VERSION ""

NS_ :

BS_:

BU_: ATCM_DMSM HCM_HS2 PAM_HS2 GSM GWM _delete SCCM OCS TSTR RCM

BO_ 2611175451 PARSEDPhysGSMtoGWM_ECG: 8 Vector__XXX
 SG_ PARSEDPhysGSMtoGWM_ECG : 7|29@0+ (1,0) [0|536870911] "Unitless"  GWM

BO_ 1844 TesterPhysicalReqHCM_HS2: 8 TSTR
 SG_ TesterPhysicalReqHCM : 7|64@0+ (1,0) [0|1.84467E+019] "unitless"  HCM_HS2

BO_ 1852 TesterPhysicalResHCM_HS2: 8 HCM_HS2
 SG_ TesterPhysicalResHCM : 7|64@0+ (1,0) [0|1.84467E+019] "unitless"  TSTR

BO_ 989 Personality_HCM_Data_HS2: 8 HCM_HS2
 SG_ FeatNoHcm_No_Actl : 23|16@0+ (1,0) [0|65535] "Number"  GWM
 SG_ FeatConfigHcmActl : 7|16@0+ (1,0) [0|65535] "Undefined"  GWM

BO_ 2612002008 PARSEDFuncGWM_ECG_HS2: 8 GWM
 SG_ PARSEDFuncGWM_ECG : 7|29@0+ (1,0) [0|536870911] "unitless" Vector__XXX

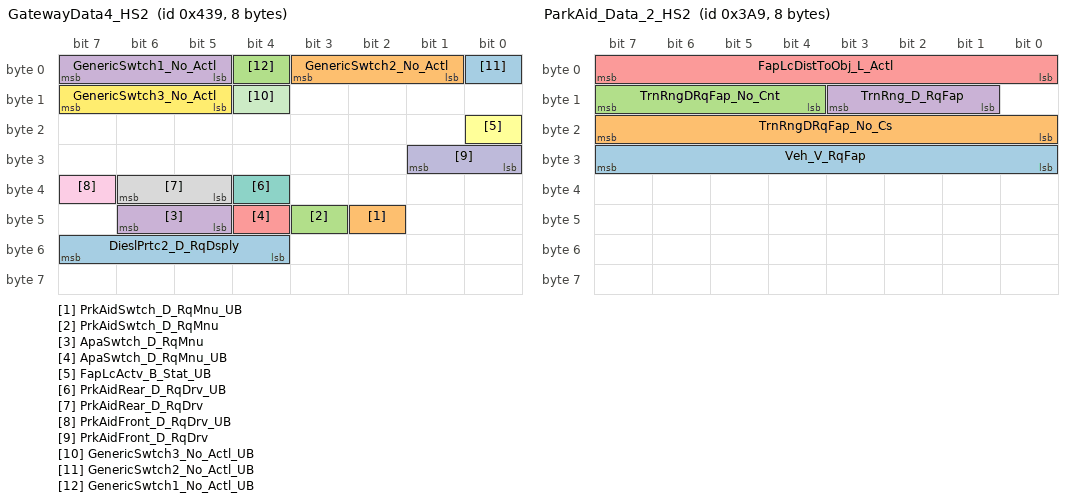
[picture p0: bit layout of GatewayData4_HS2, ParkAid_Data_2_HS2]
BO_ 1081 GatewayData4_HS2: 8 GWM
 SG_ DieslPrtc2_D_RqDsply : 55|4@0+ (1,0) [0|15] "SED" Vector__XXX
 SG_ PrkAidSwtch_D_RqMnu_UB : 42|1@0+ (1,0) [0|1] "SED"  PAM_HS2
 SG_ PrkAidSwtch_D_RqMnu : 43|1@0+ (1,0) [0|1] "SED"  PAM_HS2
 SG_ ApaSwtch_D_RqMnu : 46|2@0+ (1,0) [0|3] "SED" Vector__XXX
 SG_ ApaSwtch_D_RqMnu_UB : 44|1@0+ (1,0) [0|1] "SED" Vector__XXX
 SG_ FapLcActv_B_Stat_UB : 16|1@0+ (1,0) [0|1] "SED"  PAM_HS2
 SG_ PrkAidRear_D_RqDrv_UB : 36|1@0+ (1,0) [0|1] "SED"  PAM_HS2
 SG_ PrkAidRear_D_RqDrv : 38|2@0+ (1,0) [0|3] "SED"  PAM_HS2
 SG_ PrkAidFront_D_RqDrv_UB : 39|1@0+ (1,0) [0|1] "SED" Vector__XXX
 SG_ PrkAidFront_D_RqDrv : 25|2@0+ (1,0) [0|3] "SED" Vector__XXX
 SG_ GenericSwtch3_No_Actl_UB : 12|1@0+ (1,0) [0|1] "SED" Vector__XXX
 SG_ GenericSwtch3_No_Actl : 15|3@0+ (1,0) [0|7] "unitless" Vector__XXX
 SG_ GenericSwtch2_No_Actl_UB : 0|1@0+ (1,0) [0|1] "SED" Vector__XXX
 SG_ GenericSwtch2_No_Actl : 3|3@0+ (1,0) [0|7] "unitless" Vector__XXX
 SG_ GenericSwtch1_No_Actl_UB : 4|1@0+ (1,0) [0|1] "SED" Vector__XXX
 SG_ GenericSwtch1_No_Actl : 7|3@0+ (1,0) [0|7] "unitless" Vector__XXX

BO_ 937 ParkAid_Data_2_HS2: 8 PAM_HS2
 SG_ Veh_V_RqFap : 31|8@0+ (0.1,0) [0|25.5] "km/h"  GWM
 SG_ TrnRngDRqFap_No_Cs : 23|8@0+ (1,0) [0|255] "unitless"  GWM
 SG_ TrnRngDRqFap_No_Cnt : 15|4@0+ (1,0) [0|15] "unitless"  GWM
 SG_ TrnRng_D_RqFap : 11|3@0+ (1,0) [0|7] "SED"  GWM
 SG_ FapLcDistToObj_L_Actl : 7|8@0+ (0.01,0) [0|2.53] "meter"  GWM

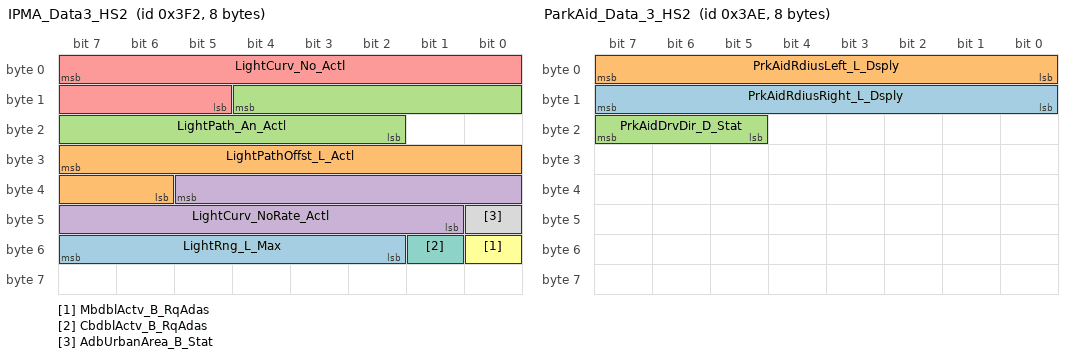
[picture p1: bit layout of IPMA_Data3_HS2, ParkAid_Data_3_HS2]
BO_ 1010 IPMA_Data3_HS2: 8 GWM
 SG_ LightRng_L_Max : 55|6@0+ (2,0) [0|126] "meter"  GWM,HCM_HS2
 SG_ LightPathOffst_L_Actl : 31|10@0+ (0.01,-5.12) [-5.12|5.11] "meter"  GWM,HCM_HS2
 SG_ LightPath_An_Actl : 12|11@0+ (0.0005,-0.5) [-0.5|0.5235] "radians"  GWM,HCM_HS2
 SG_ LightCurv_NoRate_Actl : 37|13@0+ (2.5E-007,-0.001024) [-0.001024|0.00102375] "1/meter"  GWM,HCM_HS2
 SG_ LightCurv_No_Actl : 7|11@0+ (2E-005,-0.02) [-0.02|0.02094] "1/meter"  GWM,HCM_HS2
 SG_ MbdblActv_B_RqAdas : 48|1@0+ (1,0) [0|1] "SED" Vector__XXX
 SG_ CbdblActv_B_RqAdas : 49|1@0+ (1,0) [0|1] "SED"  GWM,HCM_HS2
 SG_ AdbUrbanArea_B_Stat : 40|1@0+ (1,0) [0|1] "SED"  GWM,HCM_HS2

BO_ 2612224027 PARSEDPushGSMtoGWM_ECG: 8 Vector__XXX
 SG_ PARSEDPushGSMtoGWM_ECG : 7|29@0+ (1,0) [0|536870911] "unitless"  GWM

BO_ 2610953432 OTAFuncGWM_ECG_HS2: 8 GWM
 SG_ OTAFuncGWM_ECG : 7|29@0+ (1,0) [0|536870911] "unitless"  HCM_HS2,GSM

BO_ 2609933528 OTAPhysGWM_ECGtoGSM: 8 GWM
 SG_ OTAPhysGWM_ECGtoGSM : 7|29@0+ (1,0) [0|536870911] "unitless"  GSM

BO_ 2610126875 OTAPhysGSMtoGWM_ECG: 8 GSM
 SG_ OTAPhysGSMtoGWM_ECG : 7|29@0+ (1,0) [0|536870911] "unitless"  GWM

BO_ 1854 TesterPhysicalResPAM_HS2: 8 PAM_HS2
 SG_ TesterPhysicalResPAM : 7|64@0+ (1,0) [0|1.84467E+019] "unitless"  TSTR

BO_ 942 ParkAid_Data_3_HS2: 8 PAM_HS2
 SG_ PrkAidRdiusRight_L_Dsply : 15|8@0+ (1,0) [0|255] "unitless"  GWM
 SG_ PrkAidRdiusLeft_L_Dsply : 7|8@0+ (1,0) [0|255] "unitless"  GWM
 SG_ PrkAidDrvDir_D_Stat : 23|3@0+ (1,0) [0|7] "SED"  GWM

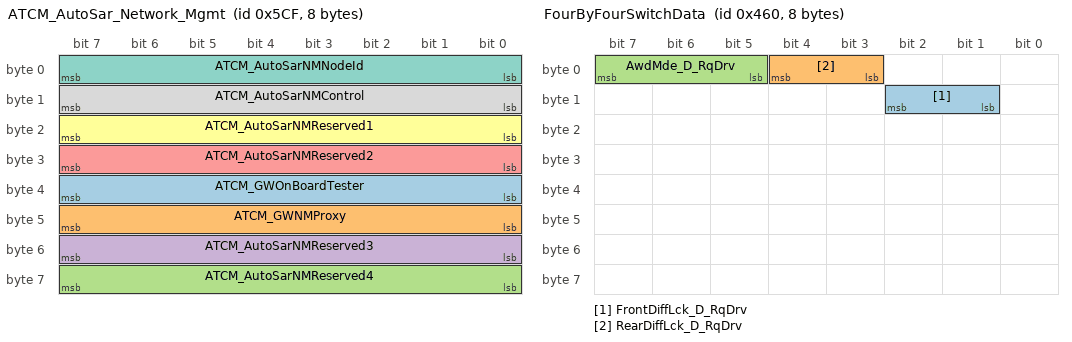
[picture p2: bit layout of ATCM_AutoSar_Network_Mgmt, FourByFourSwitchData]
BO_ 1487 ATCM_AutoSar_Network_Mgmt: 8 ATCM_DMSM
 SG_ ATCM_GWOnBoardTester : 39|8@0+ (1,0) [0|255] "unitless"  GWM
 SG_ ATCM_GWNMProxy : 47|8@0+ (1,0) [0|255] "unitless"  GWM
 SG_ ATCM_AutoSarNMReserved4 : 63|8@0+ (1,0) [0|255] "unitless"  GWM
 SG_ ATCM_AutoSarNMReserved3 : 55|8@0+ (1,0) [0|255] "unitless"  GWM
 SG_ ATCM_AutoSarNMReserved2 : 31|8@0+ (1,0) [0|255] "unitless"  GWM
 SG_ ATCM_AutoSarNMReserved1 : 23|8@0+ (1,0) [0|255] "unitless"  GWM
 SG_ ATCM_AutoSarNMNodeId : 7|8@0+ (1,0) [0|255] "unitless"  GWM
 SG_ ATCM_AutoSarNMControl : 15|8@0+ (1,0) [0|255] "unitless"  GWM

BO_ 1120 FourByFourSwitchData: 8 ATCM_DMSM
 SG_ FrontDiffLck_D_RqDrv : 10|2@0+ (1,0) [0|3] "SED"  GWM
 SG_ RearDiffLck_D_RqDrv : 4|2@0+ (1,0) [0|3] "SED"  GWM
 SG_ AwdMde_D_RqDrv : 7|3@0+ (1,0) [0|7] "SED"  GWM

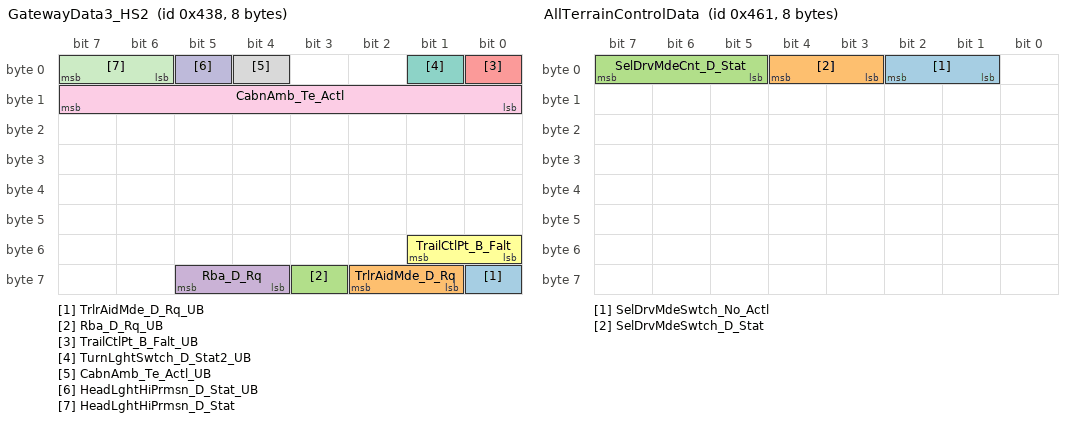
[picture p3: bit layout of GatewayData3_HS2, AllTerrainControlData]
BO_ 1080 GatewayData3_HS2: 8 GWM
 SG_ TrlrAidMde_D_Rq_UB : 56|1@0+ (1,0) [0|1] "SED" Vector__XXX
 SG_ TrlrAidMde_D_Rq : 58|2@0+ (1,0) [0|3] "SED" Vector__XXX
 SG_ Rba_D_Rq_UB : 59|1@0+ (1,0) [0|1] "SED" Vector__XXX
 SG_ Rba_D_Rq : 61|2@0+ (1,0) [0|3] "SED" Vector__XXX
 SG_ TrailCtlPt_B_Falt_UB : 0|1@0+ (1,0) [0|1] "SED" Vector__XXX
 SG_ TrailCtlPt_B_Falt : 49|2@0+ (1,0) [0|3] "SED" Vector__XXX
 SG_ TurnLghtSwtch_D_Stat2_UB : 1|1@0+ (1,0) [0|1] "SED" Vector__XXX
 SG_ CabnAmb_Te_Actl_UB : 4|1@0+ (1,0) [0|1] "SED"  SCCM
 SG_ CabnAmb_Te_Actl : 15|8@0+ (0.5,-57) [-57|70] "degreesC"  SCCM
 SG_ HeadLghtHiPrmsn_D_Stat_UB : 5|1@0+ (1,0) [0|1] "SED"  HCM_HS2,SCCM
 SG_ HeadLghtHiPrmsn_D_Stat : 7|2@0+ (1,0) [0|3] "SED"  HCM_HS2,SCCM

BO_ 1121 AllTerrainControlData: 8 ATCM_DMSM
 SG_ SelDrvMdeSwtch_No_Actl : 2|2@0+ (1,0) [0|3] "unitless"  GWM
 SG_ SelDrvMdeSwtch_D_Stat : 4|2@0+ (1,0) [0|3] "SED"  GWM
 SG_ SelDrvMdeCnt_D_Stat : 7|3@0+ (1,0) [0|7] "Counts"  GWM

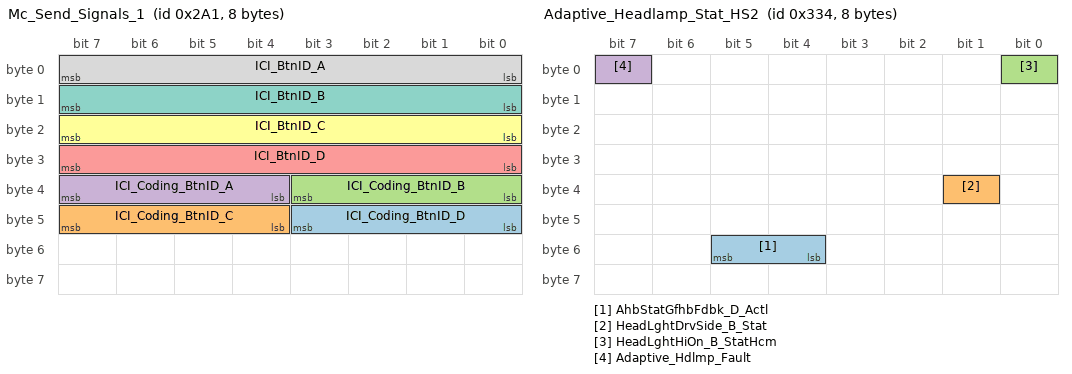
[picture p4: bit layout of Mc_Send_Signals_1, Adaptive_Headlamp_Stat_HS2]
BO_ 673 Mc_Send_Signals_1: 8 SCCM
 SG_ ICI_Coding_BtnID_D : 43|4@0+ (1,0) [0|15] "SED"  GWM
 SG_ ICI_Coding_BtnID_C : 47|4@0+ (1,0) [0|15] "SED"  GWM
 SG_ ICI_Coding_BtnID_B : 35|4@0+ (1,0) [0|15] "SED"  GWM
 SG_ ICI_Coding_BtnID_A : 39|4@0+ (1,0) [0|15] "SED"  GWM
 SG_ ICI_BtnID_D : 31|8@0+ (1,0) [0|255] "unitless"  GWM
 SG_ ICI_BtnID_C : 23|8@0+ (1,0) [0|255] "unitless"  GWM
 SG_ ICI_BtnID_B : 15|8@0+ (1,0) [0|255] "unitless"  GWM
 SG_ ICI_BtnID_A : 7|8@0+ (1,0) [0|255] "unitless"  GWM

BO_ 820 Adaptive_Headlamp_Stat_HS2: 8 HCM_HS2
 SG_ AhbStatGfhbFdbk_D_Actl : 53|2@0+ (1,0) [0|3] "SED"  GWM,SCCM
 SG_ HeadLghtDrvSide_B_Stat : 33|1@0+ (1,0) [0|1] "SED"  GWM
 SG_ HeadLghtHiOn_B_StatHcm : 0|1@0+ (1,0) [0|1] "SED"  GWM
 SG_ Adaptive_Hdlmp_Fault : 7|1@0+ (1,0) [0|1] "SED"  GWM

BO_ 1073 BodyEngGateway_2_HS2: 8 GWM
 SG_ CamraFrntBttn_D_Stat : 48|1@0+ (1,0) [0|1] "SED" Vector__XXX
 SG_ CamraFrntBttn_D_Stat_UB : 60|1@0+ (1,0) [0|1] "SED" Vector__XXX
 SG_ BrkDrvMde_D_Rq_UB : 49|1@0+ (1,0) [0|1] "SED" Vector__XXX
 SG_ BrkDrvMde_D_Rq : 63|3@0+ (1,0) [0|7] "SED" Vector__XXX
 SG_ SteEffort_D_Rq : 52|3@0+ (1,0) [0|7] "SED" Vector__XXX
 SG_ AutoHoldSwtch_D_Stat_UB : 57|1@0+ (1,0) [0|1] "SED" Vector__XXX
 SG_ AutoHoldSwtch_D_Stat : 59|2@0+ (1,0) [0|3] "SED" Vector__XXX
 SG_ HMI_HMIMode_St_UB : 41|1@0+ (1,0) [0|1] "SED"  SCCM
 SG_ HMI_HMIMode_St : 55|3@0+ (1,0) [0|7] "SED"  SCCM
 SG_ Veh_Lock_Requestor_UB : 47|1@0+ (1,0) [0|1] "SED"  GSM
 SG_ Veh_Lock_EvNum_UB : 32|1@0+ (1,0) [0|1] "SED"  GSM
 SG_ Veh_Lock_Sub_Id_UB : 33|1@0+ (1,0) [0|1] "SED" Vector__XXX
 SG_ Tire_Press_System_Stat_UB : 34|1@0+ (1,0) [0|1] "SED" Vector__XXX
 SG_ Veh_Lock_Status_UB : 8|1@0+ (1,0) [0|1] "SED"  GSM
 SG_ Veh_Lock_Sub_Id : 19|4@0+ (1,0) [0|15] "SED" Vector__XXX
 SG_ Veh_Lock_Status : 10|2@0+ (1,0) [0|3] "SED"  GSM
 SG_ Veh_Lock_Requestor : 39|5@0+ (1,0) [0|31] "SED"  GSM
 SG_ Veh_Lock_EvNum : 31|8@0+ (1,0) [0|255] "unitless"  GSM
 SG_ Tire_Press_System_Stat : 23|4@0+ (1,0) [0|15] "SED" Vector__XXX
 SG_ DISPLAY_SPEED_OFFSET_UB : 0|1@0+ (1,0) [0|1] "SED" Vector__XXX
 SG_ DISPLAY_SPEED_OFFSET : 3|3@0+ (0.5,0) [0|3.5] "kph" Vector__XXX
 SG_ DISPLAY_SPEED_SCALING_UB : 11|1@0+ (1,0) [0|1] "SED" Vector__XXX
 SG_ DISPLAY_SPEED_SCALING : 15|4@0+ (0.5,100) [100|107.5] "%" Vector__XXX
 SG_ SteWhlHeat_D_Rq_UB : 42|1@0+ (1,0) [0|1] "SED"  SCCM
 SG_ SteWhlHeat_D_Rq : 46|4@0+ (1,0) [0|15] "SED"  SCCM

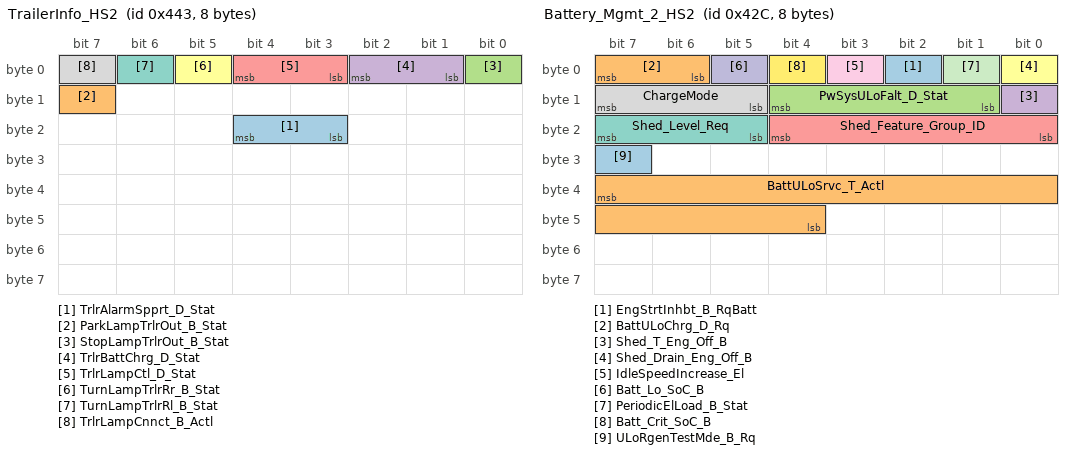
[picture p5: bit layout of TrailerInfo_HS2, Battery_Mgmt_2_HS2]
BO_ 1091 TrailerInfo_HS2: 8 GWM
 SG_ TrlrAlarmSpprt_D_Stat : 20|2@0+ (1,0) [0|3] "SED" Vector__XXX
 SG_ ParkLampTrlrOut_B_Stat : 15|1@0+ (1,0) [0|1] "SED" Vector__XXX
 SG_ StopLampTrlrOut_B_Stat : 0|1@0+ (1,0) [0|1] "SED" Vector__XXX
 SG_ TrlrBattChrg_D_Stat : 2|2@0+ (1,0) [0|3] "SED" Vector__XXX
 SG_ TrlrLampCtl_D_Stat : 4|2@0+ (1,0) [0|3] "SED" Vector__XXX
 SG_ TurnLampTrlrRr_B_Stat : 5|1@0+ (1,0) [0|1] "SED" Vector__XXX
 SG_ TurnLampTrlrRl_B_Stat : 6|1@0+ (1,0) [0|1] "SED" Vector__XXX
 SG_ TrlrLampCnnct_B_Actl : 7|1@0+ (1,0) [0|1] "SED"  SCCM,PAM_HS2

BO_ 1068 Battery_Mgmt_2_HS2: 8 GWM
 SG_ EngStrtInhbt_B_RqBatt : 2|1@0+ (1,0) [0|1] "SED" Vector__XXX
 SG_ BattULoChrg_D_Rq : 7|2@0+ (1,0) [0|3] "SED" Vector__XXX
 SG_ PwSysULoFalt_D_Stat : 12|4@0+ (1,0) [0|15] "SED" Vector__XXX
 SG_ Shed_T_Eng_Off_B : 8|1@0+ (1,0) [0|1] "SED"  SCCM
 SG_ Shed_Feature_Group_ID : 20|5@0+ (1,0) [0|31] "SED"  SCCM,PAM_HS2
 SG_ Shed_Drain_Eng_Off_B : 0|1@0+ (1,0) [0|1] "SED"  SCCM
 SG_ Shed_Level_Req : 23|3@0+ (1,0) [0|7] "SED"  PAM_HS2,GSM,SCCM
 SG_ ChargeMode : 15|3@0+ (1,0) [0|7] "SED" Vector__XXX
 SG_ IdleSpeedIncrease_El : 3|1@0+ (1,0) [0|1] "SED" Vector__XXX
 SG_ Batt_Lo_SoC_B : 5|1@0+ (1,0) [0|1] "SED" Vector__XXX
 SG_ PeriodicElLoad_B_Stat : 1|1@0+ (1,0) [0|1] "SED" Vector__XXX
 SG_ Batt_Crit_SoC_B : 4|1@0+ (1,0) [0|1] "SED"  GSM
 SG_ ULoRgenTestMde_B_Rq : 31|1@0+ (1,0) [0|1] "SED" Vector__XXX
 SG_ BattULoSrvc_T_Actl : 39|12@0+ (1,0) [0|4095] "days" Vector__XXX

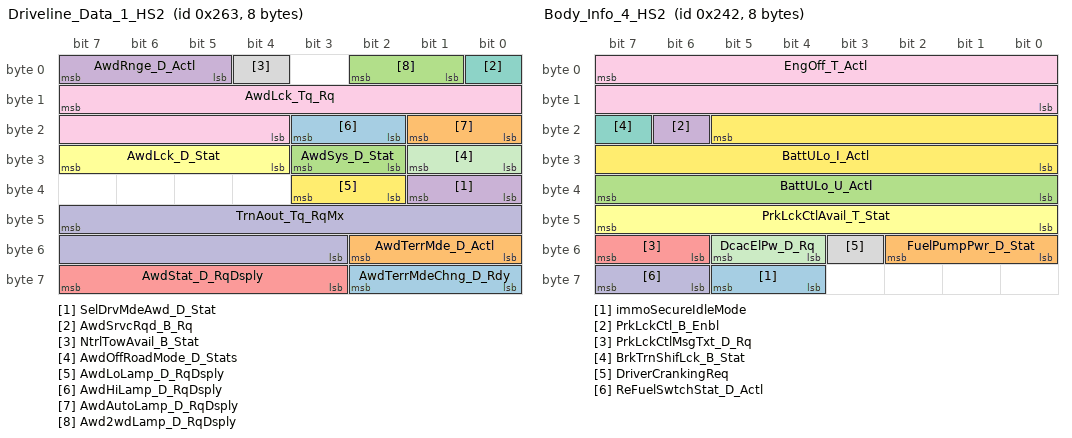
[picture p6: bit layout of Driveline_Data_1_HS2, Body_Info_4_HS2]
BO_ 611 Driveline_Data_1_HS2: 8 GWM
 SG_ AwdTerrMdeChng_D_Rdy : 58|3@0+ (1,0) [0|7] "SED" Vector__XXX
 SG_ AwdTerrMde_D_Actl : 50|3@0+ (1,0) [0|7] "SED" Vector__XXX
 SG_ AwdSys_D_Stat : 27|2@0+ (1,0) [0|3] "SED" Vector__XXX
 SG_ SelDrvMdeAwd_D_Stat : 33|2@0+ (1,0) [0|3] "SED" Vector__XXX
 SG_ AwdStat_D_RqDsply : 63|5@0+ (1,0) [0|31] "SED" Vector__XXX
 SG_ AwdLck_D_Stat : 31|4@0+ (1,0) [0|15] "SED" Vector__XXX
 SG_ AwdSrvcRqd_B_Rq : 0|1@0+ (1,0) [0|1] "SED"  RCM
 SG_ NtrlTowAvail_B_Stat : 4|1@0+ (1,0) [0|1] "SED" Vector__XXX
 SG_ AwdLck_Tq_Rq : 15|12@0+ (1,0) [0|4093] "Nm" Vector__XXX
 SG_ TrnAout_Tq_RqMx : 47|13@0+ (1,-1250) [-1250|6941] "Nm" Vector__XXX
 SG_ AwdOffRoadMode_D_Stats : 25|2@0+ (1,0) [0|3] "SED" Vector__XXX
 SG_ AwdLoLamp_D_RqDsply : 35|2@0+ (1,0) [0|3] "SED"  ATCM_DMSM
 SG_ AwdHiLamp_D_RqDsply : 19|2@0+ (1,0) [0|3] "SED"  ATCM_DMSM
 SG_ AwdAutoLamp_D_RqDsply : 17|2@0+ (1,0) [0|3] "SED"  ATCM_DMSM
 SG_ Awd2wdLamp_D_RqDsply : 2|2@0+ (1,0) [0|3] "SED"  ATCM_DMSM
 SG_ AwdRnge_D_Actl : 7|3@0+ (1,0) [0|7] "SED" Vector__XXX

BO_ 578 Body_Info_4_HS2: 8 GWM
 SG_ immoSecureIdleMode : 61|2@0+ (1,0) [0|3] "SED"  GSM
 SG_ FuelPumpPwr_D_Stat : 50|3@0+ (1,0) [0|7] "SED" Vector__XXX
 SG_ BattULo_U_Actl : 39|8@0+ (0.0625,0) [0|15.875] "volt" Vector__XXX
 SG_ PrkLckCtl_B_Enbl : 22|1@0+ (1,0) [0|1] "SED"  GSM
 SG_ PrkLckCtlMsgTxt_D_Rq : 55|2@0+ (1,0) [0|3] "SED" Vector__XXX
 SG_ PrkLckCtlAvail_T_Stat : 47|8@0+ (1,0) [0|255] "second" Vector__XXX
 SG_ BrkTrnShifLck_B_Stat : 23|1@0+ (1,0) [0|1] "SED"  GSM
 SG_ DriverCrankingReq : 51|1@0+ (1,0) [0|1] "SED"  GSM
 SG_ EngOff_T_Actl : 7|16@0+ (1,0) [0|65534] "second^0.5" Vector__XXX
 SG_ ReFuelSwtchStat_D_Actl : 63|2@0+ (1,0) [0|3] "SED" Vector__XXX
 SG_ DcacElPw_D_Rq : 53|2@0+ (1,0) [0|3] "SED" Vector__XXX
 SG_ BattULo_I_Actl : 21|14@0+ (0.0625,-512) [-512|511.875] "ampere" Vector__XXX

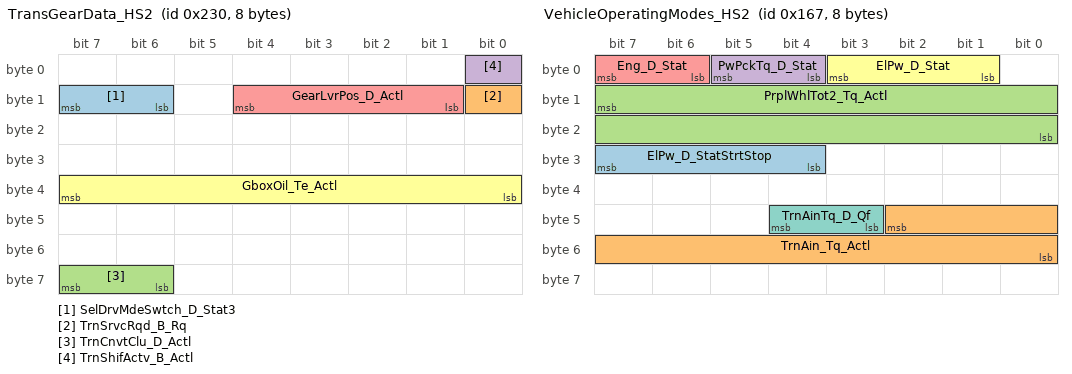
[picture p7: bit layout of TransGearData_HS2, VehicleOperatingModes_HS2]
BO_ 560 TransGearData_HS2: 8 GWM
 SG_ SelDrvMdeSwtch_D_Stat3 : 15|2@0+ (1,0) [0|3] "SED" Vector__XXX
 SG_ TrnSrvcRqd_B_Rq : 8|1@0+ (1,0) [0|1] "SED"  RCM
 SG_ TrnCnvtClu_D_Actl : 63|2@0+ (1,0) [0|3] "SED" Vector__XXX
 SG_ TrnShifActv_B_Actl : 0|1@0+ (1,0) [0|1] "SED" Vector__XXX
 SG_ GearLvrPos_D_Actl : 12|4@0+ (1,0) [0|15] "SED"  HCM_HS2,SCCM,RCM,GSM
 SG_ GboxOil_Te_Actl : 39|8@0+ (1,-60) [-60|193] "degC" Vector__XXX

BO_ 359 VehicleOperatingModes_HS2: 8 GWM
 SG_ ElPw_D_StatStrtStop : 31|4@0+ (1,0) [0|15] "SED"  GSM,SCCM
 SG_ TrnAin_Tq_Actl : 42|11@0+ (1,-500) [-500|1547] "Nm" Vector__XXX
 SG_ PrplWhlTot2_Tq_Actl : 15|16@0+ (4,-131072) [-131072|131060] "Nm"  RCM
 SG_ PwPckTq_D_Stat : 5|2@0+ (1,0) [0|3] "SED"  HCM_HS2,PAM_HS2,SCCM,OCS,GSM
 SG_ Eng_D_Stat : 7|2@0+ (1,0) [0|3] "SED" Vector__XXX
 SG_ ElPw_D_Stat : 3|3@0+ (1,0) [0|7] "SED"  HCM_HS2,PAM_HS2,GSM,OCS,SCCM
 SG_ TrnAinTq_D_Qf : 44|2@0+ (1,0) [0|3] "SED" Vector__XXX

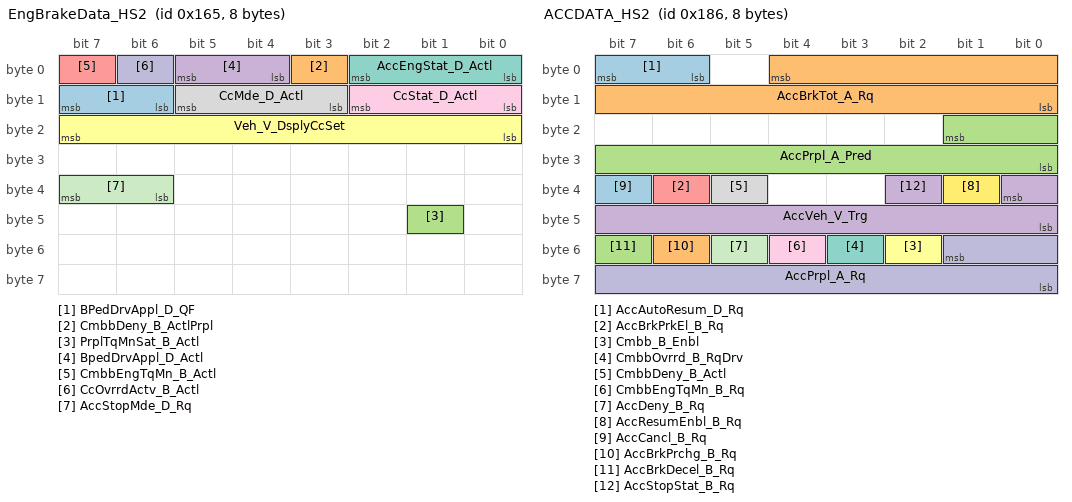
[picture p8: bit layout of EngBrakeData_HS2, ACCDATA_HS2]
BO_ 357 EngBrakeData_HS2: 8 GWM
 SG_ BPedDrvAppl_D_QF : 15|2@0+ (1,0) [0|3] "SED"  OCS,GSM,RCM
 SG_ CmbbDeny_B_ActlPrpl : 3|1@0+ (1,0) [0|1] "SED" Vector__XXX
 SG_ PrplTqMnSat_B_Actl : 41|1@0+ (1,0) [0|1] "SED" Vector__XXX
 SG_ BpedDrvAppl_D_Actl : 5|2@0+ (1,0) [0|3] "SED"  OCS,GSM,RCM
 SG_ CmbbEngTqMn_B_Actl : 7|1@0+ (1,0) [0|1] "SED" Vector__XXX
 SG_ Veh_V_DsplyCcSet : 23|8@0+ (1,0) [0|253] "Unitless" Vector__XXX
 SG_ AccEngStat_D_Actl : 2|3@0+ (1,0) [0|7] "SED" Vector__XXX
 SG_ CcMde_D_Actl : 13|3@0+ (1,0) [0|7] "SED" Vector__XXX
 SG_ CcStat_D_Actl : 10|3@0+ (1,0) [0|7] "SED"  OCS,RCM
 SG_ CcOvrrdActv_B_Actl : 6|1@0+ (1,0) [0|1] "SED"  RCM
 SG_ AccStopMde_D_Rq : 39|2@0+ (1,0) [0|3] "SED" Vector__XXX

BO_ 390 ACCDATA_HS2: 8 GWM
 SG_ AccAutoResum_D_Rq : 7|2@0+ (1,0) [0|3] "SED"  GWM
 SG_ AccBrkTot_A_Rq : 4|13@0+ (0.0039,-20) [-20|11.9449] "m/s^2"  GWM
 SG_ AccPrpl_A_Pred : 17|10@0+ (0.01,-5) [-5|5.23] "m/s^2"  GWM
 SG_ AccVeh_V_Trg : 32|9@0+ (0.5,0) [0|255.5] "kph"  GWM
 SG_ AccBrkPrkEl_B_Rq : 38|1@0+ (1,0) [0|1] "SED"  GWM
 SG_ Cmbb_B_Enbl : 50|1@0+ (1,0) [0|1] "SED"  GWM,RCM
 SG_ CmbbOvrrd_B_RqDrv : 51|1@0+ (1,0) [0|1] "SED"  GWM,RCM
 SG_ CmbbDeny_B_Actl : 37|1@0+ (1,0) [0|1] "SED"  GWM,RCM
 SG_ CmbbEngTqMn_B_Rq : 52|1@0+ (1,0) [0|1] "SED"  GWM
 SG_ AccPrpl_A_Rq : 49|10@0+ (0.01,-5) [-5|5.23] "m/s^2"  GWM
 SG_ AccDeny_B_Rq : 53|1@0+ (1,0) [0|1] "SED"  GWM
 SG_ AccResumEnbl_B_Rq : 33|1@0+ (1,0) [0|1] "SED"  GWM
 SG_ AccCancl_B_Rq : 39|1@0+ (1,0) [0|1] "SED"  GWM
 SG_ AccBrkPrchg_B_Rq : 54|1@0+ (1,0) [0|1] "SED"  GWM
 SG_ AccBrkDecel_B_Rq : 55|1@0+ (1,0) [0|1] "SED"  GWM
 SG_ AccStopStat_B_Rq : 34|1@0+ (1,0) [0|1] "SED"  GWM

BO_ 1071 Engine_Clutch_Data_HS2: 8 GWM
 SG_ CluPdlPosPcMeas_D_Qf : 11|2@0+ (1,0) [0|3] "SED"  HCM_HS2
 SG_ CluPdlPos_Pc_Meas : 9|10@0+ (0.1,0) [0|102.3] "%"  HCM_HS2

BO_ 1072 Cluster_Info1_HS2: 8 GWM
 SG_ HdcOn_B_Rq_UB : 55|1@0+ (1,0) [0|1] "SED" Vector__XXX
 SG_ TrlrAidCancl_B_Rq_UB : 56|1@0+ (1,0) [0|1] "SED" Vector__XXX
 SG_ TrlrAidCancl_B_Rq : 57|1@0+ (1,0) [0|1] "SED" Vector__XXX
 SG_ HdcOn_B_Rq : 39|1@0+ (1,0) [0|1] "SED" Vector__XXX
 SG_ HsaMde_D_Rq : 51|2@0+ (1,0) [0|3] "SED" Vector__XXX
 SG_ HsaMde_D_Rq_UB : 49|1@0+ (1,0) [0|1] "SED" Vector__XXX
 SG_ LscmbbStat_B_Actl : 53|1@0+ (1,0) [0|1] "SED" Vector__XXX
 SG_ LscmbbStat_B_Actl_UB : 52|1@0+ (1,0) [0|1] "SED" Vector__XXX
 SG_ Outside_Air_Temp_Stat_UB : 3|1@0+ (1,0) [0|1] "SED"  PAM_HS2
 SG_ Outside_Air_Temp_Stat : 47|8@0+ (0.5,-40) [-40|86.5] "Degrees C"  PAM_HS2
 SG_ BulbChkActv_B_Stat_UB : 5|1@0+ (1,0) [0|1] "SED" Vector__XXX
 SG_ BulbChkActv_B_Stat : 6|1@0+ (1,0) [0|1] "SED" Vector__XXX
 SG_ Fda_B_Stat_UB : 4|1@0+ (1,0) [0|1] "SED" Vector__XXX
 SG_ AccEnbl_B_RqDrv_UB : 2|1@0+ (1,0) [0|1] "SED" Vector__XXX
 SG_ AccDeny_B_RqIpc_UB : 1|1@0+ (1,0) [0|1] "SED" Vector__XXX
 SG_ OdometerMasterValue_UB : 0|1@0+ (1,0) [0|1] "SED" Vector__XXX
 SG_ OdometerMasterValue : 15|24@0+ (1,0) [0|16777214] "km"  RCM
 SG_ Fda_B_Stat : 36|1@0+ (1,0) [0|1] "SED" Vector__XXX
 SG_ AccDeny_B_RqIpc : 7|1@0+ (1,0) [0|1] "SED" Vector__XXX
 SG_ AccEnbl_B_RqDrv : 35|1@0+ (1,0) [0|1] "SED" Vector__XXX
 SG_ DrvSlipCtlMde_D_Rq_UB : 38|1@0+ (1,0) [0|1] "SED" Vector__XXX
 SG_ DrvSlipCtlMde_D_Rq : 33|2@0+ (1,0) [0|3] "SED" Vector__XXX
 SG_ DrvSlipCtlMde_B_Rq_UB : 37|1@0+ (1,0) [0|1] "SED" Vector__XXX
 SG_ ePRNDL_MODE_UB : 48|1@0+ (1,0) [0|1] "SED"  GSM
 SG_ ePRNDL_MODE : 54|1@0+ (1,0) [0|1] "SED"  GSM
 SG_ TrlrBrkMde_D_Rq : 63|1@0+ (1,0) [0|1] "SED" Vector__XXX
 SG_ TRLR_SWAY_CONFIG_CMD : 62|1@0+ (1,0) [0|1] "SED" Vector__XXX
 SG_ TRAILER_BRAKE_CONFIG : 61|1@0+ (1,0) [0|1] "SED" Vector__XXX
 SG_ TrlrBrkMde_D_Rq_UB : 60|1@0+ (1,0) [0|1] "SED" Vector__XXX
 SG_ TRAILER_BRAKE_CONFIG_UB : 58|1@0+ (1,0) [0|1] "SED" Vector__XXX

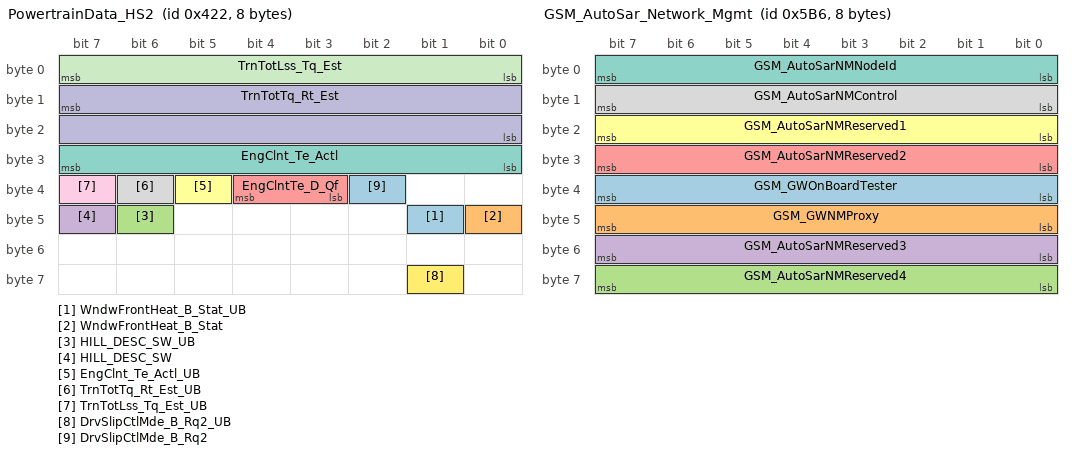
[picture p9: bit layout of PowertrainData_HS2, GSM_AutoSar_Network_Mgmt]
BO_ 1058 PowertrainData_HS2: 8 GWM
 SG_ WndwFrontHeat_B_Stat_UB : 41|1@0+ (1,0) [0|1] "SED" Vector__XXX
 SG_ WndwFrontHeat_B_Stat : 40|1@0+ (1,0) [0|1] "SED" Vector__XXX
 SG_ HILL_DESC_SW_UB : 46|1@0+ (1,0) [0|1] "SED" Vector__XXX
 SG_ HILL_DESC_SW : 47|1@0+ (1,0) [0|1] "SED" Vector__XXX
 SG_ EngClntTe_D_Qf : 36|2@0+ (1,0) [0|3] "SED" Vector__XXX
 SG_ EngClnt_Te_Actl_UB : 37|1@0+ (1,0) [0|1] "SED" Vector__XXX
 SG_ EngClnt_Te_Actl : 31|8@0+ (1,-60) [-60|195] "degC"  GSM
 SG_ TrnTotTq_Rt_Est_UB : 38|1@0+ (1,0) [0|1] "SED" Vector__XXX
 SG_ TrnTotLss_Tq_Est_UB : 39|1@0+ (1,0) [0|1] "SED" Vector__XXX
 SG_ TrnTotTq_Rt_Est : 15|16@0+ (0.001,0) [0|65.533] "Unitless" Vector__XXX
 SG_ TrnTotLss_Tq_Est : 7|8@0+ (0.5,0) [0|126.5] "Nm" Vector__XXX
 SG_ DrvSlipCtlMde_B_Rq2_UB : 57|1@0+ (1,0) [0|1] "SED" Vector__XXX
 SG_ DrvSlipCtlMde_B_Rq2 : 34|1@0+ (1,0) [0|1] "SED" Vector__XXX

BO_ 1082 GatewayData_HS2: 8 GWM
 SG_ EsaOn_B_Rq_UB : 33|1@0+ (1,0) [0|1] "SED" Vector__XXX
 SG_ EsaOn_B_Rq : 34|1@0+ (1,0) [0|1] "SED" Vector__XXX
 SG_ RearDiffLck_D_RqArb_UB : 35|1@0+ (1,0) [0|1] "SED" Vector__XXX
 SG_ RearDiffLck_D_RqArb : 25|2@0+ (1,0) [0|3] "SED" Vector__XXX
 SG_ AwdMde_D_RqArb_UB : 36|1@0+ (1,0) [0|1] "SED" Vector__XXX
 SG_ AwdMde_D_RqArb : 39|3@0+ (1,0) [0|7] "SED" Vector__XXX
 SG_ SelDrvMdeTxtReset_B_Rq_UB : 43|1@0+ (1,0) [0|1] "SED" Vector__XXX
 SG_ SelDrvMdeTxtReset_B_Rq : 44|1@0+ (1,0) [0|1] "SED" Vector__XXX
 SG_ SelDrvMdeDsply_B_Avail_UB : 50|1@0+ (1,0) [0|1] "SED" Vector__XXX
 SG_ AirSusp_D_RqDrv_UB : 16|1@0+ (1,0) [0|1] "SED" Vector__XXX
 SG_ DrvInputRequired_B_Rq_UB : 52|1@0+ (1,0) [0|1] "SED"  SCCM
 SG_ DrvInputRequired_B_Rq : 32|1@0+ (1,0) [0|1] "SED"  SCCM
 SG_ SelDrvMdeSwtch_D_Stat2_UB : 45|1@0+ (1,0) [0|1] "SED" Vector__XXX
 SG_ SelDrvMdeSwtch_D_Stat2 : 47|2@0+ (1,0) [0|3] "SED" Vector__XXX
 SG_ FapLcStopHold_B_Rq : 57|1@0+ (1,0) [0|1] "SED" Vector__XXX
 SG_ SelDrvMdeDsply_B_Avail : 51|1@0+ (1,0) [0|1] "SED" Vector__XXX
 SG_ FapLcStopHold_B_Rq_UB : 56|1@0+ (1,0) [0|1] "SED" Vector__XXX
 SG_ FapLcPrchgBrk_B_Rq_UB : 58|1@0+ (1,0) [0|1] "SED" Vector__XXX
 SG_ AirSusp_D_RqDrv : 31|2@0+ (1,0) [0|3] "SED" Vector__XXX
 SG_ AwdRnge_D_ActlIpc_UB : 26|1@0+ (1,0) [0|1] "SED" Vector__XXX
 SG_ AwdRnge_D_ActlIpc : 29|3@0+ (1,0) [0|7] "SED" Vector__XXX
 SG_ NtrlTowMdeEnbl_B_RqDrv_UB : 60|1@0+ (1,0) [0|1] "SED" Vector__XXX
 SG_ NtrlTowMdeEnbl_B_RqDrv : 48|1@0+ (1,0) [0|1] "SED" Vector__XXX
 SG_ DrvSlipCtlMde_B_RqMyKey_UB : 17|1@0+ (1,0) [0|1] "SED" Vector__XXX
 SG_ DrvSlipCtlMde_B_RqMyKey : 18|1@0+ (1,0) [0|1] "SED" Vector__XXX
 SG_ AwdDrvMde_D_Rq_UB : 49|1@0+ (1,0) [0|1] "SED" Vector__XXX
 SG_ AwdDrvMde_D_Rq : 63|3@0+ (1,0) [0|7] "SED" Vector__XXX
 SG_ MetricActv_B_Actl_UB : 53|1@0+ (1,0) [0|1] "SED" Vector__XXX
 SG_ MetricActv_B_Actl : 54|1@0+ (1,0) [0|1] "SED" Vector__XXX
 SG_ BrkLineLck_D_Rq_UB : 5|1@0+ (1,0) [0|1] "SED" Vector__XXX
 SG_ BrkLineLck_D_Rq : 7|2@0+ (1,0) [0|3] "SED" Vector__XXX
 SG_ SuspDrvMde_D_Rq_UB : 19|1@0+ (1,0) [0|1] "SED" Vector__XXX
 SG_ SuspDrvMde_D_Rq : 22|3@0+ (1,0) [0|7] "SED" Vector__XXX
 SG_ SelDrvMdePt_D_Stat_UB : 55|1@0+ (1,0) [0|1] "SED" Vector__XXX
 SG_ SelDrvMdePt_D_Stat : 41|2@0+ (1,0) [0|3] "SED" Vector__XXX

BO_ 1462 GSM_AutoSar_Network_Mgmt: 8 GSM
 SG_ GSM_GWOnBoardTester : 39|8@0+ (1,0) [0|255] "unitless"  SCCM,GWM
 SG_ GSM_GWNMProxy : 47|8@0+ (1,0) [0|255] "unitless"  SCCM,GWM
 SG_ GSM_AutoSarNMReserved4 : 63|8@0+ (1,0) [0|255] "unitless"  SCCM,GWM
 SG_ GSM_AutoSarNMReserved3 : 55|8@0+ (1,0) [0|255] "unitless"  SCCM,GWM
 SG_ GSM_AutoSarNMReserved2 : 31|8@0+ (1,0) [0|255] "unitless"  SCCM,GWM
 SG_ GSM_AutoSarNMReserved1 : 23|8@0+ (1,0) [0|255] "unitless"  SCCM,GWM
 SG_ GSM_AutoSarNMNodeId : 7|8@0+ (1,0) [0|255] "unitless"  SCCM,GWM
 SG_ GSM_AutoSarNMControl : 15|8@0+ (1,0) [0|255] "unitless"  SCCM,GWM

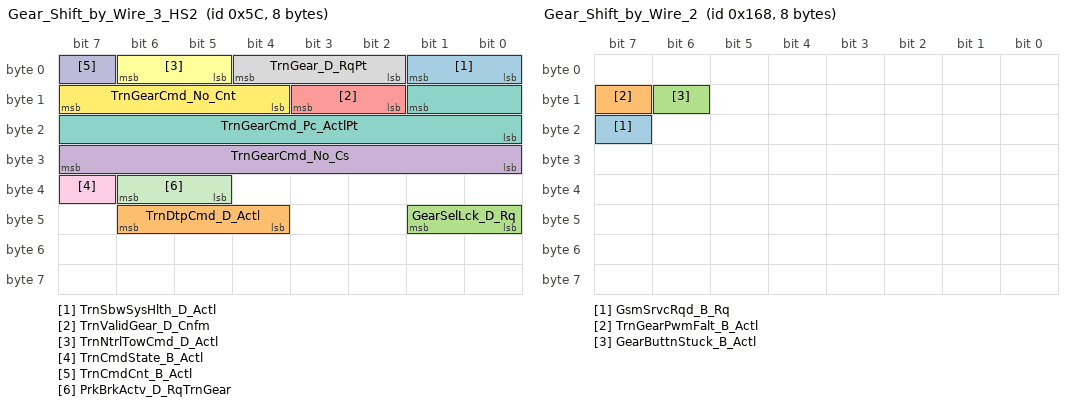
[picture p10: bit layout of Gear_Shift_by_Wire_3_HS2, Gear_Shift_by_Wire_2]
BO_ 92 Gear_Shift_by_Wire_3_HS2: 8 GWM
 SG_ TrnSbwSysHlth_D_Actl : 1|2@0+ (1,0) [0|3] "SED"  GSM
 SG_ TrnDtpCmd_D_Actl : 46|3@0+ (1,0) [0|7] "SED"  GSM
 SG_ GearSelLck_D_Rq : 41|2@0+ (1,0) [0|3] "SED"  GSM
 SG_ TrnGearCmd_No_Cs : 31|8@0+ (1,0) [0|255] "Unitless"  GSM
 SG_ TrnValidGear_D_Cnfm : 11|2@0+ (1,0) [0|3] "SED"  GSM
 SG_ TrnNtrlTowCmd_D_Actl : 6|2@0+ (1,0) [0|3] "SED"  GSM
 SG_ TrnGearCmd_Pc_ActlPt : 9|10@0+ (0.1,0) [0|102.2] "percent duty cycle"  GSM
 SG_ TrnGear_D_RqPt : 4|3@0+ (1,0) [0|7] "SED"  GSM
 SG_ TrnCmdState_B_Actl : 39|1@0+ (1,0) [0|1] "SED"  GSM
 SG_ TrnCmdCnt_B_Actl : 7|1@0+ (1,0) [0|1] "unitless"  GSM
 SG_ PrkBrkActv_D_RqTrnGear : 38|2@0+ (1,0) [0|3] "SED"  GSM
 SG_ TrnGearCmd_No_Cnt : 15|4@0+ (1,0) [0|15] "Unitless"  GSM

BO_ 360 Gear_Shift_by_Wire_2: 8 GSM
 SG_ GsmSrvcRqd_B_Rq : 23|1@0+ (1,0) [0|1] "SED"  GWM
 SG_ TrnGearPwmFalt_B_Actl : 15|1@0+ (1,0) [0|1] "SED"  GWM
 SG_ GearButtnStuck_B_Actl : 14|1@0+ (1,0) [0|1] "SED"  GWM

BO_ 90 Gear_Shift_by_Wire: 8 GSM
 SG_ TrnGsmNtmState_D_Actl : 55|2@0+ (1,0) [0|3] "SED"  GWM
 SG_ DrQltyDrv_D_StatGsm : 42|3@0+ (1,0) [0|7] "SED"  GWM
 SG_ TrnBtsiOvrrd_B_Stat : 43|1@0+ (1,0) [0|1] "SED"  GWM
 SG_ GsmGearMsgTxt_D_Rq : 63|2@0+ (1,0) [0|3] "SED"  GWM
 SG_ TrnRng_D_RqGsm : 51|4@0+ (1,0) [0|15] "SED"  GWM
 SG_ PrkBrkActv_D_RqGsmGear : 53|2@0+ (1,0) [0|3] "SED"  GWM
 SG_ TrnValidGearRq_D_Stat : 25|2@0+ (1,0) [0|3] "SED"  GWM
 SG_ TrnGearRqCnt_B_Actl : 26|1@0+ (1,0) [0|1] "unitless"  GWM
 SG_ TrnGearButtn_U_Actl : 23|8@0+ (0.05,0) [0|12.7] "VOLT"  GWM
 SG_ TrnGearButtn_B_ActlR2 : 8|1@0+ (1,0) [0|1] "SED"  GWM
 SG_ TrnGearButtn_B_ActlR1 : 9|1@0+ (1,0) [0|1] "SED"  GWM
 SG_ TrnGearButtn_B_ActlR0 : 10|1@0+ (1,0) [0|1] "SED"  GWM
 SG_ TrnGearButtn_B_ActlP2 : 11|1@0+ (1,0) [0|1] "SED"  GWM
 SG_ TrnGearButtn_B_ActlP1 : 12|1@0+ (1,0) [0|1] "SED"  GWM
 SG_ TrnGearButtn_B_ActlP0 : 13|1@0+ (1,0) [0|1] "SED"  GWM
 SG_ TrnGearButtn_B_ActlN2 : 14|1@0+ (1,0) [0|1] "SED"  GWM
 SG_ TrnGearButtn_B_ActlN1 : 15|1@0+ (1,0) [0|1] "SED"  GWM
 SG_ TrnGearButtn_B_ActlN0 : 0|1@0+ (1,0) [0|1] "SED"  GWM
 SG_ TrnGearButtn_B_ActlM2 : 1|1@0+ (1,0) [0|1] "SED"  GWM
 SG_ TrnGearButtn_B_ActlM1 : 2|1@0+ (1,0) [0|1] "SED"  GWM
 SG_ TrnGearButtn_B_ActlM0 : 3|1@0+ (1,0) [0|1] "SED"  GWM
 SG_ TrnGearButtn_B_ActlD2 : 4|1@0+ (1,0) [0|1] "SED"  GWM
 SG_ TrnGearButtn_B_ActlD1 : 5|1@0+ (1,0) [0|1] "SED"  GWM
 SG_ TrnGearButtn_B_ActlD0 : 6|1@0+ (1,0) [0|1] "SED"  GWM
 SG_ TrnGear_No_Cs : 39|8@0+ (1,0) [0|255] "Unitless"  GWM
 SG_ TrnGear_No_Cnt : 47|4@0+ (1,0) [0|15] "Unitless"  GWM
 SG_ TrnGear_D_RqDrv : 31|5@0+ (1,0) [0|31] "SED"  GWM
 SG_ BrkSwtchPos_B_ActlGsm : 7|1@0+ (1,0) [0|1] "SED"  GWM

BO_ 1842 TesterPhysicalReqGSM: 8 TSTR
 SG_ TesterPhysicalReqGSM : 7|64@0+ (1,0) [0|1.84467E+019] "unitless"  GSM

BO_ 1850 TesterPhysicalResGSM: 8 GSM
 SG_ TesterPhysicalResGSM : 7|64@0+ (1,0) [0|1.84467E+019] "unitless"  TSTR

BO_ 936 ParkAid_Data_HS2: 8 PAM_HS2
 SG_ ApaButtnPrssd_B_Stat : 58|1@0+ (1,0) [0|1] "SED"  GWM
 SG_ ApaChime_D_Rq : 39|3@0+ (1,0) [0|7] "SED"  GWM
 SG_ ApaSys_D_Stat : 61|3@0+ (1,0) [0|7] "SED"  GWM
 SG_ ApaSteWhl_D_RqDrv : 63|2@0+ (1,0) [0|3] "SED"  GWM
 SG_ ApaSteScanMde_D_Stat : 49|2@0+ (1,0) [0|3] "SED"  GWM
 SG_ ApaSelSapp_D_Stat : 51|2@0+ (1,0) [0|3] "SED"  GWM
 SG_ ApaSelPpa_D_Stat : 53|2@0+ (1,0) [0|3] "SED"  GWM
 SG_ ApaSelPoa_D_Stat : 55|2@0+ (1,0) [0|3] "SED"  GWM
 SG_ ApaScan_D_Stat : 41|2@0+ (1,0) [0|3] "SED"  GWM
 SG_ ApaLongCtl_D_RqDrv : 44|3@0+ (1,0) [0|7] "SED"  GWM
 SG_ ApaGearShif_D_RqDrv : 47|3@0+ (1,0) [0|7] "SED"  GWM
 SG_ ApaActvSide2_D_Stat : 33|2@0+ (1,0) [0|3] "SED"  GWM
 SG_ ApaAcsy_D_RqDrv : 36|3@0+ (1,0) [0|7] "SED"  GWM
 SG_ ApaTrgtDist_D_Stat : 11|4@0+ (1,0) [0|15] "SED"  GWM
 SG_ ApaMsgTxt_D_Rq : 15|4@0+ (1,0) [0|15] "SED"  GWM
 SG_ EPASExtAngleStatReq : 23|1@0+ (1,0) [0|1] "SED"  GWM
 SG_ ExtSteeringAngleReq2 : 22|15@0+ (0.1,-1000) [-1000|2276.5] "Degrees"  GWM

BO_ 76 RCMStatusMessage2: 8 RCM
 SG_ FirstRowBuckle_No_Cs : 47|8@0+ (1,0) [0|255] "unitless"  GWM
 SG_ RstrnPsngrOn_D_Stat : 39|4@0+ (1,0) [0|15] "SED"  GWM
 SG_ RCMStatusMsg2_No_Cnt : 35|4@0+ (1,0) [0|15] "Unitless"  GWM
 SG_ PsngrFmidDetct_D_Actl : 26|2@0+ (1,0) [0|3] "SED"  GWM
 SG_ FirstRowBuckleMid : 28|2@0+ (1,0) [0|3] "SED"  GWM
 SG_ ThirdRowBucklePsngr : 17|2@0+ (1,0) [0|3] "SED"  GWM
 SG_ ThirdRowBuckleDriver : 21|2@0+ (1,0) [0|3] "SED"  GWM
 SG_ SecondRowBucklePsngr : 23|2@0+ (1,0) [0|3] "SED"  GWM
 SG_ SecondRowBuckleMid : 9|2@0+ (1,0) [0|3] "SED"  GWM
 SG_ SecondRowBuckleDriver : 11|2@0+ (1,0) [0|3] "SED"  GWM
 SG_ FirstRowBuckleDriver : 15|2@0+ (1,0) [0|3] "SED"  GSM,GWM
 SG_ RILReq : 7|2@0+ (1,0) [0|3] "SED"  GWM
 SG_ FirstRowBucklePsngr : 13|2@0+ (1,0) [0|3] "SED"  OCS,GWM
 SG_ RstrnImpactEvntStatus : 3|3@0+ (1,0) [0|7] "SED"  SCCM,OCS,GWM
 SG_ PsngrFrntDetct_D_Actl : 5|2@0+ (1,0) [0|3] "SED"  GWM
 SG_ EDRTriggerEvntSync : 29|1@0+ (1,0) [0|1] "SED"  GWM
 SG_ PassRstrnInd_Req : 31|2@0+ (1,0) [0|3] "SED"  GWM

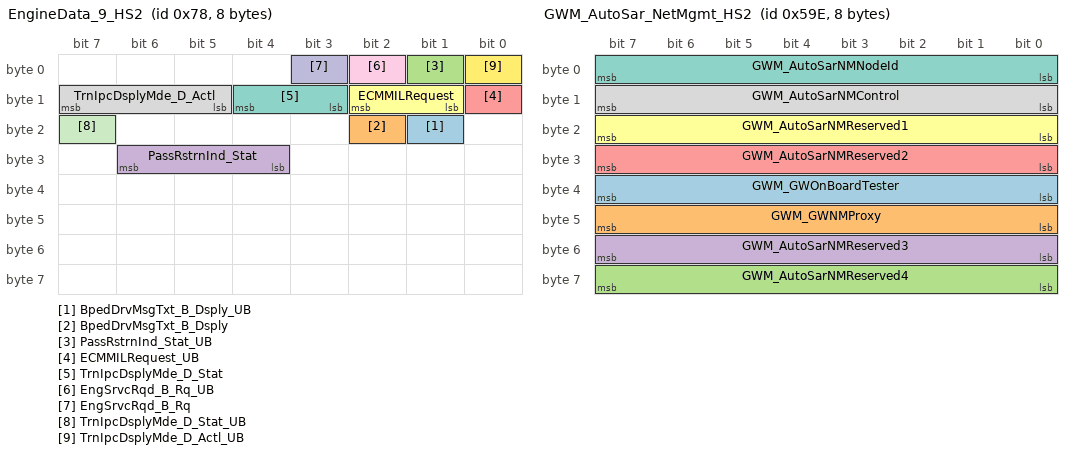
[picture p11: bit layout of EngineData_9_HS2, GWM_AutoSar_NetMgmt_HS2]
BO_ 120 EngineData_9_HS2: 8 GWM
 SG_ BpedDrvMsgTxt_B_Dsply_UB : 17|1@0+ (1,0) [0|1] "SED"  RCM
 SG_ BpedDrvMsgTxt_B_Dsply : 18|1@0+ (1,0) [0|1] "SED"  RCM
 SG_ PassRstrnInd_Stat_UB : 1|1@0+ (1,0) [0|1] "SED"  RCM
 SG_ PassRstrnInd_Stat : 30|3@0+ (1,0) [0|7] "SED"  RCM
 SG_ ECMMILRequest_UB : 8|1@0+ (1,0) [0|1] "SED"  RCM
 SG_ ECMMILRequest : 10|2@0+ (1,0) [0|3] "SED"  RCM
 SG_ TrnIpcDsplyMde_D_Stat : 12|2@0+ (1,0) [0|3] "SED"  GSM
 SG_ TrnIpcDsplyMde_D_Actl : 15|3@0+ (1,0) [0|7] "SED"  GSM
 SG_ EngSrvcRqd_B_Rq_UB : 2|1@0+ (1,0) [0|1] "SED" Vector__XXX
 SG_ EngSrvcRqd_B_Rq : 3|1@0+ (1,0) [0|1] "SED"  RCM
 SG_ TrnIpcDsplyMde_D_Stat_UB : 23|1@0+ (1,0) [0|1] "SED"  GSM
 SG_ TrnIpcDsplyMde_D_Actl_UB : 0|1@0+ (1,0) [0|1] "SED"  GSM

BO_ 1665 RCM_Rapid_Data_Response_2: 8 RCM
 SG_ UUDTRCMResponse2 : 7|64@0+ (1,0) [0|1.84467440737096E+019] "unitless"  TSTR

BO_ 2041 TesterPhysicalResPCU: 8 RCM
 SG_ TesterPhysicalResPCU : 7|64@0+ (1,0) [0|1.84467E+019] "unitless"  TSTR

BO_ 1438 GWM_AutoSar_NetMgmt_HS2: 8 GWM
 SG_ GWM_GWOnBoardTester : 39|8@0+ (1,0) [0|255] "unitless"  SCCM,GSM,ATCM_DMSM
 SG_ GWM_GWNMProxy : 47|8@0+ (1,0) [0|255] "unitless"  SCCM,GSM,ATCM_DMSM
 SG_ GWM_AutoSarNMReserved4 : 63|8@0+ (1,0) [0|255] "unitless"  SCCM,GSM,ATCM_DMSM
 SG_ GWM_AutoSarNMReserved3 : 55|8@0+ (1,0) [0|255] "unitless"  SCCM,GSM,ATCM_DMSM
 SG_ GWM_AutoSarNMReserved2 : 31|8@0+ (1,0) [0|255] "unitless"  SCCM,GSM,ATCM_DMSM
 SG_ GWM_AutoSarNMReserved1 : 23|8@0+ (1,0) [0|255] "unitless"  SCCM,GSM,ATCM_DMSM
 SG_ GWM_AutoSarNMNodeId : 7|8@0+ (1,0) [0|255] "unitless"  GSM,ATCM_DMSM,SCCM
 SG_ GWM_AutoSarNMControl : 15|8@0+ (1,0) [0|255] "unitless"  GSM,ATCM_DMSM,SCCM

BO_ 1034 GGCC_Config_Mgmt_ID_1_HS2: 8 GWM
 SG_ VehicleGGCCData : 7|64@0+ (1,0) [0|1.84467E+019] "mixed"  HCM_HS2,OCS,RCM,GSM,SCCM

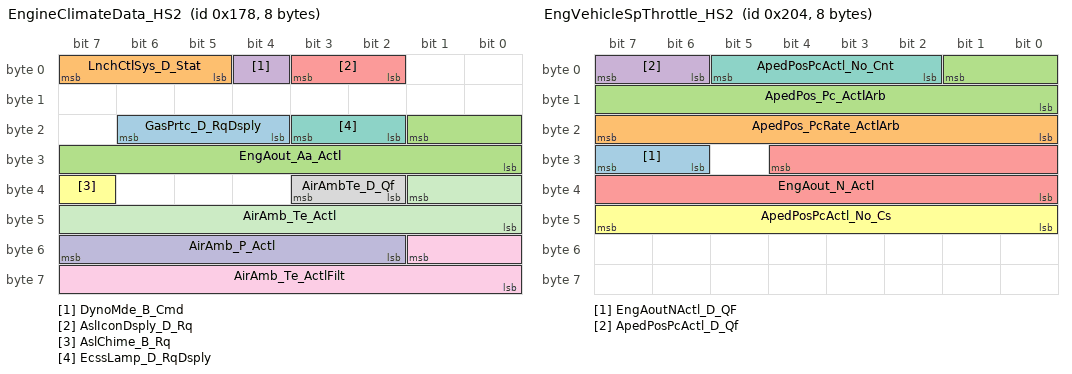
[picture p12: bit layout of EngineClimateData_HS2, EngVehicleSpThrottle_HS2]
BO_ 376 EngineClimateData_HS2: 8 GWM
 SG_ GasPrtc_D_RqDsply : 22|3@0+ (1,0) [0|7] "SED" Vector__XXX
 SG_ LnchCtlSys_D_Stat : 7|3@0+ (1,0) [0|7] "SED" Vector__XXX
 SG_ EngAout_Aa_Actl : 17|10@0+ (0.05,-25.6) [-25.6|25.55] "rpm/ms" Vector__XXX
 SG_ DynoMde_B_Cmd : 4|1@0+ (1,0) [0|1] "SED" Vector__XXX
 SG_ AslIconDsply_D_Rq : 3|2@0+ (1,0) [0|3] "SED" Vector__XXX
 SG_ AslChime_B_Rq : 39|1@0+ (1,0) [0|1] "SED" Vector__XXX
 SG_ EcssLamp_D_RqDsply : 19|2@0+ (1,0) [0|3] "SED" Vector__XXX
 SG_ AirAmbTe_D_Qf : 35|2@0+ (1,0) [0|3] "SED"  RCM,SCCM
 SG_ AirAmb_Te_ActlFilt : 49|10@0+ (0.25,-128) [-128|127.75] "deg C"  RCM
 SG_ AirAmb_P_Actl : 55|6@0+ (10,500) [500|1110] "mbar" Vector__XXX
 SG_ AirAmb_Te_Actl : 33|10@0+ (0.25,-128) [-128|127.75] "degC"  SCCM

BO_ 516 EngVehicleSpThrottle_HS2: 8 GWM
 SG_ EngAoutNActl_D_QF : 31|2@0+ (1,0) [0|3] "SED" Vector__XXX
 SG_ ApedPos_PcRate_ActlArb : 23|8@0+ (0.04,-5) [-5|5.12] "%/ms" Vector__XXX
 SG_ ApedPos_Pc_ActlArb : 1|10@0+ (0.1,0) [0|102.3] "%"  HCM_HS2,OCS,RCM
 SG_ ApedPosPcActl_D_Qf : 7|2@0+ (1,0) [0|3] "SED"  HCM_HS2,OCS,RCM
 SG_ EngAout_N_Actl : 28|13@0+ (2,0) [0|16382] "rpm"  HCM_HS2,GSM,RCM
 SG_ ApedPosPcActl_No_Cs : 47|8@0+ (1,0) [0|255] "Unitless" Vector__XXX
 SG_ ApedPosPcActl_No_Cnt : 5|4@0+ (1,0) [0|15] "Unitless" Vector__XXX

CM_ SG_ 1081 GenericSwtch2_No_Actl "U625 Police Wig Wag feature";
CM_ SG_ 942 PrkAidRdiusRight_L_Dsply "MSGDCR 679, set all signals to OnChange";
CM_ SG_ 942 PrkAidRdiusLeft_L_Dsply "MSGDCR 679, set all signals to OnChange";
CM_ SG_ 942 PrkAidDrvDir_D_Stat "MSGDCR 679, set all signals to OnChange";
CM_ BO_ 673 "Do not use this Frame for other Cluster Interaction";
CM_ SG_ 673 ICI_Coding_BtnID_D "Object InputControlInterface ICI ButtonCoding_D
(Parameter2)";
CM_ SG_ 673 ICI_Coding_BtnID_C "Object InputControlInterface ICI ButtonCoding_C
(Parameter2)";
CM_ SG_ 673 ICI_Coding_BtnID_B "Object InputControlInterface ICI ButtonCoding_B
(Parameter2)";
CM_ SG_ 673 ICI_Coding_BtnID_A "Object InputControlInterface ICI ButtonCoding_A
(Parameter2)";
CM_ SG_ 673 ICI_BtnID_D "Object InputControlInterface ICI ButtonID_D
(Parameter1)
for detailed Information refer to ICI Reference document";
CM_ SG_ 673 ICI_BtnID_C "Object InputControlInterface ICI ButtonID_C
(Parameter1)
for detailed Information refer to ICI Reference document";
CM_ SG_ 673 ICI_BtnID_B "Object InputControlInterface ICI ButtonID_B
(Parameter1)
for detailed Information refer to ICI Reference document";
CM_ SG_ 673 ICI_BtnID_A "Object InputControlInterface ICI ButtonID_A
(Parameter1)
for detailed Information refer to ICI Reference document";
CM_ SG_ 1073 HMI_HMIMode_St "Object ACU System Master.HMIMode
OR
Object NAV System Master.HMIMode

Refer Method HMIAudioMode in the SPSS";
CM_ BO_ 611 "Used on Applications with 4x4 supplied by Motorola.";
CM_ SG_ 611 AwdStat_D_RqDsply "Signal not transmitted on programs that do not have AWD.";
CM_ SG_ 611 AwdSrvcRqd_B_Rq "Signal not transmitted on programs that do not have AWD.";
CM_ SG_ 611 AwdLck_Tq_Rq "Signal not transmitted on programs that do not have AWD.";
CM_ SG_ 560 SelDrvMdeSwtch_D_Stat3 "ECM_HEV does not support or Transmit signal.";
CM_ SG_ 560 TrnSrvcRqd_B_Rq "Signal not transmitted on Diesel & HEV variants. MHT(U611/625) HPCM Rx 0x230 from PCM_HEV. Powersplit FWD HEV’s(Cx482/3 430) HPCM Tx 0x230.";
CM_ SG_ 560 TrnCnvtClu_D_Actl "Signal not transmitted on Gas & HEV variants. MHT(U611/625) HPCM Rx 0x230 from PCM_HEV. Powersplit FWD HEV’s(Cx482/3 430) HPCM Tx 0x230.";
CM_ SG_ 560 TrnShifActv_B_Actl "Signal not transmitted on HEV variants. MHT(U611/625) HPCM Rx 0x230 from PCM_HEV. Powersplit FWD HEV’s(Cx482/3 430) HPCM Tx 0x230.";
CM_ SG_ 560 GboxOil_Te_Actl "Signal not transmitted on HEV variants. MHT(U611/625) HPCM Rx 0x230 from PCM_HEV. Powersplit FWD HEV’s(Cx482/3 430) HPCM Tx 0x230.";
CM_ SG_ 359 TrnAin_Tq_Actl "Signal not transmitted on HEV variances.";
CM_ SG_ 359 TrnAinTq_D_Qf "Signal not transmitted on HEV variances.";
CM_ SG_ 357 BpedDrvAppl_D_Actl "CCMGenSigTimeoutTime=1000";
CM_ SG_ 357 CcStat_D_Actl "ABSGenSigTimeoutTime=1000";
CM_ SG_ 357 AccStopMde_D_Rq "ABSGenSigTimeoutTime=1000";
CM_ SG_ 390 AccBrkTot_A_Rq "ABSGenSigTimeoutTime=1000";
CM_ SG_ 390 AccBrkPrkEl_B_Rq "ABSGenSigTimeoutTime=1000";
CM_ SG_ 390 AccPrpl_A_Rq "PCMGenSigTimeoutTime=1000";
CM_ SG_ 390 AccBrkPrchg_B_Rq "ABSGenSigTimeoutTime=1000";
CM_ SG_ 390 AccBrkDecel_B_Rq "ABSGenSigTimeoutTime=1000";
CM_ SG_ 390 AccStopStat_B_Rq "ABSGenSigTimeoutTime=1000";
CM_ SG_ 1071 CluPdlPosPcMeas_D_Qf "Signal not transmitted on HEV variants.";
CM_ SG_ 1071 CluPdlPos_Pc_Meas "Signal not transmitted on HEV variants.";
CM_ SG_ 1072 Outside_Air_Temp_Stat "Filtered value, i.e. same as disply for customer";
CM_ SG_ 1058 TrnTotTq_Rt_Est "Signal not transmitted on gas and HEV variants.";
CM_ SG_ 1058 TrnTotLss_Tq_Est "Signal not transmitted on gas and HEV variants.";
CM_ SG_ 1082 MetricActv_B_Actl "0 =Inactive(English), 1=Active(Metric)";
CM_ SG_ 92 TrnSbwSysHlth_D_Actl "Signal not transmitted on vehicles that do not have shift by wire.";
CM_ SG_ 92 TrnDtpCmd_D_Actl "Signal not transmitted on vehicles that do not have shift by wire.";
CM_ SG_ 92 TrnGearCmd_No_Cs "Signal not transmitted on vehicles that do not have shift by wire.";
CM_ SG_ 92 TrnValidGear_D_Cnfm "Signal not transmitted on vehicles that do not have shift by wire.";
CM_ SG_ 92 TrnNtrlTowCmd_D_Actl "Signal not transmitted on vehicles that do not have shift by wire.";
CM_ SG_ 92 TrnGearCmd_Pc_ActlPt "Signal not transmitted on vehicles that do not have shift by wire.";
CM_ SG_ 92 TrnGear_D_RqPt "Signal not transmitted on vehicles that do not have shift by wire.";
CM_ SG_ 92 TrnCmdState_B_Actl "Signal not transmitted on vehicles that do not have shift by wire.";
CM_ SG_ 92 TrnCmdCnt_B_Actl "Signal not transmitted on vehicles that do not have shift by wire.";
CM_ SG_ 92 PrkBrkActv_D_RqTrnGear "Signal not transmitted on vehicles that do not have shift by wire.";
CM_ SG_ 92 TrnGearCmd_No_Cnt "Signal not transmitted on vehicles that do not have shift by wire.";
CM_ SG_ 360 GsmSrvcRqd_B_Rq "Signal not transmitted on vehicles that do not have shift by wire.";
CM_ SG_ 360 TrnGearPwmFalt_B_Actl "Signal not transmitted on vehicles that do not have shift by wire.";
CM_ SG_ 360 GearButtnStuck_B_Actl "Signal not transmitted on vehicles that do not have shift by wire.";
CM_ SG_ 90 TrnGsmNtmState_D_Actl "Signal not transmitted on vehicles that do not have shift by wire.";
CM_ SG_ 90 DrQltyDrv_D_StatGsm "Signal not transmitted on vehicles that do not have shift by wire.";
CM_ SG_ 90 TrnBtsiOvrrd_B_Stat "Signal not transmitted on vehicles that do not have shift by wire.";
CM_ SG_ 90 TrnValidGearRq_D_Stat "Signal not transmitted on vehicles that do not have shift by wire.";
CM_ SG_ 90 TrnGearRqCnt_B_Actl "Signal not transmitted on vehicles that do not have shift by wire.";
CM_ SG_ 90 TrnGearButtn_U_Actl "Signal not transmitted on vehicles that do not have shift by wire.";
CM_ SG_ 90 TrnGearButtn_B_ActlR2 "Signal not transmitted on vehicles that do not have shift by wire.";
CM_ SG_ 90 TrnGearButtn_B_ActlR1 "Signal not transmitted on vehicles that do not have shift by wire.";
CM_ SG_ 90 TrnGearButtn_B_ActlR0 "Signal not transmitted on vehicles that do not have shift by wire.";
CM_ SG_ 90 TrnGearButtn_B_ActlP2 "Signal not transmitted on vehicles that do not have shift by wire.";
CM_ SG_ 90 TrnGearButtn_B_ActlP1 "Signal not transmitted on vehicles that do not have shift by wire.";
CM_ SG_ 90 TrnGearButtn_B_ActlP0 "Signal not transmitted on vehicles that do not have shift by wire.";
CM_ SG_ 90 TrnGearButtn_B_ActlN2 "Signal not transmitted on vehicles that do not have shift by wire.";
CM_ SG_ 90 TrnGearButtn_B_ActlN1 "Signal not transmitted on vehicles that do not have shift by wire.";
CM_ SG_ 90 TrnGearButtn_B_ActlN0 "Signal not transmitted on vehicles that do not have shift by wire.";
CM_ SG_ 90 TrnGearButtn_B_ActlM2 "Signal not transmitted on vehicles that do not have shift by wire.";
CM_ SG_ 90 TrnGearButtn_B_ActlM1 "Signal not transmitted on vehicles that do not have shift by wire.";
CM_ SG_ 90 TrnGearButtn_B_ActlM0 "Signal not transmitted on vehicles that do not have shift by wire.";
CM_ SG_ 90 TrnGearButtn_B_ActlD2 "Signal not transmitted on vehicles that do not have shift by wire.";
CM_ SG_ 90 TrnGearButtn_B_ActlD1 "Signal not transmitted on vehicles that do not have shift by wire.";
CM_ SG_ 90 TrnGearButtn_B_ActlD0 "Signal not transmitted on vehicles that do not have shift by wire.";
CM_ SG_ 90 TrnGear_No_Cs "Signal not transmitted on vehicles that do not have shift by wire.";
CM_ SG_ 90 TrnGear_No_Cnt "Signal not transmitted on vehicles that do not have shift by wire.";
CM_ SG_ 90 TrnGear_D_RqDrv "Signal not transmitted on vehicles that do not have shift by wire.";
CM_ SG_ 90 BrkSwtchPos_B_ActlGsm "Signal not transmitted on vehicles that do not have shift by wire.";
CM_ SG_ 1034 VehicleGGCCData "RCMGenSigTimeout=6000";
CM_ SG_ 376 EngAout_Aa_Actl "Signal not transmitted on HEV variants.";
CM_ SG_ 516 ApedPos_Pc_ActlArb "ABSGenSigTimeoutTime=1000";
CM_ SG_ 516 ApedPosPcActl_No_Cs "Signal not transmitted on gas and diesel variants.";
CM_ SG_ 516 ApedPosPcActl_No_Cnt "Signal not transmitted on gas and diesel variants.";
BA_DEF_ SG_  "GenSigTimeoutTime_GWM" INT 0 100000;
BA_DEF_ BO_  "FrameRouting" STRING ;
BA_DEF_ BO_  "FrameGatewayNetwork" STRING ;
BA_DEF_ BO_  "NetworkInitialization" ENUM  "No","Yes";
BA_DEF_ BO_  "FrameGatewayId" HEX 0 1407;
BA_DEF_ BO_  "EventRateOfChange" INT 10 10000;
BA_DEF_ BO_  "GenMsgNrOfRepetition" INT 0 100;
BA_DEF_ BO_  "GenMsgDelayTime" INT 0 1000;
BA_DEF_ BO_  "GenMsgCycleTime" INT 0 100000;
BA_DEF_ BO_  "GenMsgSendType" ENUM  "FixedPeriodic","Event","EnabledPeriodic","NotUsed","NotUsed","EventPeriodic","NotUsed","NotUsed","NoMsgSendType";
BA_DEF_ SG_  "U_CD542_MY2021_Tx" ENUM  "No","Yes";
BA_DEF_ SG_  "ECGUsedTxSignal" ENUM  "No","Yes";
BA_DEF_ SG_  "U_T6_MCA_MY2020_Tx" ENUM  "No","Yes";
BA_DEF_ SG_  "U_P702_MY2021_Tx" ENUM  "No","Yes";
BA_DEF_ SG_  "U_CX727_MY2021_Tx" ENUM  "No","Yes";
BA_DEF_ SG_  "U_CD542_MY2021_Rx" ENUM  "No","Yes";
BA_DEF_ SG_  "ECGUsedRxSignal" ENUM  "No","Yes";
BA_DEF_ SG_  "U_T6_MCA_MY2020_Rx" ENUM  "No","Yes";
BA_DEF_ SG_  "U_P702_MY2021_Rx" ENUM  "No","Yes";
BA_DEF_ SG_  "U_CX727_MY2021_Rx" ENUM  "No","Yes";
BA_DEF_ SG_  "GenSigStartValue" HEX 0 268435455;
BA_DEF_ SG_  "MetaData" ENUM  "No","Yes";
BA_DEF_ SG_  "ContentDependant" ENUM  "No","Yes";
BA_DEF_ SG_  "GenSigStartValueInteger" INT 0 1000000000;
BA_DEF_ SG_  "UsedOnPgmDBC" ENUM  "No","Yes";
BA_DEF_ SG_  "WakeupSignal" ENUM  "No","Yes";
BA_DEF_ SG_  "GenSigInactiveValue" INT 0 100000;
BA_DEF_ SG_  "GenSigSendType" ENUM  "Cyclic","OnWrite","vector_leerstring","OnChange","vector_leerstring","IfActive","vector_leerstring","NoSigSendType";
BA_DEF_ BO_  "OvtpPushApplication" ENUM  "FALSE","TRUE";
BA_DEF_ BO_  "SCP_FreshnessValueLength" INT 0 512;
BA_DEF_ BO_  "SCP_FreshnessValueTxLength" INT 0 512;
BA_DEF_ BO_  "SCP_AuthInfoTxLength" INT 0 512;
BA_DEF_ BO_  "GenMsgRoutingTimeoutTime" INT 0 5000;
BA_DEF_ BO_  "MessageGateway" ENUM  "No","Yes";
BA_DEF_ BO_  "NmAsrMessage" ENUM  "No","Yes";
BA_DEF_ BO_  "TpApplType" STRING ;
BA_DEF_ BO_  "DiagState" ENUM  "No","Yes";
BA_DEF_ BO_  "TpTxIndex" INT 0 536870911;
BA_DEF_ BO_  "DiagRequest" ENUM  "No","Yes";
BA_DEF_ BO_  "DiagResponse" ENUM  "No","Yes";
BA_DEF_ BO_  "GenMsgILSupport" ENUM  "No","Yes";
BA_DEF_DEF_  "GenSigTimeoutTime_GWM" 0;
BA_DEF_DEF_  "FrameRouting" "";
BA_DEF_DEF_  "FrameGatewayNetwork" "NONE";
BA_DEF_DEF_  "NetworkInitialization" "Yes";
BA_DEF_DEF_  "FrameGatewayId" 0;
BA_DEF_DEF_  "EventRateOfChange" 10000;
BA_DEF_DEF_  "GenMsgNrOfRepetition" 1;
BA_DEF_DEF_  "GenMsgDelayTime" 20;
BA_DEF_DEF_  "GenMsgCycleTime" 0;
BA_DEF_DEF_  "GenMsgSendType" "NoMsgSendType";
BA_DEF_DEF_  "U_CD542_MY2021_Tx" "No";
BA_DEF_DEF_  "ECGUsedTxSignal" "No";
BA_DEF_DEF_  "U_T6_MCA_MY2020_Tx" "No";
BA_DEF_DEF_  "U_P702_MY2021_Tx" "No";
BA_DEF_DEF_  "U_CX727_MY2021_Tx" "No";
BA_DEF_DEF_  "U_CD542_MY2021_Rx" "No";
BA_DEF_DEF_  "ECGUsedRxSignal" "No";
BA_DEF_DEF_  "U_T6_MCA_MY2020_Rx" "No";
BA_DEF_DEF_  "U_P702_MY2021_Rx" "No";
BA_DEF_DEF_  "U_CX727_MY2021_Rx" "No";
BA_DEF_DEF_  "GenSigStartValue" 0;
BA_DEF_DEF_  "MetaData" "No";
BA_DEF_DEF_  "ContentDependant" "No";
BA_DEF_DEF_  "GenSigStartValueInteger" 0;
BA_DEF_DEF_  "UsedOnPgmDBC" "Yes";
BA_DEF_DEF_  "WakeupSignal" "No";
BA_DEF_DEF_  "GenSigInactiveValue" 0;
BA_DEF_DEF_  "GenSigSendType" "NoSigSendType";
BA_DEF_DEF_  "OvtpPushApplication" "FALSE";
BA_DEF_DEF_  "SCP_FreshnessValueLength" 64;
BA_DEF_DEF_  "SCP_FreshnessValueTxLength" 11;
BA_DEF_DEF_  "SCP_AuthInfoTxLength" 53;
BA_DEF_DEF_  "GenMsgRoutingTimeoutTime" 0;
BA_DEF_DEF_  "MessageGateway" "No";
BA_DEF_DEF_  "NmAsrMessage" "No";
BA_DEF_DEF_  "TpApplType" "";
BA_DEF_DEF_  "DiagState" "No";
BA_DEF_DEF_  "TpTxIndex" 0;
BA_DEF_DEF_  "DiagRequest" "No";
BA_DEF_DEF_  "DiagResponse" "No";
BA_DEF_DEF_  "GenMsgILSupport" "Yes";
BA_ "NetworkInitialization" BO_ 2611175451 0;
BA_ "TpTxIndex" BO_ 2611175451 463498456;
BA_ "NetworkInitialization" BO_ 1844 0;
BA_ "GenMsgDelayTime" BO_ 1844 0;
BA_ "GenMsgSendType" BO_ 1844 1;
BA_ "DiagRequest" BO_ 1844 1;
BA_ "GenMsgILSupport" BO_ 1844 0;
BA_ "NetworkInitialization" BO_ 1852 0;
BA_ "GenMsgDelayTime" BO_ 1852 0;
BA_ "GenMsgSendType" BO_ 1852 1;
BA_ "DiagResponse" BO_ 1852 1;
BA_ "GenMsgILSupport" BO_ 1852 0;
BA_ "GenMsgCycleTime" BO_ 989 1000;
BA_ "GenMsgSendType" BO_ 989 5;
BA_ "NetworkInitialization" BO_ 2612002008 0;
BA_ "GenMsgDelayTime" BO_ 2612002008 0;
BA_ "GenMsgSendType" BO_ 2612002008 1;
BA_ "TpTxIndex" BO_ 2612002008 464518360;
BA_ "GenMsgCycleTime" BO_ 1081 1000;
BA_ "GenMsgSendType" BO_ 1081 5;
BA_ "GenMsgDelayTime" BO_ 937 10;
BA_ "GenMsgCycleTime" BO_ 937 20;
BA_ "GenMsgSendType" BO_ 937 0;
BA_ "FrameGatewayNetwork" BO_ 1010 "FD1_CAN";
BA_ "FrameGatewayId" BO_ 1010 1010;
BA_ "NetworkInitialization" BO_ 2612224027 0;
BA_ "GenMsgDelayTime" BO_ 2612224027 0;
BA_ "GenMsgSendType" BO_ 2612224027 1;
BA_ "OvtpPushApplication" BO_ 2612224027 1;
BA_ "TpTxIndex" BO_ 2612224027 464547032;
BA_ "NetworkInitialization" BO_ 2610953432 0;
BA_ "GenMsgDelayTime" BO_ 2610953432 0;
BA_ "GenMsgSendType" BO_ 2610953432 1;
BA_ "TpTxIndex" BO_ 2610953432 463469784;
BA_ "NetworkInitialization" BO_ 2609933528 0;
BA_ "GenMsgDelayTime" BO_ 2609933528 0;
BA_ "GenMsgSendType" BO_ 2609933528 1;
BA_ "TpTxIndex" BO_ 2609933528 462449880;
BA_ "NetworkInitialization" BO_ 2610126875 0;
BA_ "GenMsgDelayTime" BO_ 2610126875 0;
BA_ "GenMsgSendType" BO_ 2610126875 1;
BA_ "TpTxIndex" BO_ 2610126875 462449880;
BA_ "NetworkInitialization" BO_ 1854 0;
BA_ "GenMsgDelayTime" BO_ 1854 0;
BA_ "GenMsgSendType" BO_ 1854 1;
BA_ "DiagResponse" BO_ 1854 1;
BA_ "GenMsgILSupport" BO_ 1854 0;
BA_ "GenMsgCycleTime" BO_ 942 1000;
BA_ "GenMsgSendType" BO_ 942 5;
BA_ "NetworkInitialization" BO_ 1487 0;
BA_ "GenMsgCycleTime" BO_ 1487 1000;
BA_ "GenMsgSendType" BO_ 1487 0;
BA_ "NmAsrMessage" BO_ 1487 1;
BA_ "GenMsgILSupport" BO_ 1487 0;
BA_ "GenMsgCycleTime" BO_ 1120 1000;
BA_ "GenMsgSendType" BO_ 1120 5;
BA_ "GenMsgCycleTime" BO_ 1080 1000;
BA_ "GenMsgSendType" BO_ 1080 5;
BA_ "GenMsgCycleTime" BO_ 1121 1000;
BA_ "GenMsgSendType" BO_ 1121 5;
BA_ "GenMsgCycleTime" BO_ 673 100;
BA_ "GenMsgSendType" BO_ 673 5;
BA_ "GenMsgDelayTime" BO_ 820 10;
BA_ "GenMsgCycleTime" BO_ 820 1000;
BA_ "GenMsgSendType" BO_ 820 5;
BA_ "GenMsgCycleTime" BO_ 1073 1000;
BA_ "GenMsgSendType" BO_ 1073 5;
BA_ "FrameRouting" BO_ 1091 "HS3_CAN,0x443;MS1_CAN,0x443";
BA_ "GenMsgCycleTime" BO_ 1068 100;
BA_ "GenMsgSendType" BO_ 1068 5;
BA_ "GenMsgRoutingTimeoutTime" BO_ 1068 150;
BA_ "MessageGateway" BO_ 1068 1;
BA_ "FrameGatewayNetwork" BO_ 611 "FD1_CAN";
BA_ "FrameGatewayId" BO_ 611 611;
BA_ "GenMsgCycleTime" BO_ 578 100;
BA_ "GenMsgSendType" BO_ 578 5;
BA_ "GenMsgRoutingTimeoutTime" BO_ 578 120;
BA_ "MessageGateway" BO_ 578 1;
BA_ "GenMsgDelayTime" BO_ 560 10;
BA_ "GenMsgCycleTime" BO_ 560 100;
BA_ "GenMsgSendType" BO_ 560 5;
BA_ "GenMsgRoutingTimeoutTime" BO_ 560 60;
BA_ "MessageGateway" BO_ 560 1;
BA_ "FrameGatewayNetwork" BO_ 359 "FD1_CAN";
BA_ "FrameGatewayId" BO_ 359 359;
BA_ "GenMsgDelayTime" BO_ 359 0;
BA_ "GenMsgDelayTime" BO_ 357 10;
BA_ "GenMsgCycleTime" BO_ 357 100;
BA_ "GenMsgSendType" BO_ 357 5;
BA_ "GenMsgRoutingTimeoutTime" BO_ 357 60;
BA_ "MessageGateway" BO_ 357 1;
BA_ "FrameGatewayNetwork" BO_ 390 "FD1_CAN";
BA_ "FrameGatewayId" BO_ 390 390;
BA_ "FrameGatewayNetwork" BO_ 1071 "FD1_CAN";
BA_ "FrameGatewayId" BO_ 1071 1071;
BA_ "GenMsgCycleTime" BO_ 1072 100;
BA_ "GenMsgSendType" BO_ 1072 5;
BA_ "GenMsgCycleTime" BO_ 1058 100;
BA_ "GenMsgSendType" BO_ 1058 0;
BA_ "GenMsgCycleTime" BO_ 1082 1000;
BA_ "GenMsgSendType" BO_ 1082 5;
BA_ "NetworkInitialization" BO_ 1462 0;
BA_ "GenMsgCycleTime" BO_ 1462 1000;
BA_ "GenMsgSendType" BO_ 1462 0;
BA_ "NmAsrMessage" BO_ 1462 1;
BA_ "GenMsgILSupport" BO_ 1462 0;
BA_ "FrameGatewayNetwork" BO_ 92 "FD1_CAN";
BA_ "FrameGatewayId" BO_ 92 92;
BA_ "GenMsgCycleTime" BO_ 360 1000;
BA_ "GenMsgSendType" BO_ 360 0;
BA_ "GenMsgCycleTime" BO_ 90 100;
BA_ "GenMsgSendType" BO_ 90 5;
BA_ "NetworkInitialization" BO_ 1842 0;
BA_ "GenMsgDelayTime" BO_ 1842 0;
BA_ "GenMsgSendType" BO_ 1842 1;
BA_ "DiagRequest" BO_ 1842 1;
BA_ "GenMsgILSupport" BO_ 1842 0;
BA_ "NetworkInitialization" BO_ 1850 0;
BA_ "GenMsgDelayTime" BO_ 1850 0;
BA_ "GenMsgSendType" BO_ 1850 1;
BA_ "DiagResponse" BO_ 1850 1;
BA_ "GenMsgILSupport" BO_ 1850 0;
BA_ "GenMsgDelayTime" BO_ 936 10;
BA_ "GenMsgCycleTime" BO_ 936 20;
BA_ "GenMsgSendType" BO_ 936 0;
BA_ "GenMsgDelayTime" BO_ 76 10;
BA_ "GenMsgCycleTime" BO_ 76 100;
BA_ "GenMsgSendType" BO_ 76 5;
BA_ "GenMsgDelayTime" BO_ 120 10;
BA_ "GenMsgCycleTime" BO_ 120 50;
BA_ "GenMsgSendType" BO_ 120 0;
BA_ "NetworkInitialization" BO_ 1665 0;
BA_ "GenMsgSendType" BO_ 1665 1;
BA_ "TpApplType" BO_ 1665 "DiagUUDTResponse";
BA_ "GenMsgILSupport" BO_ 1665 0;
BA_ "NetworkInitialization" BO_ 2041 0;
BA_ "GenMsgDelayTime" BO_ 2041 0;
BA_ "GenMsgSendType" BO_ 2041 1;
BA_ "GenMsgILSupport" BO_ 2041 0;
BA_ "NetworkInitialization" BO_ 1438 0;
BA_ "GenMsgCycleTime" BO_ 1438 1000;
BA_ "GenMsgSendType" BO_ 1438 0;
BA_ "NmAsrMessage" BO_ 1438 1;
BA_ "GenMsgILSupport" BO_ 1438 0;
BA_ "FrameGatewayNetwork" BO_ 1034 "HS1_CAN";
BA_ "FrameGatewayId" BO_ 1034 1034;
BA_ "FrameGatewayNetwork" BO_ 376 "FD1_CAN";
BA_ "FrameGatewayId" BO_ 376 376;
BA_ "FrameGatewayNetwork" BO_ 516 "FD1_CAN";
BA_ "FrameGatewayId" BO_ 516 516;
BA_ "GenMsgDelayTime" BO_ 516 0;
BA_ "U_T6_MCA_MY2020_Tx" SG_ 2611175451 PARSEDPhysGSMtoGWM_ECG 1;
BA_ "GenSigSendType" SG_ 2611175451 PARSEDPhysGSMtoGWM_ECG 3;
BA_ "U_CD542_MY2021_Rx" SG_ 1844 TesterPhysicalReqHCM 1;
BA_ "U_T6_MCA_MY2020_Rx" SG_ 1844 TesterPhysicalReqHCM 1;
BA_ "U_P702_MY2021_Rx" SG_ 1844 TesterPhysicalReqHCM 1;
BA_ "U_CX727_MY2021_Rx" SG_ 1844 TesterPhysicalReqHCM 1;
BA_ "GenSigSendType" SG_ 1844 TesterPhysicalReqHCM 3;
BA_ "U_CD542_MY2021_Tx" SG_ 1852 TesterPhysicalResHCM 1;
BA_ "U_T6_MCA_MY2020_Tx" SG_ 1852 TesterPhysicalResHCM 1;
BA_ "U_P702_MY2021_Tx" SG_ 1852 TesterPhysicalResHCM 1;
BA_ "U_CX727_MY2021_Tx" SG_ 1852 TesterPhysicalResHCM 1;
BA_ "GenSigSendType" SG_ 1852 TesterPhysicalResHCM 3;
BA_ "U_CD542_MY2021_Tx" SG_ 989 FeatNoHcm_No_Actl 1;
BA_ "U_T6_MCA_MY2020_Tx" SG_ 989 FeatNoHcm_No_Actl 1;
BA_ "U_P702_MY2021_Tx" SG_ 989 FeatNoHcm_No_Actl 1;
BA_ "U_CX727_MY2021_Tx" SG_ 989 FeatNoHcm_No_Actl 1;
BA_ "GenSigSendType" SG_ 989 FeatNoHcm_No_Actl 3;
BA_ "U_CD542_MY2021_Tx" SG_ 989 FeatConfigHcmActl 1;
BA_ "U_T6_MCA_MY2020_Tx" SG_ 989 FeatConfigHcmActl 1;
BA_ "U_P702_MY2021_Tx" SG_ 989 FeatConfigHcmActl 1;
BA_ "U_CX727_MY2021_Tx" SG_ 989 FeatConfigHcmActl 1;
BA_ "GenSigSendType" SG_ 989 FeatConfigHcmActl 3;
BA_ "ECGUsedTxSignal" SG_ 2612002008 PARSEDFuncGWM_ECG 1;
BA_ "U_T6_MCA_MY2020_Tx" SG_ 2612002008 PARSEDFuncGWM_ECG 1;
BA_ "U_CD542_MY2021_Rx" SG_ 2612002008 PARSEDFuncGWM_ECG 1;
BA_ "U_T6_MCA_MY2020_Rx" SG_ 2612002008 PARSEDFuncGWM_ECG 1;
BA_ "GenSigSendType" SG_ 2612002008 PARSEDFuncGWM_ECG 3;
BA_ "GenSigSendType" SG_ 1081 DieslPrtc2_D_RqDsply 3;
BA_ "U_CD542_MY2021_Rx" SG_ 1081 PrkAidSwtch_D_RqMnu_UB 1;
BA_ "U_T6_MCA_MY2020_Rx" SG_ 1081 PrkAidSwtch_D_RqMnu_UB 1;
BA_ "U_CD542_MY2021_Rx" SG_ 1081 PrkAidSwtch_D_RqMnu 1;
BA_ "U_T6_MCA_MY2020_Rx" SG_ 1081 PrkAidSwtch_D_RqMnu 1;
BA_ "GenSigSendType" SG_ 1081 PrkAidSwtch_D_RqMnu 3;
BA_ "GenSigSendType" SG_ 1081 ApaSwtch_D_RqMnu 3;
BA_ "U_CD542_MY2021_Rx" SG_ 1081 FapLcActv_B_Stat_UB 1;
BA_ "U_T6_MCA_MY2020_Rx" SG_ 1081 FapLcActv_B_Stat_UB 1;
BA_ "U_T6_MCA_MY2020_Rx" SG_ 1081 PrkAidRear_D_RqDrv_UB 1;
BA_ "U_T6_MCA_MY2020_Rx" SG_ 1081 PrkAidRear_D_RqDrv 1;
BA_ "GenSigSendType" SG_ 1081 PrkAidRear_D_RqDrv 3;
BA_ "GenSigSendType" SG_ 1081 PrkAidFront_D_RqDrv 3;
BA_ "GenSigSendType" SG_ 1081 GenericSwtch3_No_Actl 3;
BA_ "GenSigSendType" SG_ 1081 GenericSwtch2_No_Actl 3;
BA_ "ContentDependant" SG_ 1081 GenericSwtch2_No_Actl 1;
BA_ "GenSigSendType" SG_ 1081 GenericSwtch1_No_Actl 3;
BA_ "U_CD542_MY2021_Tx" SG_ 937 Veh_V_RqFap 1;
BA_ "U_T6_MCA_MY2020_Tx" SG_ 937 Veh_V_RqFap 1;
BA_ "U_CD542_MY2021_Tx" SG_ 937 TrnRngDRqFap_No_Cs 1;
BA_ "U_T6_MCA_MY2020_Tx" SG_ 937 TrnRngDRqFap_No_Cs 1;
BA_ "MetaData" SG_ 937 TrnRngDRqFap_No_Cs 1;
BA_ "U_CD542_MY2021_Tx" SG_ 937 TrnRngDRqFap_No_Cnt 1;
BA_ "U_T6_MCA_MY2020_Tx" SG_ 937 TrnRngDRqFap_No_Cnt 1;
BA_ "MetaData" SG_ 937 TrnRngDRqFap_No_Cnt 1;
BA_ "U_CD542_MY2021_Tx" SG_ 937 TrnRng_D_RqFap 1;
BA_ "U_T6_MCA_MY2020_Tx" SG_ 937 TrnRng_D_RqFap 1;
BA_ "U_CD542_MY2021_Tx" SG_ 937 FapLcDistToObj_L_Actl 1;
BA_ "U_T6_MCA_MY2020_Tx" SG_ 937 FapLcDistToObj_L_Actl 1;
BA_ "GenSigStartValue" SG_ 937 FapLcDistToObj_L_Actl 254;
BA_ "GenSigStartValueInteger" SG_ 937 FapLcDistToObj_L_Actl 254;
BA_ "U_CD542_MY2021_Rx" SG_ 1010 LightRng_L_Max 1;
BA_ "U_T6_MCA_MY2020_Rx" SG_ 1010 LightRng_L_Max 1;
BA_ "U_P702_MY2021_Rx" SG_ 1010 LightRng_L_Max 1;
BA_ "U_CX727_MY2021_Rx" SG_ 1010 LightRng_L_Max 1;
BA_ "U_CD542_MY2021_Rx" SG_ 1010 LightPathOffst_L_Actl 1;
BA_ "U_T6_MCA_MY2020_Rx" SG_ 1010 LightPathOffst_L_Actl 1;
BA_ "U_P702_MY2021_Rx" SG_ 1010 LightPathOffst_L_Actl 1;
BA_ "U_CX727_MY2021_Rx" SG_ 1010 LightPathOffst_L_Actl 1;
BA_ "GenSigStartValueInteger" SG_ 1010 LightPathOffst_L_Actl 512;
BA_ "U_CD542_MY2021_Rx" SG_ 1010 LightPath_An_Actl 1;
BA_ "U_T6_MCA_MY2020_Rx" SG_ 1010 LightPath_An_Actl 1;
BA_ "U_P702_MY2021_Rx" SG_ 1010 LightPath_An_Actl 1;
BA_ "U_CX727_MY2021_Rx" SG_ 1010 LightPath_An_Actl 1;
BA_ "GenSigStartValueInteger" SG_ 1010 LightPath_An_Actl 1000;
BA_ "U_CD542_MY2021_Rx" SG_ 1010 LightCurv_NoRate_Actl 1;
BA_ "U_T6_MCA_MY2020_Rx" SG_ 1010 LightCurv_NoRate_Actl 1;
BA_ "U_P702_MY2021_Rx" SG_ 1010 LightCurv_NoRate_Actl 1;
BA_ "U_CX727_MY2021_Rx" SG_ 1010 LightCurv_NoRate_Actl 1;
BA_ "GenSigStartValueInteger" SG_ 1010 LightCurv_NoRate_Actl 4096;
BA_ "U_CD542_MY2021_Rx" SG_ 1010 LightCurv_No_Actl 1;
BA_ "U_T6_MCA_MY2020_Rx" SG_ 1010 LightCurv_No_Actl 1;
BA_ "U_P702_MY2021_Rx" SG_ 1010 LightCurv_No_Actl 1;
BA_ "U_CX727_MY2021_Rx" SG_ 1010 LightCurv_No_Actl 1;
BA_ "GenSigStartValueInteger" SG_ 1010 LightCurv_No_Actl 1000;
BA_ "U_CD542_MY2021_Rx" SG_ 1010 CbdblActv_B_RqAdas 1;
BA_ "U_T6_MCA_MY2020_Rx" SG_ 1010 CbdblActv_B_RqAdas 1;
BA_ "U_CD542_MY2021_Rx" SG_ 1010 AdbUrbanArea_B_Stat 1;
BA_ "U_T6_MCA_MY2020_Rx" SG_ 1010 AdbUrbanArea_B_Stat 1;
BA_ "U_T6_MCA_MY2020_Tx" SG_ 2612224027 PARSEDPushGSMtoGWM_ECG 1;
BA_ "GenSigSendType" SG_ 2612224027 PARSEDPushGSMtoGWM_ECG 3;
BA_ "ECGUsedTxSignal" SG_ 2610953432 OTAFuncGWM_ECG 1;
BA_ "U_T6_MCA_MY2020_Tx" SG_ 2610953432 OTAFuncGWM_ECG 1;
BA_ "U_P702_MY2021_Rx" SG_ 2610953432 OTAFuncGWM_ECG 1;
BA_ "U_CX727_MY2021_Rx" SG_ 2610953432 OTAFuncGWM_ECG 1;
BA_ "U_CD542_MY2021_Rx" SG_ 2610953432 OTAFuncGWM_ECG 1;
BA_ "U_T6_MCA_MY2020_Rx" SG_ 2610953432 OTAFuncGWM_ECG 1;
BA_ "GenSigSendType" SG_ 2610953432 OTAFuncGWM_ECG 3;
BA_ "ECGUsedTxSignal" SG_ 2609933528 OTAPhysGWM_ECGtoGSM 1;
BA_ "U_CD542_MY2021_Rx" SG_ 2609933528 OTAPhysGWM_ECGtoGSM 1;
BA_ "U_T6_MCA_MY2020_Rx" SG_ 2609933528 OTAPhysGWM_ECGtoGSM 1;
BA_ "GenSigSendType" SG_ 2609933528 OTAPhysGWM_ECGtoGSM 3;
BA_ "U_CD542_MY2021_Tx" SG_ 2610126875 OTAPhysGSMtoGWM_ECG 1;
BA_ "U_T6_MCA_MY2020_Tx" SG_ 2610126875 OTAPhysGSMtoGWM_ECG 1;
BA_ "GenSigSendType" SG_ 2610126875 OTAPhysGSMtoGWM_ECG 3;
BA_ "U_CD542_MY2021_Tx" SG_ 1854 TesterPhysicalResPAM 1;
BA_ "U_T6_MCA_MY2020_Tx" SG_ 1854 TesterPhysicalResPAM 1;
BA_ "GenSigSendType" SG_ 1854 TesterPhysicalResPAM 3;
BA_ "U_CD542_MY2021_Tx" SG_ 942 PrkAidRdiusRight_L_Dsply 1;
BA_ "U_T6_MCA_MY2020_Tx" SG_ 942 PrkAidRdiusRight_L_Dsply 1;
BA_ "U_CD542_MY2021_Tx" SG_ 942 PrkAidRdiusLeft_L_Dsply 1;
BA_ "U_T6_MCA_MY2020_Tx" SG_ 942 PrkAidRdiusLeft_L_Dsply 1;
BA_ "U_CD542_MY2021_Tx" SG_ 942 PrkAidDrvDir_D_Stat 1;
BA_ "U_T6_MCA_MY2020_Tx" SG_ 942 PrkAidDrvDir_D_Stat 1;
BA_ "GenSigSendType" SG_ 942 PrkAidDrvDir_D_Stat 3;
BA_ "U_T6_MCA_MY2020_Tx" SG_ 1487 ATCM_GWOnBoardTester 1;
BA_ "U_P702_MY2021_Tx" SG_ 1487 ATCM_GWOnBoardTester 1;
BA_ "GenSigStartValue" SG_ 1487 ATCM_GWOnBoardTester 255;
BA_ "ContentDependant" SG_ 1487 ATCM_GWOnBoardTester 1;
BA_ "GenSigStartValueInteger" SG_ 1487 ATCM_GWOnBoardTester 255;
BA_ "U_T6_MCA_MY2020_Tx" SG_ 1487 ATCM_GWNMProxy 1;
BA_ "U_P702_MY2021_Tx" SG_ 1487 ATCM_GWNMProxy 1;
BA_ "GenSigStartValue" SG_ 1487 ATCM_GWNMProxy 255;
BA_ "ContentDependant" SG_ 1487 ATCM_GWNMProxy 1;
BA_ "GenSigStartValueInteger" SG_ 1487 ATCM_GWNMProxy 255;
BA_ "U_T6_MCA_MY2020_Tx" SG_ 1487 ATCM_AutoSarNMReserved4 1;
BA_ "U_P702_MY2021_Tx" SG_ 1487 ATCM_AutoSarNMReserved4 1;
BA_ "GenSigStartValue" SG_ 1487 ATCM_AutoSarNMReserved4 255;
BA_ "ContentDependant" SG_ 1487 ATCM_AutoSarNMReserved4 1;
BA_ "GenSigStartValueInteger" SG_ 1487 ATCM_AutoSarNMReserved4 255;
BA_ "U_T6_MCA_MY2020_Tx" SG_ 1487 ATCM_AutoSarNMReserved3 1;
BA_ "U_P702_MY2021_Tx" SG_ 1487 ATCM_AutoSarNMReserved3 1;
BA_ "GenSigStartValue" SG_ 1487 ATCM_AutoSarNMReserved3 255;
BA_ "ContentDependant" SG_ 1487 ATCM_AutoSarNMReserved3 1;
BA_ "GenSigStartValueInteger" SG_ 1487 ATCM_AutoSarNMReserved3 255;
BA_ "U_T6_MCA_MY2020_Tx" SG_ 1487 ATCM_AutoSarNMReserved2 1;
BA_ "U_P702_MY2021_Tx" SG_ 1487 ATCM_AutoSarNMReserved2 1;
BA_ "GenSigStartValue" SG_ 1487 ATCM_AutoSarNMReserved2 255;
BA_ "ContentDependant" SG_ 1487 ATCM_AutoSarNMReserved2 1;
BA_ "GenSigStartValueInteger" SG_ 1487 ATCM_AutoSarNMReserved2 255;
BA_ "U_T6_MCA_MY2020_Tx" SG_ 1487 ATCM_AutoSarNMReserved1 1;
BA_ "U_P702_MY2021_Tx" SG_ 1487 ATCM_AutoSarNMReserved1 1;
BA_ "GenSigStartValue" SG_ 1487 ATCM_AutoSarNMReserved1 255;
BA_ "ContentDependant" SG_ 1487 ATCM_AutoSarNMReserved1 1;
BA_ "GenSigStartValueInteger" SG_ 1487 ATCM_AutoSarNMReserved1 255;
BA_ "U_T6_MCA_MY2020_Tx" SG_ 1487 ATCM_AutoSarNMNodeId 1;
BA_ "U_P702_MY2021_Tx" SG_ 1487 ATCM_AutoSarNMNodeId 1;
BA_ "GenSigStartValue" SG_ 1487 ATCM_AutoSarNMNodeId 207;
BA_ "ContentDependant" SG_ 1487 ATCM_AutoSarNMNodeId 1;
BA_ "GenSigStartValueInteger" SG_ 1487 ATCM_AutoSarNMNodeId 207;
BA_ "U_T6_MCA_MY2020_Tx" SG_ 1487 ATCM_AutoSarNMControl 1;
BA_ "U_P702_MY2021_Tx" SG_ 1487 ATCM_AutoSarNMControl 1;
BA_ "ContentDependant" SG_ 1487 ATCM_AutoSarNMControl 1;
BA_ "GenSigStartValue" SG_ 1120 FrontDiffLck_D_RqDrv 2;
BA_ "GenSigStartValueInteger" SG_ 1120 FrontDiffLck_D_RqDrv 2;
BA_ "GenSigSendType" SG_ 1120 FrontDiffLck_D_RqDrv 3;
BA_ "U_T6_MCA_MY2020_Tx" SG_ 1120 RearDiffLck_D_RqDrv 1;
BA_ "U_P702_MY2021_Tx" SG_ 1120 RearDiffLck_D_RqDrv 1;
BA_ "GenSigSendType" SG_ 1120 RearDiffLck_D_RqDrv 3;
BA_ "GenSigStartValue" SG_ 1120 RearDiffLck_D_RqDrv 2;
BA_ "GenSigStartValueInteger" SG_ 1120 RearDiffLck_D_RqDrv 2;
BA_ "U_T6_MCA_MY2020_Tx" SG_ 1120 AwdMde_D_RqDrv 1;
BA_ "U_P702_MY2021_Tx" SG_ 1120 AwdMde_D_RqDrv 1;
BA_ "GenSigSendType" SG_ 1120 AwdMde_D_RqDrv 3;
BA_ "GenSigStartValue" SG_ 1120 AwdMde_D_RqDrv 5;
BA_ "GenSigStartValueInteger" SG_ 1120 AwdMde_D_RqDrv 5;
BA_ "GenSigSendType" SG_ 1080 TrlrAidMde_D_Rq 3;
BA_ "GenSigSendType" SG_ 1080 Rba_D_Rq 3;
BA_ "GenSigSendType" SG_ 1080 TrailCtlPt_B_Falt 3;
BA_ "U_CD542_MY2021_Rx" SG_ 1080 CabnAmb_Te_Actl_UB 1;
BA_ "U_T6_MCA_MY2020_Rx" SG_ 1080 CabnAmb_Te_Actl_UB 1;
BA_ "U_CX727_MY2021_Rx" SG_ 1080 CabnAmb_Te_Actl_UB 1;
BA_ "U_CD542_MY2021_Rx" SG_ 1080 CabnAmb_Te_Actl 1;
BA_ "U_T6_MCA_MY2020_Rx" SG_ 1080 CabnAmb_Te_Actl 1;
BA_ "U_CX727_MY2021_Rx" SG_ 1080 CabnAmb_Te_Actl 1;
BA_ "GenSigStartValueInteger" SG_ 1080 CabnAmb_Te_Actl 114;
BA_ "U_CD542_MY2021_Rx" SG_ 1080 HeadLghtHiPrmsn_D_Stat_UB 1;
BA_ "U_T6_MCA_MY2020_Rx" SG_ 1080 HeadLghtHiPrmsn_D_Stat_UB 1;
BA_ "U_P702_MY2021_Rx" SG_ 1080 HeadLghtHiPrmsn_D_Stat_UB 1;
BA_ "U_CX727_MY2021_Rx" SG_ 1080 HeadLghtHiPrmsn_D_Stat_UB 1;
BA_ "U_CD542_MY2021_Rx" SG_ 1080 HeadLghtHiPrmsn_D_Stat 1;
BA_ "U_T6_MCA_MY2020_Rx" SG_ 1080 HeadLghtHiPrmsn_D_Stat 1;
BA_ "U_P702_MY2021_Rx" SG_ 1080 HeadLghtHiPrmsn_D_Stat 1;
BA_ "U_CX727_MY2021_Rx" SG_ 1080 HeadLghtHiPrmsn_D_Stat 1;
BA_ "GenSigSendType" SG_ 1080 HeadLghtHiPrmsn_D_Stat 3;
BA_ "GenSigStartValue" SG_ 1080 HeadLghtHiPrmsn_D_Stat 3;
BA_ "GenSigStartValueInteger" SG_ 1080 HeadLghtHiPrmsn_D_Stat 3;
BA_ "U_T6_MCA_MY2020_Tx" SG_ 1121 SelDrvMdeSwtch_No_Actl 1;
BA_ "U_P702_MY2021_Tx" SG_ 1121 SelDrvMdeSwtch_No_Actl 1;
BA_ "GenSigSendType" SG_ 1121 SelDrvMdeSwtch_No_Actl 3;
BA_ "U_T6_MCA_MY2020_Tx" SG_ 1121 SelDrvMdeSwtch_D_Stat 1;
BA_ "U_P702_MY2021_Tx" SG_ 1121 SelDrvMdeSwtch_D_Stat 1;
BA_ "GenSigSendType" SG_ 1121 SelDrvMdeSwtch_D_Stat 3;
BA_ "U_T6_MCA_MY2020_Tx" SG_ 1121 SelDrvMdeCnt_D_Stat 1;
BA_ "U_P702_MY2021_Tx" SG_ 1121 SelDrvMdeCnt_D_Stat 1;
BA_ "GenSigSendType" SG_ 1121 SelDrvMdeCnt_D_Stat 3;
BA_ "U_CD542_MY2021_Tx" SG_ 673 ICI_Coding_BtnID_D 1;
BA_ "U_T6_MCA_MY2020_Tx" SG_ 673 ICI_Coding_BtnID_D 1;
BA_ "U_P702_MY2021_Tx" SG_ 673 ICI_Coding_BtnID_D 1;
BA_ "U_CX727_MY2021_Tx" SG_ 673 ICI_Coding_BtnID_D 1;
BA_ "GenSigSendType" SG_ 673 ICI_Coding_BtnID_D 3;
BA_ "U_CD542_MY2021_Tx" SG_ 673 ICI_Coding_BtnID_C 1;
BA_ "U_T6_MCA_MY2020_Tx" SG_ 673 ICI_Coding_BtnID_C 1;
BA_ "U_P702_MY2021_Tx" SG_ 673 ICI_Coding_BtnID_C 1;
BA_ "U_CX727_MY2021_Tx" SG_ 673 ICI_Coding_BtnID_C 1;
BA_ "GenSigSendType" SG_ 673 ICI_Coding_BtnID_C 3;
BA_ "U_CD542_MY2021_Tx" SG_ 673 ICI_Coding_BtnID_B 1;
BA_ "U_T6_MCA_MY2020_Tx" SG_ 673 ICI_Coding_BtnID_B 1;
BA_ "U_P702_MY2021_Tx" SG_ 673 ICI_Coding_BtnID_B 1;
BA_ "U_CX727_MY2021_Tx" SG_ 673 ICI_Coding_BtnID_B 1;
BA_ "GenSigSendType" SG_ 673 ICI_Coding_BtnID_B 3;
BA_ "U_CD542_MY2021_Tx" SG_ 673 ICI_Coding_BtnID_A 1;
BA_ "U_T6_MCA_MY2020_Tx" SG_ 673 ICI_Coding_BtnID_A 1;
BA_ "U_P702_MY2021_Tx" SG_ 673 ICI_Coding_BtnID_A 1;
BA_ "U_CX727_MY2021_Tx" SG_ 673 ICI_Coding_BtnID_A 1;
BA_ "GenSigSendType" SG_ 673 ICI_Coding_BtnID_A 3;
BA_ "U_CD542_MY2021_Tx" SG_ 673 ICI_BtnID_D 1;
BA_ "U_T6_MCA_MY2020_Tx" SG_ 673 ICI_BtnID_D 1;
BA_ "U_P702_MY2021_Tx" SG_ 673 ICI_BtnID_D 1;
BA_ "U_CX727_MY2021_Tx" SG_ 673 ICI_BtnID_D 1;
BA_ "GenSigSendType" SG_ 673 ICI_BtnID_D 3;
BA_ "GenSigStartValue" SG_ 673 ICI_BtnID_D 255;
BA_ "GenSigStartValueInteger" SG_ 673 ICI_BtnID_D 255;
BA_ "U_CD542_MY2021_Tx" SG_ 673 ICI_BtnID_C 1;
BA_ "U_T6_MCA_MY2020_Tx" SG_ 673 ICI_BtnID_C 1;
BA_ "U_P702_MY2021_Tx" SG_ 673 ICI_BtnID_C 1;
BA_ "U_CX727_MY2021_Tx" SG_ 673 ICI_BtnID_C 1;
BA_ "GenSigSendType" SG_ 673 ICI_BtnID_C 3;
BA_ "GenSigStartValue" SG_ 673 ICI_BtnID_C 255;
BA_ "GenSigStartValueInteger" SG_ 673 ICI_BtnID_C 255;
BA_ "U_CD542_MY2021_Tx" SG_ 673 ICI_BtnID_B 1;
BA_ "U_T6_MCA_MY2020_Tx" SG_ 673 ICI_BtnID_B 1;
BA_ "U_P702_MY2021_Tx" SG_ 673 ICI_BtnID_B 1;
BA_ "U_CX727_MY2021_Tx" SG_ 673 ICI_BtnID_B 1;
BA_ "GenSigSendType" SG_ 673 ICI_BtnID_B 3;
BA_ "GenSigStartValue" SG_ 673 ICI_BtnID_B 255;
BA_ "GenSigStartValueInteger" SG_ 673 ICI_BtnID_B 255;
BA_ "U_CD542_MY2021_Tx" SG_ 673 ICI_BtnID_A 1;
BA_ "U_T6_MCA_MY2020_Tx" SG_ 673 ICI_BtnID_A 1;
BA_ "U_P702_MY2021_Tx" SG_ 673 ICI_BtnID_A 1;
BA_ "U_CX727_MY2021_Tx" SG_ 673 ICI_BtnID_A 1;
BA_ "GenSigSendType" SG_ 673 ICI_BtnID_A 3;
BA_ "GenSigStartValue" SG_ 673 ICI_BtnID_A 255;
BA_ "GenSigStartValueInteger" SG_ 673 ICI_BtnID_A 255;
BA_ "U_CD542_MY2021_Tx" SG_ 820 AhbStatGfhbFdbk_D_Actl 1;
BA_ "U_T6_MCA_MY2020_Tx" SG_ 820 AhbStatGfhbFdbk_D_Actl 1;
BA_ "U_P702_MY2021_Tx" SG_ 820 AhbStatGfhbFdbk_D_Actl 1;
BA_ "U_CX727_MY2021_Tx" SG_ 820 AhbStatGfhbFdbk_D_Actl 1;
BA_ "U_CD542_MY2021_Rx" SG_ 820 AhbStatGfhbFdbk_D_Actl 1;
BA_ "U_T6_MCA_MY2020_Rx" SG_ 820 AhbStatGfhbFdbk_D_Actl 1;
BA_ "U_P702_MY2021_Rx" SG_ 820 AhbStatGfhbFdbk_D_Actl 1;
BA_ "U_CX727_MY2021_Rx" SG_ 820 AhbStatGfhbFdbk_D_Actl 1;
BA_ "GenSigSendType" SG_ 820 AhbStatGfhbFdbk_D_Actl 3;
BA_ "U_CD542_MY2021_Tx" SG_ 820 HeadLghtDrvSide_B_Stat 1;
BA_ "U_T6_MCA_MY2020_Tx" SG_ 820 HeadLghtDrvSide_B_Stat 1;
BA_ "U_P702_MY2021_Tx" SG_ 820 HeadLghtDrvSide_B_Stat 1;
BA_ "U_CX727_MY2021_Tx" SG_ 820 HeadLghtDrvSide_B_Stat 1;
BA_ "GenSigSendType" SG_ 820 HeadLghtDrvSide_B_Stat 3;
BA_ "U_CD542_MY2021_Tx" SG_ 820 HeadLghtHiOn_B_StatHcm 1;
BA_ "U_T6_MCA_MY2020_Tx" SG_ 820 HeadLghtHiOn_B_StatHcm 1;
BA_ "U_P702_MY2021_Tx" SG_ 820 HeadLghtHiOn_B_StatHcm 1;
BA_ "U_CX727_MY2021_Tx" SG_ 820 HeadLghtHiOn_B_StatHcm 1;
BA_ "GenSigSendType" SG_ 820 HeadLghtHiOn_B_StatHcm 3;
BA_ "U_CD542_MY2021_Tx" SG_ 820 Adaptive_Hdlmp_Fault 1;
BA_ "U_T6_MCA_MY2020_Tx" SG_ 820 Adaptive_Hdlmp_Fault 1;
BA_ "U_P702_MY2021_Tx" SG_ 820 Adaptive_Hdlmp_Fault 1;
BA_ "U_CX727_MY2021_Tx" SG_ 820 Adaptive_Hdlmp_Fault 1;
BA_ "GenSigSendType" SG_ 820 Adaptive_Hdlmp_Fault 3;
BA_ "GenSigSendType" SG_ 1073 CamraFrntBttn_D_Stat 3;
BA_ "GenSigSendType" SG_ 1073 BrkDrvMde_D_Rq 3;
BA_ "GenSigSendType" SG_ 1073 SteEffort_D_Rq 3;
BA_ "GenSigSendType" SG_ 1073 AutoHoldSwtch_D_Stat 3;
BA_ "U_CD542_MY2021_Rx" SG_ 1073 HMI_HMIMode_St_UB 1;
BA_ "U_T6_MCA_MY2020_Rx" SG_ 1073 HMI_HMIMode_St_UB 1;
BA_ "U_P702_MY2021_Rx" SG_ 1073 HMI_HMIMode_St_UB 1;
BA_ "U_CX727_MY2021_Rx" SG_ 1073 HMI_HMIMode_St_UB 1;
BA_ "U_CD542_MY2021_Rx" SG_ 1073 HMI_HMIMode_St 1;
BA_ "U_T6_MCA_MY2020_Rx" SG_ 1073 HMI_HMIMode_St 1;
BA_ "U_P702_MY2021_Rx" SG_ 1073 HMI_HMIMode_St 1;
BA_ "U_CX727_MY2021_Rx" SG_ 1073 HMI_HMIMode_St 1;
BA_ "GenSigSendType" SG_ 1073 HMI_HMIMode_St 3;
BA_ "WakeupSignal" SG_ 1073 HMI_HMIMode_St 1;
BA_ "U_CD542_MY2021_Rx" SG_ 1073 Veh_Lock_Requestor_UB 1;
BA_ "U_T6_MCA_MY2020_Rx" SG_ 1073 Veh_Lock_Requestor_UB 1;
BA_ "U_P702_MY2021_Rx" SG_ 1073 Veh_Lock_Requestor_UB 1;
BA_ "U_CX727_MY2021_Rx" SG_ 1073 Veh_Lock_Requestor_UB 1;
BA_ "U_CD542_MY2021_Rx" SG_ 1073 Veh_Lock_EvNum_UB 1;
BA_ "U_T6_MCA_MY2020_Rx" SG_ 1073 Veh_Lock_EvNum_UB 1;
BA_ "U_P702_MY2021_Rx" SG_ 1073 Veh_Lock_EvNum_UB 1;
BA_ "U_CX727_MY2021_Rx" SG_ 1073 Veh_Lock_EvNum_UB 1;
BA_ "U_CD542_MY2021_Rx" SG_ 1073 Veh_Lock_Status_UB 1;
BA_ "U_T6_MCA_MY2020_Rx" SG_ 1073 Veh_Lock_Status_UB 1;
BA_ "U_P702_MY2021_Rx" SG_ 1073 Veh_Lock_Status_UB 1;
BA_ "U_CX727_MY2021_Rx" SG_ 1073 Veh_Lock_Status_UB 1;
BA_ "GenSigSendType" SG_ 1073 Veh_Lock_Sub_Id 3;
BA_ "U_CD542_MY2021_Rx" SG_ 1073 Veh_Lock_Status 1;
BA_ "U_T6_MCA_MY2020_Rx" SG_ 1073 Veh_Lock_Status 1;
BA_ "U_P702_MY2021_Rx" SG_ 1073 Veh_Lock_Status 1;
BA_ "U_CX727_MY2021_Rx" SG_ 1073 Veh_Lock_Status 1;
BA_ "GenSigSendType" SG_ 1073 Veh_Lock_Status 3;
BA_ "GenSigStartValue" SG_ 1073 Veh_Lock_Status 1;
BA_ "GenSigStartValueInteger" SG_ 1073 Veh_Lock_Status 1;
BA_ "WakeupSignal" SG_ 1073 Veh_Lock_Status 1;
BA_ "U_CD542_MY2021_Rx" SG_ 1073 Veh_Lock_Requestor 1;
BA_ "U_T6_MCA_MY2020_Rx" SG_ 1073 Veh_Lock_Requestor 1;
BA_ "U_P702_MY2021_Rx" SG_ 1073 Veh_Lock_Requestor 1;
BA_ "U_CX727_MY2021_Rx" SG_ 1073 Veh_Lock_Requestor 1;
BA_ "GenSigSendType" SG_ 1073 Veh_Lock_Requestor 3;
BA_ "WakeupSignal" SG_ 1073 Veh_Lock_Requestor 1;
BA_ "U_CD542_MY2021_Rx" SG_ 1073 Veh_Lock_EvNum 1;
BA_ "U_T6_MCA_MY2020_Rx" SG_ 1073 Veh_Lock_EvNum 1;
BA_ "U_P702_MY2021_Rx" SG_ 1073 Veh_Lock_EvNum 1;
BA_ "U_CX727_MY2021_Rx" SG_ 1073 Veh_Lock_EvNum 1;
BA_ "GenSigSendType" SG_ 1073 Veh_Lock_EvNum 3;
BA_ "WakeupSignal" SG_ 1073 Veh_Lock_EvNum 1;
BA_ "GenSigSendType" SG_ 1073 Tire_Press_System_Stat 3;
BA_ "GenSigSendType" SG_ 1073 DISPLAY_SPEED_OFFSET 3;
BA_ "GenSigSendType" SG_ 1073 DISPLAY_SPEED_SCALING 3;
BA_ "U_CD542_MY2021_Rx" SG_ 1073 SteWhlHeat_D_Rq_UB 1;
BA_ "U_T6_MCA_MY2020_Rx" SG_ 1073 SteWhlHeat_D_Rq_UB 1;
BA_ "U_P702_MY2021_Rx" SG_ 1073 SteWhlHeat_D_Rq_UB 1;
BA_ "U_CX727_MY2021_Rx" SG_ 1073 SteWhlHeat_D_Rq_UB 1;
BA_ "U_CD542_MY2021_Rx" SG_ 1073 SteWhlHeat_D_Rq 1;
BA_ "U_T6_MCA_MY2020_Rx" SG_ 1073 SteWhlHeat_D_Rq 1;
BA_ "U_P702_MY2021_Rx" SG_ 1073 SteWhlHeat_D_Rq 1;
BA_ "U_CX727_MY2021_Rx" SG_ 1073 SteWhlHeat_D_Rq 1;
BA_ "GenSigSendType" SG_ 1073 SteWhlHeat_D_Rq 3;
BA_ "U_CD542_MY2021_Rx" SG_ 1091 TrlrLampCnnct_B_Actl 1;
BA_ "U_T6_MCA_MY2020_Rx" SG_ 1091 TrlrLampCnnct_B_Actl 1;
BA_ "GenSigSendType" SG_ 1068 EngStrtInhbt_B_RqBatt 3;
BA_ "GenSigSendType" SG_ 1068 BattULoChrg_D_Rq 3;
BA_ "GenSigSendType" SG_ 1068 PwSysULoFalt_D_Stat 3;
BA_ "WakeupSignal" SG_ 1068 PwSysULoFalt_D_Stat 1;
BA_ "GenSigSendType" SG_ 1068 Shed_T_Eng_Off_B 3;
BA_ "U_CD542_MY2021_Rx" SG_ 1068 Shed_Feature_Group_ID 1;
BA_ "U_T6_MCA_MY2020_Rx" SG_ 1068 Shed_Feature_Group_ID 1;
BA_ "GenSigSendType" SG_ 1068 Shed_Feature_Group_ID 3;
BA_ "WakeupSignal" SG_ 1068 Shed_Feature_Group_ID 1;
BA_ "GenSigSendType" SG_ 1068 Shed_Drain_Eng_Off_B 3;
BA_ "U_CD542_MY2021_Rx" SG_ 1068 Shed_Level_Req 1;
BA_ "U_T6_MCA_MY2020_Rx" SG_ 1068 Shed_Level_Req 1;
BA_ "U_P702_MY2021_Rx" SG_ 1068 Shed_Level_Req 1;
BA_ "U_CX727_MY2021_Rx" SG_ 1068 Shed_Level_Req 1;
BA_ "GenSigSendType" SG_ 1068 Shed_Level_Req 3;
BA_ "WakeupSignal" SG_ 1068 Shed_Level_Req 1;
BA_ "GenSigSendType" SG_ 1068 ChargeMode 3;
BA_ "GenSigSendType" SG_ 1068 IdleSpeedIncrease_El 3;
BA_ "GenSigSendType" SG_ 1068 Batt_Lo_SoC_B 3;
BA_ "GenSigSendType" SG_ 1068 PeriodicElLoad_B_Stat 3;
BA_ "U_CD542_MY2021_Rx" SG_ 1068 Batt_Crit_SoC_B 1;
BA_ "U_T6_MCA_MY2020_Rx" SG_ 1068 Batt_Crit_SoC_B 1;
BA_ "U_P702_MY2021_Rx" SG_ 1068 Batt_Crit_SoC_B 1;
BA_ "U_CX727_MY2021_Rx" SG_ 1068 Batt_Crit_SoC_B 1;
BA_ "GenSigSendType" SG_ 1068 Batt_Crit_SoC_B 3;
BA_ "GenSigSendType" SG_ 1068 ULoRgenTestMde_B_Rq 3;
BA_ "ContentDependant" SG_ 611 AwdStat_D_RqDsply 1;
BA_ "U_T6_MCA_MY2020_Rx" SG_ 611 AwdSrvcRqd_B_Rq 1;
BA_ "U_P702_MY2021_Rx" SG_ 611 AwdSrvcRqd_B_Rq 1;
BA_ "U_CX727_MY2021_Rx" SG_ 611 AwdSrvcRqd_B_Rq 1;
BA_ "ContentDependant" SG_ 611 AwdSrvcRqd_B_Rq 1;
BA_ "ContentDependant" SG_ 611 AwdLck_Tq_Rq 1;
BA_ "GenSigStartValue" SG_ 611 TrnAout_Tq_RqMx 8191;
BA_ "GenSigStartValueInteger" SG_ 611 TrnAout_Tq_RqMx 8191;
BA_ "U_T6_MCA_MY2020_Rx" SG_ 611 AwdLoLamp_D_RqDsply 1;
BA_ "U_P702_MY2021_Rx" SG_ 611 AwdLoLamp_D_RqDsply 1;
BA_ "U_T6_MCA_MY2020_Rx" SG_ 611 AwdHiLamp_D_RqDsply 1;
BA_ "U_P702_MY2021_Rx" SG_ 611 AwdHiLamp_D_RqDsply 1;
BA_ "U_T6_MCA_MY2020_Rx" SG_ 611 AwdAutoLamp_D_RqDsply 1;
BA_ "U_P702_MY2021_Rx" SG_ 611 AwdAutoLamp_D_RqDsply 1;
BA_ "U_T6_MCA_MY2020_Rx" SG_ 611 Awd2wdLamp_D_RqDsply 1;
BA_ "U_P702_MY2021_Rx" SG_ 611 Awd2wdLamp_D_RqDsply 1;
BA_ "GenSigStartValue" SG_ 611 AwdRnge_D_Actl 7;
BA_ "GenSigStartValueInteger" SG_ 611 AwdRnge_D_Actl 7;
BA_ "U_CD542_MY2021_Rx" SG_ 578 immoSecureIdleMode 1;
BA_ "U_T6_MCA_MY2020_Rx" SG_ 578 immoSecureIdleMode 1;
BA_ "U_P702_MY2021_Rx" SG_ 578 immoSecureIdleMode 1;
BA_ "U_CX727_MY2021_Rx" SG_ 578 immoSecureIdleMode 1;
BA_ "GenSigSendType" SG_ 578 immoSecureIdleMode 3;
BA_ "GenSigSendType" SG_ 578 FuelPumpPwr_D_Stat 3;
BA_ "GenSigStartValue" SG_ 578 BattULo_U_Actl 255;
BA_ "GenSigStartValueInteger" SG_ 578 BattULo_U_Actl 255;
BA_ "U_CD542_MY2021_Rx" SG_ 578 PrkLckCtl_B_Enbl 1;
BA_ "U_T6_MCA_MY2020_Rx" SG_ 578 PrkLckCtl_B_Enbl 1;
BA_ "U_P702_MY2021_Rx" SG_ 578 PrkLckCtl_B_Enbl 1;
BA_ "U_CX727_MY2021_Rx" SG_ 578 PrkLckCtl_B_Enbl 1;
BA_ "GenSigSendType" SG_ 578 PrkLckCtl_B_Enbl 3;
BA_ "GenSigSendType" SG_ 578 PrkLckCtlMsgTxt_D_Rq 3;
BA_ "WakeupSignal" SG_ 578 PrkLckCtlMsgTxt_D_Rq 1;
BA_ "WakeupSignal" SG_ 578 PrkLckCtlAvail_T_Stat 1;
BA_ "U_CD542_MY2021_Rx" SG_ 578 BrkTrnShifLck_B_Stat 1;
BA_ "U_T6_MCA_MY2020_Rx" SG_ 578 BrkTrnShifLck_B_Stat 1;
BA_ "U_P702_MY2021_Rx" SG_ 578 BrkTrnShifLck_B_Stat 1;
BA_ "U_CX727_MY2021_Rx" SG_ 578 BrkTrnShifLck_B_Stat 1;
BA_ "GenSigSendType" SG_ 578 BrkTrnShifLck_B_Stat 3;
BA_ "U_CD542_MY2021_Rx" SG_ 578 DriverCrankingReq 1;
BA_ "U_T6_MCA_MY2020_Rx" SG_ 578 DriverCrankingReq 1;
BA_ "U_P702_MY2021_Rx" SG_ 578 DriverCrankingReq 1;
BA_ "U_CX727_MY2021_Rx" SG_ 578 DriverCrankingReq 1;
BA_ "GenSigSendType" SG_ 578 DriverCrankingReq 3;
BA_ "GenSigSendType" SG_ 578 ReFuelSwtchStat_D_Actl 3;
BA_ "WakeupSignal" SG_ 578 ReFuelSwtchStat_D_Actl 1;
BA_ "GenSigSendType" SG_ 578 DcacElPw_D_Rq 3;
BA_ "GenSigStartValue" SG_ 578 BattULo_I_Actl 16383;
BA_ "GenSigStartValueInteger" SG_ 578 BattULo_I_Actl 16383;
BA_ "GenSigSendType" SG_ 560 SelDrvMdeSwtch_D_Stat3 3;
BA_ "ContentDependant" SG_ 560 SelDrvMdeSwtch_D_Stat3 1;
BA_ "U_CD542_MY2021_Rx" SG_ 560 TrnSrvcRqd_B_Rq 1;
BA_ "U_T6_MCA_MY2020_Rx" SG_ 560 TrnSrvcRqd_B_Rq 1;
BA_ "U_P702_MY2021_Rx" SG_ 560 TrnSrvcRqd_B_Rq 1;
BA_ "U_CX727_MY2021_Rx" SG_ 560 TrnSrvcRqd_B_Rq 1;
BA_ "GenSigSendType" SG_ 560 TrnSrvcRqd_B_Rq 3;
BA_ "ContentDependant" SG_ 560 TrnSrvcRqd_B_Rq 1;
BA_ "GenSigSendType" SG_ 560 TrnCnvtClu_D_Actl 3;
BA_ "ContentDependant" SG_ 560 TrnCnvtClu_D_Actl 1;
BA_ "GenSigSendType" SG_ 560 TrnShifActv_B_Actl 3;
BA_ "ContentDependant" SG_ 560 TrnShifActv_B_Actl 1;
BA_ "U_CD542_MY2021_Rx" SG_ 560 GearLvrPos_D_Actl 1;
BA_ "U_T6_MCA_MY2020_Rx" SG_ 560 GearLvrPos_D_Actl 1;
BA_ "U_P702_MY2021_Rx" SG_ 560 GearLvrPos_D_Actl 1;
BA_ "U_CX727_MY2021_Rx" SG_ 560 GearLvrPos_D_Actl 1;
BA_ "GenSigSendType" SG_ 560 GearLvrPos_D_Actl 3;
BA_ "GenSigStartValue" SG_ 560 GearLvrPos_D_Actl 14;
BA_ "GenSigStartValueInteger" SG_ 560 GearLvrPos_D_Actl 14;
BA_ "GenSigStartValue" SG_ 560 GboxOil_Te_Actl 254;
BA_ "ContentDependant" SG_ 560 GboxOil_Te_Actl 1;
BA_ "GenSigStartValueInteger" SG_ 560 GboxOil_Te_Actl 254;
BA_ "U_CD542_MY2021_Rx" SG_ 359 ElPw_D_StatStrtStop 1;
BA_ "U_T6_MCA_MY2020_Rx" SG_ 359 ElPw_D_StatStrtStop 1;
BA_ "U_P702_MY2021_Rx" SG_ 359 ElPw_D_StatStrtStop 1;
BA_ "U_CX727_MY2021_Rx" SG_ 359 ElPw_D_StatStrtStop 1;
BA_ "ContentDependant" SG_ 359 TrnAin_Tq_Actl 1;
BA_ "U_CD542_MY2021_Rx" SG_ 359 PrplWhlTot2_Tq_Actl 1;
BA_ "U_T6_MCA_MY2020_Rx" SG_ 359 PrplWhlTot2_Tq_Actl 1;
BA_ "U_P702_MY2021_Rx" SG_ 359 PrplWhlTot2_Tq_Actl 1;
BA_ "U_CX727_MY2021_Rx" SG_ 359 PrplWhlTot2_Tq_Actl 1;
BA_ "U_CD542_MY2021_Rx" SG_ 359 PwPckTq_D_Stat 1;
BA_ "U_T6_MCA_MY2020_Rx" SG_ 359 PwPckTq_D_Stat 1;
BA_ "U_P702_MY2021_Rx" SG_ 359 PwPckTq_D_Stat 1;
BA_ "U_CX727_MY2021_Rx" SG_ 359 PwPckTq_D_Stat 1;
BA_ "U_CD542_MY2021_Rx" SG_ 359 ElPw_D_Stat 1;
BA_ "U_T6_MCA_MY2020_Rx" SG_ 359 ElPw_D_Stat 1;
BA_ "U_P702_MY2021_Rx" SG_ 359 ElPw_D_Stat 1;
BA_ "U_CX727_MY2021_Rx" SG_ 359 ElPw_D_Stat 1;
BA_ "MetaData" SG_ 359 TrnAinTq_D_Qf 1;
BA_ "ContentDependant" SG_ 359 TrnAinTq_D_Qf 1;
BA_ "U_CD542_MY2021_Rx" SG_ 357 BPedDrvAppl_D_QF 1;
BA_ "U_T6_MCA_MY2020_Rx" SG_ 357 BPedDrvAppl_D_QF 1;
BA_ "U_P702_MY2021_Rx" SG_ 357 BPedDrvAppl_D_QF 1;
BA_ "U_CX727_MY2021_Rx" SG_ 357 BPedDrvAppl_D_QF 1;
BA_ "GenSigSendType" SG_ 357 BPedDrvAppl_D_QF 3;
BA_ "GenSigStartValue" SG_ 357 BPedDrvAppl_D_QF 1;
BA_ "MetaData" SG_ 357 BPedDrvAppl_D_QF 1;
BA_ "GenSigStartValueInteger" SG_ 357 BPedDrvAppl_D_QF 1;
BA_ "GenSigSendType" SG_ 357 CmbbDeny_B_ActlPrpl 3;
BA_ "GenSigSendType" SG_ 357 PrplTqMnSat_B_Actl 3;
BA_ "U_CD542_MY2021_Rx" SG_ 357 BpedDrvAppl_D_Actl 1;
BA_ "U_T6_MCA_MY2020_Rx" SG_ 357 BpedDrvAppl_D_Actl 1;
BA_ "U_P702_MY2021_Rx" SG_ 357 BpedDrvAppl_D_Actl 1;
BA_ "U_CX727_MY2021_Rx" SG_ 357 BpedDrvAppl_D_Actl 1;
BA_ "GenSigSendType" SG_ 357 BpedDrvAppl_D_Actl 3;
BA_ "GenSigStartValue" SG_ 357 BpedDrvAppl_D_Actl 1;
BA_ "GenSigStartValueInteger" SG_ 357 BpedDrvAppl_D_Actl 1;
BA_ "GenSigSendType" SG_ 357 CmbbEngTqMn_B_Actl 3;
BA_ "GenSigSendType" SG_ 357 AccEngStat_D_Actl 3;
BA_ "GenSigSendType" SG_ 357 CcMde_D_Actl 3;
BA_ "U_CD542_MY2021_Rx" SG_ 357 CcStat_D_Actl 1;
BA_ "U_T6_MCA_MY2020_Rx" SG_ 357 CcStat_D_Actl 1;
BA_ "U_P702_MY2021_Rx" SG_ 357 CcStat_D_Actl 1;
BA_ "U_CX727_MY2021_Rx" SG_ 357 CcStat_D_Actl 1;
BA_ "GenSigSendType" SG_ 357 CcStat_D_Actl 3;
BA_ "U_CD542_MY2021_Rx" SG_ 357 CcOvrrdActv_B_Actl 1;
BA_ "U_T6_MCA_MY2020_Rx" SG_ 357 CcOvrrdActv_B_Actl 1;
BA_ "U_P702_MY2021_Rx" SG_ 357 CcOvrrdActv_B_Actl 1;
BA_ "U_CX727_MY2021_Rx" SG_ 357 CcOvrrdActv_B_Actl 1;
BA_ "GenSigSendType" SG_ 357 CcOvrrdActv_B_Actl 3;
BA_ "GenSigSendType" SG_ 357 AccStopMde_D_Rq 3;
BA_ "GenSigStartValueInteger" SG_ 390 AccBrkTot_A_Rq 5129;
BA_ "U_CD542_MY2021_Rx" SG_ 390 Cmbb_B_Enbl 1;
BA_ "U_T6_MCA_MY2020_Rx" SG_ 390 Cmbb_B_Enbl 1;
BA_ "U_P702_MY2021_Rx" SG_ 390 Cmbb_B_Enbl 1;
BA_ "U_CX727_MY2021_Rx" SG_ 390 Cmbb_B_Enbl 1;
BA_ "U_CD542_MY2021_Rx" SG_ 390 CmbbOvrrd_B_RqDrv 1;
BA_ "U_T6_MCA_MY2020_Rx" SG_ 390 CmbbOvrrd_B_RqDrv 1;
BA_ "U_P702_MY2021_Rx" SG_ 390 CmbbOvrrd_B_RqDrv 1;
BA_ "U_CX727_MY2021_Rx" SG_ 390 CmbbOvrrd_B_RqDrv 1;
BA_ "U_CD542_MY2021_Rx" SG_ 390 CmbbDeny_B_Actl 1;
BA_ "U_T6_MCA_MY2020_Rx" SG_ 390 CmbbDeny_B_Actl 1;
BA_ "U_P702_MY2021_Rx" SG_ 390 CmbbDeny_B_Actl 1;
BA_ "U_CX727_MY2021_Rx" SG_ 390 CmbbDeny_B_Actl 1;
BA_ "WakeupSignal" SG_ 390 AccResumEnbl_B_Rq 1;
BA_ "U_T6_MCA_MY2020_Rx" SG_ 1071 CluPdlPosPcMeas_D_Qf 1;
BA_ "U_P702_MY2021_Rx" SG_ 1071 CluPdlPosPcMeas_D_Qf 1;
BA_ "U_CX727_MY2021_Rx" SG_ 1071 CluPdlPosPcMeas_D_Qf 1;
BA_ "GenSigStartValue" SG_ 1071 CluPdlPosPcMeas_D_Qf 1;
BA_ "MetaData" SG_ 1071 CluPdlPosPcMeas_D_Qf 1;
BA_ "ContentDependant" SG_ 1071 CluPdlPosPcMeas_D_Qf 1;
BA_ "GenSigStartValueInteger" SG_ 1071 CluPdlPosPcMeas_D_Qf 1;
BA_ "U_T6_MCA_MY2020_Rx" SG_ 1071 CluPdlPos_Pc_Meas 1;
BA_ "U_P702_MY2021_Rx" SG_ 1071 CluPdlPos_Pc_Meas 1;
BA_ "U_CX727_MY2021_Rx" SG_ 1071 CluPdlPos_Pc_Meas 1;
BA_ "ContentDependant" SG_ 1071 CluPdlPos_Pc_Meas 1;
BA_ "GenSigSendType" SG_ 1072 TrlrAidCancl_B_Rq 3;
BA_ "GenSigSendType" SG_ 1072 HdcOn_B_Rq 3;
BA_ "GenSigSendType" SG_ 1072 HsaMde_D_Rq 3;
BA_ "GenSigStartValue" SG_ 1072 HsaMde_D_Rq 1;
BA_ "GenSigStartValueInteger" SG_ 1072 HsaMde_D_Rq 1;
BA_ "GenSigSendType" SG_ 1072 LscmbbStat_B_Actl 3;
BA_ "U_CD542_MY2021_Rx" SG_ 1072 Outside_Air_Temp_Stat_UB 1;
BA_ "U_T6_MCA_MY2020_Rx" SG_ 1072 Outside_Air_Temp_Stat_UB 1;
BA_ "U_CD542_MY2021_Rx" SG_ 1072 Outside_Air_Temp_Stat 1;
BA_ "U_T6_MCA_MY2020_Rx" SG_ 1072 Outside_Air_Temp_Stat 1;
BA_ "GenSigSendType" SG_ 1072 Outside_Air_Temp_Stat 3;
BA_ "GenSigStartValue" SG_ 1072 Outside_Air_Temp_Stat 254;
BA_ "GenSigStartValueInteger" SG_ 1072 Outside_Air_Temp_Stat 254;
BA_ "GenSigSendType" SG_ 1072 BulbChkActv_B_Stat 3;
BA_ "U_CD542_MY2021_Rx" SG_ 1072 OdometerMasterValue 1;
BA_ "U_T6_MCA_MY2020_Rx" SG_ 1072 OdometerMasterValue 1;
BA_ "U_P702_MY2021_Rx" SG_ 1072 OdometerMasterValue 1;
BA_ "U_CX727_MY2021_Rx" SG_ 1072 OdometerMasterValue 1;
BA_ "GenSigSendType" SG_ 1072 OdometerMasterValue 3;
BA_ "GenSigSendType" SG_ 1072 Fda_B_Stat 3;
BA_ "GenSigSendType" SG_ 1072 AccDeny_B_RqIpc 3;
BA_ "GenSigSendType" SG_ 1072 AccEnbl_B_RqDrv 3;
BA_ "GenSigStartValue" SG_ 1072 AccEnbl_B_RqDrv 1;
BA_ "GenSigStartValueInteger" SG_ 1072 AccEnbl_B_RqDrv 1;
BA_ "GenSigSendType" SG_ 1072 DrvSlipCtlMde_D_Rq 3;
BA_ "U_CD542_MY2021_Rx" SG_ 1072 ePRNDL_MODE_UB 1;
BA_ "U_T6_MCA_MY2020_Rx" SG_ 1072 ePRNDL_MODE_UB 1;
BA_ "U_P702_MY2021_Rx" SG_ 1072 ePRNDL_MODE_UB 1;
BA_ "U_CX727_MY2021_Rx" SG_ 1072 ePRNDL_MODE_UB 1;
BA_ "U_CD542_MY2021_Rx" SG_ 1072 ePRNDL_MODE 1;
BA_ "U_T6_MCA_MY2020_Rx" SG_ 1072 ePRNDL_MODE 1;
BA_ "U_P702_MY2021_Rx" SG_ 1072 ePRNDL_MODE 1;
BA_ "U_CX727_MY2021_Rx" SG_ 1072 ePRNDL_MODE 1;
BA_ "GenSigSendType" SG_ 1072 ePRNDL_MODE 3;
BA_ "WakeupSignal" SG_ 1072 ePRNDL_MODE 1;
BA_ "GenSigSendType" SG_ 1072 TrlrBrkMde_D_Rq 3;
BA_ "GenSigSendType" SG_ 1072 TRLR_SWAY_CONFIG_CMD 3;
BA_ "GenSigSendType" SG_ 1072 TRAILER_BRAKE_CONFIG 3;
BA_ "MetaData" SG_ 1058 EngClntTe_D_Qf 1;
BA_ "U_CD542_MY2021_Rx" SG_ 1058 EngClnt_Te_Actl 1;
BA_ "U_T6_MCA_MY2020_Rx" SG_ 1058 EngClnt_Te_Actl 1;
BA_ "U_P702_MY2021_Rx" SG_ 1058 EngClnt_Te_Actl 1;
BA_ "U_CX727_MY2021_Rx" SG_ 1058 EngClnt_Te_Actl 1;
BA_ "ContentDependant" SG_ 1058 TrnTotTq_Rt_Est 1;
BA_ "ContentDependant" SG_ 1058 TrnTotLss_Tq_Est 1;
BA_ "GenSigSendType" SG_ 1082 EsaOn_B_Rq 3;
BA_ "GenSigStartValue" SG_ 1082 EsaOn_B_Rq 1;
BA_ "GenSigStartValueInteger" SG_ 1082 EsaOn_B_Rq 1;
BA_ "GenSigSendType" SG_ 1082 RearDiffLck_D_RqArb 3;
BA_ "GenSigStartValue" SG_ 1082 RearDiffLck_D_RqArb 3;
BA_ "GenSigStartValueInteger" SG_ 1082 RearDiffLck_D_RqArb 3;
BA_ "GenSigSendType" SG_ 1082 AwdMde_D_RqArb 3;
BA_ "GenSigStartValue" SG_ 1082 AwdMde_D_RqArb 5;
BA_ "GenSigStartValueInteger" SG_ 1082 AwdMde_D_RqArb 5;
BA_ "GenSigSendType" SG_ 1082 SelDrvMdeTxtReset_B_Rq 3;
BA_ "U_CD542_MY2021_Rx" SG_ 1082 DrvInputRequired_B_Rq_UB 1;
BA_ "U_T6_MCA_MY2020_Rx" SG_ 1082 DrvInputRequired_B_Rq_UB 1;
BA_ "U_P702_MY2021_Rx" SG_ 1082 DrvInputRequired_B_Rq_UB 1;
BA_ "U_CX727_MY2021_Rx" SG_ 1082 DrvInputRequired_B_Rq_UB 1;
BA_ "U_CD542_MY2021_Rx" SG_ 1082 DrvInputRequired_B_Rq 1;
BA_ "U_T6_MCA_MY2020_Rx" SG_ 1082 DrvInputRequired_B_Rq 1;
BA_ "U_P702_MY2021_Rx" SG_ 1082 DrvInputRequired_B_Rq 1;
BA_ "U_CX727_MY2021_Rx" SG_ 1082 DrvInputRequired_B_Rq 1;
BA_ "GenSigSendType" SG_ 1082 DrvInputRequired_B_Rq 3;
BA_ "WakeupSignal" SG_ 1082 DrvInputRequired_B_Rq 1;
BA_ "GenSigSendType" SG_ 1082 SelDrvMdeSwtch_D_Stat2 3;
BA_ "GenSigSendType" SG_ 1082 FapLcStopHold_B_Rq 3;
BA_ "GenSigSendType" SG_ 1082 SelDrvMdeDsply_B_Avail 3;
BA_ "GenSigSendType" SG_ 1082 AirSusp_D_RqDrv 3;
BA_ "GenSigSendType" SG_ 1082 AwdRnge_D_ActlIpc 3;
BA_ "GenSigStartValue" SG_ 1082 AwdRnge_D_ActlIpc 7;
BA_ "GenSigStartValueInteger" SG_ 1082 AwdRnge_D_ActlIpc 7;
BA_ "GenSigSendType" SG_ 1082 NtrlTowMdeEnbl_B_RqDrv 3;
BA_ "GenSigSendType" SG_ 1082 DrvSlipCtlMde_B_RqMyKey 3;
BA_ "GenSigSendType" SG_ 1082 AwdDrvMde_D_Rq 3;
BA_ "GenSigSendType" SG_ 1082 MetricActv_B_Actl 3;
BA_ "GenSigSendType" SG_ 1082 BrkLineLck_D_Rq 3;
BA_ "GenSigSendType" SG_ 1082 SuspDrvMde_D_Rq 3;
BA_ "GenSigSendType" SG_ 1082 SelDrvMdePt_D_Stat 3;
BA_ "U_CD542_MY2021_Tx" SG_ 1462 GSM_GWOnBoardTester 1;
BA_ "U_T6_MCA_MY2020_Tx" SG_ 1462 GSM_GWOnBoardTester 1;
BA_ "U_P702_MY2021_Tx" SG_ 1462 GSM_GWOnBoardTester 1;
BA_ "U_CX727_MY2021_Tx" SG_ 1462 GSM_GWOnBoardTester 1;
BA_ "GenSigStartValue" SG_ 1462 GSM_GWOnBoardTester 255;
BA_ "ContentDependant" SG_ 1462 GSM_GWOnBoardTester 1;
BA_ "GenSigStartValueInteger" SG_ 1462 GSM_GWOnBoardTester 255;
BA_ "U_CD542_MY2021_Tx" SG_ 1462 GSM_GWNMProxy 1;
BA_ "U_T6_MCA_MY2020_Tx" SG_ 1462 GSM_GWNMProxy 1;
BA_ "U_P702_MY2021_Tx" SG_ 1462 GSM_GWNMProxy 1;
BA_ "U_CX727_MY2021_Tx" SG_ 1462 GSM_GWNMProxy 1;
BA_ "GenSigStartValue" SG_ 1462 GSM_GWNMProxy 255;
BA_ "ContentDependant" SG_ 1462 GSM_GWNMProxy 1;
BA_ "GenSigStartValueInteger" SG_ 1462 GSM_GWNMProxy 255;
BA_ "U_CD542_MY2021_Tx" SG_ 1462 GSM_AutoSarNMReserved4 1;
BA_ "U_T6_MCA_MY2020_Tx" SG_ 1462 GSM_AutoSarNMReserved4 1;
BA_ "U_P702_MY2021_Tx" SG_ 1462 GSM_AutoSarNMReserved4 1;
BA_ "U_CX727_MY2021_Tx" SG_ 1462 GSM_AutoSarNMReserved4 1;
BA_ "GenSigStartValue" SG_ 1462 GSM_AutoSarNMReserved4 255;
BA_ "ContentDependant" SG_ 1462 GSM_AutoSarNMReserved4 1;
BA_ "GenSigStartValueInteger" SG_ 1462 GSM_AutoSarNMReserved4 255;
BA_ "U_CD542_MY2021_Tx" SG_ 1462 GSM_AutoSarNMReserved3 1;
BA_ "U_T6_MCA_MY2020_Tx" SG_ 1462 GSM_AutoSarNMReserved3 1;
BA_ "U_P702_MY2021_Tx" SG_ 1462 GSM_AutoSarNMReserved3 1;
BA_ "U_CX727_MY2021_Tx" SG_ 1462 GSM_AutoSarNMReserved3 1;
BA_ "GenSigStartValue" SG_ 1462 GSM_AutoSarNMReserved3 255;
BA_ "ContentDependant" SG_ 1462 GSM_AutoSarNMReserved3 1;
BA_ "GenSigStartValueInteger" SG_ 1462 GSM_AutoSarNMReserved3 255;
BA_ "U_CD542_MY2021_Tx" SG_ 1462 GSM_AutoSarNMReserved2 1;
BA_ "U_T6_MCA_MY2020_Tx" SG_ 1462 GSM_AutoSarNMReserved2 1;
BA_ "U_P702_MY2021_Tx" SG_ 1462 GSM_AutoSarNMReserved2 1;
BA_ "U_CX727_MY2021_Tx" SG_ 1462 GSM_AutoSarNMReserved2 1;
BA_ "GenSigStartValue" SG_ 1462 GSM_AutoSarNMReserved2 255;
BA_ "ContentDependant" SG_ 1462 GSM_AutoSarNMReserved2 1;
BA_ "GenSigStartValueInteger" SG_ 1462 GSM_AutoSarNMReserved2 255;
BA_ "U_CD542_MY2021_Tx" SG_ 1462 GSM_AutoSarNMReserved1 1;
BA_ "U_T6_MCA_MY2020_Tx" SG_ 1462 GSM_AutoSarNMReserved1 1;
BA_ "U_P702_MY2021_Tx" SG_ 1462 GSM_AutoSarNMReserved1 1;
BA_ "U_CX727_MY2021_Tx" SG_ 1462 GSM_AutoSarNMReserved1 1;
BA_ "GenSigStartValue" SG_ 1462 GSM_AutoSarNMReserved1 255;
BA_ "ContentDependant" SG_ 1462 GSM_AutoSarNMReserved1 1;
BA_ "GenSigStartValueInteger" SG_ 1462 GSM_AutoSarNMReserved1 255;
BA_ "U_CD542_MY2021_Tx" SG_ 1462 GSM_AutoSarNMNodeId 1;
BA_ "U_T6_MCA_MY2020_Tx" SG_ 1462 GSM_AutoSarNMNodeId 1;
BA_ "U_P702_MY2021_Tx" SG_ 1462 GSM_AutoSarNMNodeId 1;
BA_ "U_CX727_MY2021_Tx" SG_ 1462 GSM_AutoSarNMNodeId 1;
BA_ "GenSigStartValue" SG_ 1462 GSM_AutoSarNMNodeId 182;
BA_ "ContentDependant" SG_ 1462 GSM_AutoSarNMNodeId 1;
BA_ "GenSigStartValueInteger" SG_ 1462 GSM_AutoSarNMNodeId 182;
BA_ "U_CD542_MY2021_Tx" SG_ 1462 GSM_AutoSarNMControl 1;
BA_ "U_T6_MCA_MY2020_Tx" SG_ 1462 GSM_AutoSarNMControl 1;
BA_ "U_P702_MY2021_Tx" SG_ 1462 GSM_AutoSarNMControl 1;
BA_ "U_CX727_MY2021_Tx" SG_ 1462 GSM_AutoSarNMControl 1;
BA_ "ContentDependant" SG_ 1462 GSM_AutoSarNMControl 1;
BA_ "U_CD542_MY2021_Rx" SG_ 92 TrnSbwSysHlth_D_Actl 1;
BA_ "U_T6_MCA_MY2020_Rx" SG_ 92 TrnSbwSysHlth_D_Actl 1;
BA_ "U_P702_MY2021_Rx" SG_ 92 TrnSbwSysHlth_D_Actl 1;
BA_ "U_CX727_MY2021_Rx" SG_ 92 TrnSbwSysHlth_D_Actl 1;
BA_ "GenSigStartValue" SG_ 92 TrnSbwSysHlth_D_Actl 1;
BA_ "ContentDependant" SG_ 92 TrnSbwSysHlth_D_Actl 1;
BA_ "GenSigStartValueInteger" SG_ 92 TrnSbwSysHlth_D_Actl 1;
BA_ "U_CD542_MY2021_Rx" SG_ 92 TrnDtpCmd_D_Actl 1;
BA_ "U_T6_MCA_MY2020_Rx" SG_ 92 TrnDtpCmd_D_Actl 1;
BA_ "U_P702_MY2021_Rx" SG_ 92 TrnDtpCmd_D_Actl 1;
BA_ "U_CX727_MY2021_Rx" SG_ 92 TrnDtpCmd_D_Actl 1;
BA_ "GenSigStartValue" SG_ 92 TrnDtpCmd_D_Actl 1;
BA_ "ContentDependant" SG_ 92 TrnDtpCmd_D_Actl 1;
BA_ "GenSigStartValueInteger" SG_ 92 TrnDtpCmd_D_Actl 1;
BA_ "WakeupSignal" SG_ 92 TrnDtpCmd_D_Actl 1;
BA_ "U_CD542_MY2021_Rx" SG_ 92 GearSelLck_D_Rq 1;
BA_ "U_T6_MCA_MY2020_Rx" SG_ 92 GearSelLck_D_Rq 1;
BA_ "U_P702_MY2021_Rx" SG_ 92 GearSelLck_D_Rq 1;
BA_ "U_CX727_MY2021_Rx" SG_ 92 GearSelLck_D_Rq 1;
BA_ "U_CD542_MY2021_Rx" SG_ 92 TrnGearCmd_No_Cs 1;
BA_ "U_T6_MCA_MY2020_Rx" SG_ 92 TrnGearCmd_No_Cs 1;
BA_ "U_P702_MY2021_Rx" SG_ 92 TrnGearCmd_No_Cs 1;
BA_ "U_CX727_MY2021_Rx" SG_ 92 TrnGearCmd_No_Cs 1;
BA_ "MetaData" SG_ 92 TrnGearCmd_No_Cs 1;
BA_ "ContentDependant" SG_ 92 TrnGearCmd_No_Cs 1;
BA_ "U_CD542_MY2021_Rx" SG_ 92 TrnValidGear_D_Cnfm 1;
BA_ "U_T6_MCA_MY2020_Rx" SG_ 92 TrnValidGear_D_Cnfm 1;
BA_ "U_P702_MY2021_Rx" SG_ 92 TrnValidGear_D_Cnfm 1;
BA_ "U_CX727_MY2021_Rx" SG_ 92 TrnValidGear_D_Cnfm 1;
BA_ "ContentDependant" SG_ 92 TrnValidGear_D_Cnfm 1;
BA_ "U_CD542_MY2021_Rx" SG_ 92 TrnNtrlTowCmd_D_Actl 1;
BA_ "U_T6_MCA_MY2020_Rx" SG_ 92 TrnNtrlTowCmd_D_Actl 1;
BA_ "U_P702_MY2021_Rx" SG_ 92 TrnNtrlTowCmd_D_Actl 1;
BA_ "U_CX727_MY2021_Rx" SG_ 92 TrnNtrlTowCmd_D_Actl 1;
BA_ "ContentDependant" SG_ 92 TrnNtrlTowCmd_D_Actl 1;
BA_ "U_CD542_MY2021_Rx" SG_ 92 TrnGearCmd_Pc_ActlPt 1;
BA_ "U_T6_MCA_MY2020_Rx" SG_ 92 TrnGearCmd_Pc_ActlPt 1;
BA_ "U_P702_MY2021_Rx" SG_ 92 TrnGearCmd_Pc_ActlPt 1;
BA_ "U_CX727_MY2021_Rx" SG_ 92 TrnGearCmd_Pc_ActlPt 1;
BA_ "ContentDependant" SG_ 92 TrnGearCmd_Pc_ActlPt 1;
BA_ "U_CD542_MY2021_Rx" SG_ 92 TrnGear_D_RqPt 1;
BA_ "U_T6_MCA_MY2020_Rx" SG_ 92 TrnGear_D_RqPt 1;
BA_ "U_P702_MY2021_Rx" SG_ 92 TrnGear_D_RqPt 1;
BA_ "U_CX727_MY2021_Rx" SG_ 92 TrnGear_D_RqPt 1;
BA_ "ContentDependant" SG_ 92 TrnGear_D_RqPt 1;
BA_ "U_CD542_MY2021_Rx" SG_ 92 TrnCmdState_B_Actl 1;
BA_ "U_T6_MCA_MY2020_Rx" SG_ 92 TrnCmdState_B_Actl 1;
BA_ "U_P702_MY2021_Rx" SG_ 92 TrnCmdState_B_Actl 1;
BA_ "U_CX727_MY2021_Rx" SG_ 92 TrnCmdState_B_Actl 1;
BA_ "ContentDependant" SG_ 92 TrnCmdState_B_Actl 1;
BA_ "U_CD542_MY2021_Rx" SG_ 92 TrnCmdCnt_B_Actl 1;
BA_ "U_T6_MCA_MY2020_Rx" SG_ 92 TrnCmdCnt_B_Actl 1;
BA_ "U_P702_MY2021_Rx" SG_ 92 TrnCmdCnt_B_Actl 1;
BA_ "U_CX727_MY2021_Rx" SG_ 92 TrnCmdCnt_B_Actl 1;
BA_ "ContentDependant" SG_ 92 TrnCmdCnt_B_Actl 1;
BA_ "U_CD542_MY2021_Rx" SG_ 92 PrkBrkActv_D_RqTrnGear 1;
BA_ "U_T6_MCA_MY2020_Rx" SG_ 92 PrkBrkActv_D_RqTrnGear 1;
BA_ "U_P702_MY2021_Rx" SG_ 92 PrkBrkActv_D_RqTrnGear 1;
BA_ "U_CX727_MY2021_Rx" SG_ 92 PrkBrkActv_D_RqTrnGear 1;
BA_ "GenSigStartValue" SG_ 92 PrkBrkActv_D_RqTrnGear 1;
BA_ "ContentDependant" SG_ 92 PrkBrkActv_D_RqTrnGear 1;
BA_ "GenSigStartValueInteger" SG_ 92 PrkBrkActv_D_RqTrnGear 1;
BA_ "U_CD542_MY2021_Rx" SG_ 92 TrnGearCmd_No_Cnt 1;
BA_ "U_T6_MCA_MY2020_Rx" SG_ 92 TrnGearCmd_No_Cnt 1;
BA_ "U_P702_MY2021_Rx" SG_ 92 TrnGearCmd_No_Cnt 1;
BA_ "U_CX727_MY2021_Rx" SG_ 92 TrnGearCmd_No_Cnt 1;
BA_ "MetaData" SG_ 92 TrnGearCmd_No_Cnt 1;
BA_ "ContentDependant" SG_ 92 TrnGearCmd_No_Cnt 1;
BA_ "U_CD542_MY2021_Tx" SG_ 360 GsmSrvcRqd_B_Rq 1;
BA_ "U_T6_MCA_MY2020_Tx" SG_ 360 GsmSrvcRqd_B_Rq 1;
BA_ "U_P702_MY2021_Tx" SG_ 360 GsmSrvcRqd_B_Rq 1;
BA_ "U_CX727_MY2021_Tx" SG_ 360 GsmSrvcRqd_B_Rq 1;
BA_ "ContentDependant" SG_ 360 GsmSrvcRqd_B_Rq 1;
BA_ "U_CD542_MY2021_Tx" SG_ 360 TrnGearPwmFalt_B_Actl 1;
BA_ "U_T6_MCA_MY2020_Tx" SG_ 360 TrnGearPwmFalt_B_Actl 1;
BA_ "U_P702_MY2021_Tx" SG_ 360 TrnGearPwmFalt_B_Actl 1;
BA_ "U_CX727_MY2021_Tx" SG_ 360 TrnGearPwmFalt_B_Actl 1;
BA_ "ContentDependant" SG_ 360 TrnGearPwmFalt_B_Actl 1;
BA_ "U_CD542_MY2021_Tx" SG_ 360 GearButtnStuck_B_Actl 1;
BA_ "U_T6_MCA_MY2020_Tx" SG_ 360 GearButtnStuck_B_Actl 1;
BA_ "U_P702_MY2021_Tx" SG_ 360 GearButtnStuck_B_Actl 1;
BA_ "U_CX727_MY2021_Tx" SG_ 360 GearButtnStuck_B_Actl 1;
BA_ "ContentDependant" SG_ 360 GearButtnStuck_B_Actl 1;
BA_ "U_CD542_MY2021_Tx" SG_ 90 TrnGsmNtmState_D_Actl 1;
BA_ "U_T6_MCA_MY2020_Tx" SG_ 90 TrnGsmNtmState_D_Actl 1;
BA_ "U_P702_MY2021_Tx" SG_ 90 TrnGsmNtmState_D_Actl 1;
BA_ "U_CX727_MY2021_Tx" SG_ 90 TrnGsmNtmState_D_Actl 1;
BA_ "ContentDependant" SG_ 90 TrnGsmNtmState_D_Actl 1;
BA_ "U_CD542_MY2021_Tx" SG_ 90 DrQltyDrv_D_StatGsm 1;
BA_ "U_T6_MCA_MY2020_Tx" SG_ 90 DrQltyDrv_D_StatGsm 1;
BA_ "U_P702_MY2021_Tx" SG_ 90 DrQltyDrv_D_StatGsm 1;
BA_ "U_CX727_MY2021_Tx" SG_ 90 DrQltyDrv_D_StatGsm 1;
BA_ "GenSigStartValue" SG_ 90 DrQltyDrv_D_StatGsm 6;
BA_ "ContentDependant" SG_ 90 DrQltyDrv_D_StatGsm 1;
BA_ "GenSigStartValueInteger" SG_ 90 DrQltyDrv_D_StatGsm 6;
BA_ "U_CD542_MY2021_Tx" SG_ 90 TrnBtsiOvrrd_B_Stat 1;
BA_ "U_T6_MCA_MY2020_Tx" SG_ 90 TrnBtsiOvrrd_B_Stat 1;
BA_ "U_P702_MY2021_Tx" SG_ 90 TrnBtsiOvrrd_B_Stat 1;
BA_ "U_CX727_MY2021_Tx" SG_ 90 TrnBtsiOvrrd_B_Stat 1;
BA_ "ContentDependant" SG_ 90 TrnBtsiOvrrd_B_Stat 1;
BA_ "U_CD542_MY2021_Tx" SG_ 90 GsmGearMsgTxt_D_Rq 1;
BA_ "U_T6_MCA_MY2020_Tx" SG_ 90 GsmGearMsgTxt_D_Rq 1;
BA_ "U_P702_MY2021_Tx" SG_ 90 GsmGearMsgTxt_D_Rq 1;
BA_ "U_CX727_MY2021_Tx" SG_ 90 GsmGearMsgTxt_D_Rq 1;
BA_ "GenSigSendType" SG_ 90 GsmGearMsgTxt_D_Rq 3;
BA_ "U_CD542_MY2021_Tx" SG_ 90 TrnRng_D_RqGsm 1;
BA_ "U_T6_MCA_MY2020_Tx" SG_ 90 TrnRng_D_RqGsm 1;
BA_ "U_P702_MY2021_Tx" SG_ 90 TrnRng_D_RqGsm 1;
BA_ "U_CX727_MY2021_Tx" SG_ 90 TrnRng_D_RqGsm 1;
BA_ "GenSigSendType" SG_ 90 TrnRng_D_RqGsm 3;
BA_ "GenSigStartValue" SG_ 90 TrnRng_D_RqGsm 14;
BA_ "GenSigStartValueInteger" SG_ 90 TrnRng_D_RqGsm 14;
BA_ "U_CD542_MY2021_Tx" SG_ 90 PrkBrkActv_D_RqGsmGear 1;
BA_ "U_T6_MCA_MY2020_Tx" SG_ 90 PrkBrkActv_D_RqGsmGear 1;
BA_ "U_P702_MY2021_Tx" SG_ 90 PrkBrkActv_D_RqGsmGear 1;
BA_ "U_CX727_MY2021_Tx" SG_ 90 PrkBrkActv_D_RqGsmGear 1;
BA_ "GenSigSendType" SG_ 90 PrkBrkActv_D_RqGsmGear 3;
BA_ "U_CD542_MY2021_Tx" SG_ 90 TrnValidGearRq_D_Stat 1;
BA_ "U_T6_MCA_MY2020_Tx" SG_ 90 TrnValidGearRq_D_Stat 1;
BA_ "U_P702_MY2021_Tx" SG_ 90 TrnValidGearRq_D_Stat 1;
BA_ "U_CX727_MY2021_Tx" SG_ 90 TrnValidGearRq_D_Stat 1;
BA_ "ContentDependant" SG_ 90 TrnValidGearRq_D_Stat 1;
BA_ "U_CD542_MY2021_Tx" SG_ 90 TrnGearRqCnt_B_Actl 1;
BA_ "U_T6_MCA_MY2020_Tx" SG_ 90 TrnGearRqCnt_B_Actl 1;
BA_ "U_P702_MY2021_Tx" SG_ 90 TrnGearRqCnt_B_Actl 1;
BA_ "U_CX727_MY2021_Tx" SG_ 90 TrnGearRqCnt_B_Actl 1;
BA_ "GenSigSendType" SG_ 90 TrnGearRqCnt_B_Actl 3;
BA_ "ContentDependant" SG_ 90 TrnGearRqCnt_B_Actl 1;
BA_ "U_CD542_MY2021_Tx" SG_ 90 TrnGearButtn_U_Actl 1;
BA_ "U_T6_MCA_MY2020_Tx" SG_ 90 TrnGearButtn_U_Actl 1;
BA_ "U_P702_MY2021_Tx" SG_ 90 TrnGearButtn_U_Actl 1;
BA_ "U_CX727_MY2021_Tx" SG_ 90 TrnGearButtn_U_Actl 1;
BA_ "ContentDependant" SG_ 90 TrnGearButtn_U_Actl 1;
BA_ "WakeupSignal" SG_ 90 TrnGearButtn_U_Actl 1;
BA_ "U_CD542_MY2021_Tx" SG_ 90 TrnGearButtn_B_ActlR2 1;
BA_ "U_T6_MCA_MY2020_Tx" SG_ 90 TrnGearButtn_B_ActlR2 1;
BA_ "U_P702_MY2021_Tx" SG_ 90 TrnGearButtn_B_ActlR2 1;
BA_ "U_CX727_MY2021_Tx" SG_ 90 TrnGearButtn_B_ActlR2 1;
BA_ "ContentDependant" SG_ 90 TrnGearButtn_B_ActlR2 1;
BA_ "WakeupSignal" SG_ 90 TrnGearButtn_B_ActlR2 1;
BA_ "U_CD542_MY2021_Tx" SG_ 90 TrnGearButtn_B_ActlR1 1;
BA_ "U_T6_MCA_MY2020_Tx" SG_ 90 TrnGearButtn_B_ActlR1 1;
BA_ "U_P702_MY2021_Tx" SG_ 90 TrnGearButtn_B_ActlR1 1;
BA_ "U_CX727_MY2021_Tx" SG_ 90 TrnGearButtn_B_ActlR1 1;
BA_ "ContentDependant" SG_ 90 TrnGearButtn_B_ActlR1 1;
BA_ "WakeupSignal" SG_ 90 TrnGearButtn_B_ActlR1 1;
BA_ "U_CD542_MY2021_Tx" SG_ 90 TrnGearButtn_B_ActlR0 1;
BA_ "U_T6_MCA_MY2020_Tx" SG_ 90 TrnGearButtn_B_ActlR0 1;
BA_ "U_P702_MY2021_Tx" SG_ 90 TrnGearButtn_B_ActlR0 1;
BA_ "U_CX727_MY2021_Tx" SG_ 90 TrnGearButtn_B_ActlR0 1;
BA_ "ContentDependant" SG_ 90 TrnGearButtn_B_ActlR0 1;
BA_ "WakeupSignal" SG_ 90 TrnGearButtn_B_ActlR0 1;
BA_ "U_CD542_MY2021_Tx" SG_ 90 TrnGearButtn_B_ActlP2 1;
BA_ "U_T6_MCA_MY2020_Tx" SG_ 90 TrnGearButtn_B_ActlP2 1;
BA_ "U_P702_MY2021_Tx" SG_ 90 TrnGearButtn_B_ActlP2 1;
BA_ "U_CX727_MY2021_Tx" SG_ 90 TrnGearButtn_B_ActlP2 1;
BA_ "ContentDependant" SG_ 90 TrnGearButtn_B_ActlP2 1;
BA_ "WakeupSignal" SG_ 90 TrnGearButtn_B_ActlP2 1;
BA_ "U_CD542_MY2021_Tx" SG_ 90 TrnGearButtn_B_ActlP1 1;
BA_ "U_T6_MCA_MY2020_Tx" SG_ 90 TrnGearButtn_B_ActlP1 1;
BA_ "U_P702_MY2021_Tx" SG_ 90 TrnGearButtn_B_ActlP1 1;
BA_ "U_CX727_MY2021_Tx" SG_ 90 TrnGearButtn_B_ActlP1 1;
BA_ "ContentDependant" SG_ 90 TrnGearButtn_B_ActlP1 1;
BA_ "WakeupSignal" SG_ 90 TrnGearButtn_B_ActlP1 1;
BA_ "U_CD542_MY2021_Tx" SG_ 90 TrnGearButtn_B_ActlP0 1;
BA_ "U_T6_MCA_MY2020_Tx" SG_ 90 TrnGearButtn_B_ActlP0 1;
BA_ "U_P702_MY2021_Tx" SG_ 90 TrnGearButtn_B_ActlP0 1;
BA_ "U_CX727_MY2021_Tx" SG_ 90 TrnGearButtn_B_ActlP0 1;
BA_ "ContentDependant" SG_ 90 TrnGearButtn_B_ActlP0 1;
BA_ "WakeupSignal" SG_ 90 TrnGearButtn_B_ActlP0 1;
BA_ "U_CD542_MY2021_Tx" SG_ 90 TrnGearButtn_B_ActlN2 1;
BA_ "U_T6_MCA_MY2020_Tx" SG_ 90 TrnGearButtn_B_ActlN2 1;
BA_ "U_P702_MY2021_Tx" SG_ 90 TrnGearButtn_B_ActlN2 1;
BA_ "U_CX727_MY2021_Tx" SG_ 90 TrnGearButtn_B_ActlN2 1;
BA_ "ContentDependant" SG_ 90 TrnGearButtn_B_ActlN2 1;
BA_ "WakeupSignal" SG_ 90 TrnGearButtn_B_ActlN2 1;
BA_ "U_CD542_MY2021_Tx" SG_ 90 TrnGearButtn_B_ActlN1 1;
BA_ "U_T6_MCA_MY2020_Tx" SG_ 90 TrnGearButtn_B_ActlN1 1;
BA_ "U_P702_MY2021_Tx" SG_ 90 TrnGearButtn_B_ActlN1 1;
BA_ "U_CX727_MY2021_Tx" SG_ 90 TrnGearButtn_B_ActlN1 1;
BA_ "ContentDependant" SG_ 90 TrnGearButtn_B_ActlN1 1;
BA_ "WakeupSignal" SG_ 90 TrnGearButtn_B_ActlN1 1;
BA_ "U_CD542_MY2021_Tx" SG_ 90 TrnGearButtn_B_ActlN0 1;
BA_ "U_T6_MCA_MY2020_Tx" SG_ 90 TrnGearButtn_B_ActlN0 1;
BA_ "U_P702_MY2021_Tx" SG_ 90 TrnGearButtn_B_ActlN0 1;
BA_ "U_CX727_MY2021_Tx" SG_ 90 TrnGearButtn_B_ActlN0 1;
BA_ "ContentDependant" SG_ 90 TrnGearButtn_B_ActlN0 1;
BA_ "WakeupSignal" SG_ 90 TrnGearButtn_B_ActlN0 1;
BA_ "U_CD542_MY2021_Tx" SG_ 90 TrnGearButtn_B_ActlM2 1;
BA_ "U_T6_MCA_MY2020_Tx" SG_ 90 TrnGearButtn_B_ActlM2 1;
BA_ "U_P702_MY2021_Tx" SG_ 90 TrnGearButtn_B_ActlM2 1;
BA_ "U_CX727_MY2021_Tx" SG_ 90 TrnGearButtn_B_ActlM2 1;
BA_ "ContentDependant" SG_ 90 TrnGearButtn_B_ActlM2 1;
BA_ "WakeupSignal" SG_ 90 TrnGearButtn_B_ActlM2 1;
BA_ "U_CD542_MY2021_Tx" SG_ 90 TrnGearButtn_B_ActlM1 1;
BA_ "U_T6_MCA_MY2020_Tx" SG_ 90 TrnGearButtn_B_ActlM1 1;
BA_ "U_P702_MY2021_Tx" SG_ 90 TrnGearButtn_B_ActlM1 1;
BA_ "U_CX727_MY2021_Tx" SG_ 90 TrnGearButtn_B_ActlM1 1;
BA_ "ContentDependant" SG_ 90 TrnGearButtn_B_ActlM1 1;
BA_ "WakeupSignal" SG_ 90 TrnGearButtn_B_ActlM1 1;
BA_ "U_CD542_MY2021_Tx" SG_ 90 TrnGearButtn_B_ActlM0 1;
BA_ "U_T6_MCA_MY2020_Tx" SG_ 90 TrnGearButtn_B_ActlM0 1;
BA_ "U_P702_MY2021_Tx" SG_ 90 TrnGearButtn_B_ActlM0 1;
BA_ "U_CX727_MY2021_Tx" SG_ 90 TrnGearButtn_B_ActlM0 1;
BA_ "ContentDependant" SG_ 90 TrnGearButtn_B_ActlM0 1;
BA_ "WakeupSignal" SG_ 90 TrnGearButtn_B_ActlM0 1;
BA_ "U_CD542_MY2021_Tx" SG_ 90 TrnGearButtn_B_ActlD2 1;
BA_ "U_T6_MCA_MY2020_Tx" SG_ 90 TrnGearButtn_B_ActlD2 1;
BA_ "U_P702_MY2021_Tx" SG_ 90 TrnGearButtn_B_ActlD2 1;
BA_ "U_CX727_MY2021_Tx" SG_ 90 TrnGearButtn_B_ActlD2 1;
BA_ "ContentDependant" SG_ 90 TrnGearButtn_B_ActlD2 1;
BA_ "WakeupSignal" SG_ 90 TrnGearButtn_B_ActlD2 1;
BA_ "U_CD542_MY2021_Tx" SG_ 90 TrnGearButtn_B_ActlD1 1;
BA_ "U_T6_MCA_MY2020_Tx" SG_ 90 TrnGearButtn_B_ActlD1 1;
BA_ "U_P702_MY2021_Tx" SG_ 90 TrnGearButtn_B_ActlD1 1;
BA_ "U_CX727_MY2021_Tx" SG_ 90 TrnGearButtn_B_ActlD1 1;
BA_ "ContentDependant" SG_ 90 TrnGearButtn_B_ActlD1 1;
BA_ "WakeupSignal" SG_ 90 TrnGearButtn_B_ActlD1 1;
BA_ "U_CD542_MY2021_Tx" SG_ 90 TrnGearButtn_B_ActlD0 1;
BA_ "U_T6_MCA_MY2020_Tx" SG_ 90 TrnGearButtn_B_ActlD0 1;
BA_ "U_P702_MY2021_Tx" SG_ 90 TrnGearButtn_B_ActlD0 1;
BA_ "U_CX727_MY2021_Tx" SG_ 90 TrnGearButtn_B_ActlD0 1;
BA_ "ContentDependant" SG_ 90 TrnGearButtn_B_ActlD0 1;
BA_ "WakeupSignal" SG_ 90 TrnGearButtn_B_ActlD0 1;
BA_ "U_CD542_MY2021_Tx" SG_ 90 TrnGear_No_Cs 1;
BA_ "U_T6_MCA_MY2020_Tx" SG_ 90 TrnGear_No_Cs 1;
BA_ "U_P702_MY2021_Tx" SG_ 90 TrnGear_No_Cs 1;
BA_ "U_CX727_MY2021_Tx" SG_ 90 TrnGear_No_Cs 1;
BA_ "MetaData" SG_ 90 TrnGear_No_Cs 1;
BA_ "ContentDependant" SG_ 90 TrnGear_No_Cs 1;
BA_ "U_CD542_MY2021_Tx" SG_ 90 TrnGear_No_Cnt 1;
BA_ "U_T6_MCA_MY2020_Tx" SG_ 90 TrnGear_No_Cnt 1;
BA_ "U_P702_MY2021_Tx" SG_ 90 TrnGear_No_Cnt 1;
BA_ "U_CX727_MY2021_Tx" SG_ 90 TrnGear_No_Cnt 1;
BA_ "MetaData" SG_ 90 TrnGear_No_Cnt 1;
BA_ "ContentDependant" SG_ 90 TrnGear_No_Cnt 1;
BA_ "U_CD542_MY2021_Tx" SG_ 90 TrnGear_D_RqDrv 1;
BA_ "U_T6_MCA_MY2020_Tx" SG_ 90 TrnGear_D_RqDrv 1;
BA_ "U_P702_MY2021_Tx" SG_ 90 TrnGear_D_RqDrv 1;
BA_ "U_CX727_MY2021_Tx" SG_ 90 TrnGear_D_RqDrv 1;
BA_ "GenSigSendType" SG_ 90 TrnGear_D_RqDrv 3;
BA_ "ContentDependant" SG_ 90 TrnGear_D_RqDrv 1;
BA_ "WakeupSignal" SG_ 90 TrnGear_D_RqDrv 1;
BA_ "U_CD542_MY2021_Tx" SG_ 90 BrkSwtchPos_B_ActlGsm 1;
BA_ "U_T6_MCA_MY2020_Tx" SG_ 90 BrkSwtchPos_B_ActlGsm 1;
BA_ "U_P702_MY2021_Tx" SG_ 90 BrkSwtchPos_B_ActlGsm 1;
BA_ "U_CX727_MY2021_Tx" SG_ 90 BrkSwtchPos_B_ActlGsm 1;
BA_ "ContentDependant" SG_ 90 BrkSwtchPos_B_ActlGsm 1;
BA_ "U_CD542_MY2021_Rx" SG_ 1842 TesterPhysicalReqGSM 1;
BA_ "U_T6_MCA_MY2020_Rx" SG_ 1842 TesterPhysicalReqGSM 1;
BA_ "U_P702_MY2021_Rx" SG_ 1842 TesterPhysicalReqGSM 1;
BA_ "U_CX727_MY2021_Rx" SG_ 1842 TesterPhysicalReqGSM 1;
BA_ "GenSigSendType" SG_ 1842 TesterPhysicalReqGSM 3;
BA_ "U_CD542_MY2021_Tx" SG_ 1850 TesterPhysicalResGSM 1;
BA_ "U_T6_MCA_MY2020_Tx" SG_ 1850 TesterPhysicalResGSM 1;
BA_ "U_P702_MY2021_Tx" SG_ 1850 TesterPhysicalResGSM 1;
BA_ "U_CX727_MY2021_Tx" SG_ 1850 TesterPhysicalResGSM 1;
BA_ "GenSigSendType" SG_ 1850 TesterPhysicalResGSM 3;
BA_ "U_T6_MCA_MY2020_Tx" SG_ 936 ApaButtnPrssd_B_Stat 1;
BA_ "U_CD542_MY2021_Tx" SG_ 936 ApaChime_D_Rq 1;
BA_ "U_T6_MCA_MY2020_Tx" SG_ 936 ApaChime_D_Rq 1;
BA_ "U_CD542_MY2021_Tx" SG_ 936 ApaSys_D_Stat 1;
BA_ "U_T6_MCA_MY2020_Tx" SG_ 936 ApaSys_D_Stat 1;
BA_ "U_CD542_MY2021_Tx" SG_ 936 ApaSteWhl_D_RqDrv 1;
BA_ "U_T6_MCA_MY2020_Tx" SG_ 936 ApaSteWhl_D_RqDrv 1;
BA_ "U_CD542_MY2021_Tx" SG_ 936 ApaSteScanMde_D_Stat 1;
BA_ "U_T6_MCA_MY2020_Tx" SG_ 936 ApaSteScanMde_D_Stat 1;
BA_ "U_CD542_MY2021_Tx" SG_ 936 ApaSelSapp_D_Stat 1;
BA_ "U_T6_MCA_MY2020_Tx" SG_ 936 ApaSelSapp_D_Stat 1;
BA_ "U_CD542_MY2021_Tx" SG_ 936 ApaSelPpa_D_Stat 1;
BA_ "U_T6_MCA_MY2020_Tx" SG_ 936 ApaSelPpa_D_Stat 1;
BA_ "U_CD542_MY2021_Tx" SG_ 936 ApaSelPoa_D_Stat 1;
BA_ "U_T6_MCA_MY2020_Tx" SG_ 936 ApaSelPoa_D_Stat 1;
BA_ "U_CD542_MY2021_Tx" SG_ 936 ApaScan_D_Stat 1;
BA_ "U_T6_MCA_MY2020_Tx" SG_ 936 ApaScan_D_Stat 1;
BA_ "U_CD542_MY2021_Tx" SG_ 936 ApaLongCtl_D_RqDrv 1;
BA_ "U_T6_MCA_MY2020_Tx" SG_ 936 ApaLongCtl_D_RqDrv 1;
BA_ "U_CD542_MY2021_Tx" SG_ 936 ApaGearShif_D_RqDrv 1;
BA_ "U_T6_MCA_MY2020_Tx" SG_ 936 ApaGearShif_D_RqDrv 1;
BA_ "U_CD542_MY2021_Tx" SG_ 936 ApaActvSide2_D_Stat 1;
BA_ "U_T6_MCA_MY2020_Tx" SG_ 936 ApaActvSide2_D_Stat 1;
BA_ "U_CD542_MY2021_Tx" SG_ 936 ApaAcsy_D_RqDrv 1;
BA_ "U_T6_MCA_MY2020_Tx" SG_ 936 ApaAcsy_D_RqDrv 1;
BA_ "U_CD542_MY2021_Tx" SG_ 936 ApaTrgtDist_D_Stat 1;
BA_ "U_T6_MCA_MY2020_Tx" SG_ 936 ApaTrgtDist_D_Stat 1;
BA_ "U_CD542_MY2021_Tx" SG_ 936 ApaMsgTxt_D_Rq 1;
BA_ "U_T6_MCA_MY2020_Tx" SG_ 936 ApaMsgTxt_D_Rq 1;
BA_ "U_CD542_MY2021_Tx" SG_ 936 EPASExtAngleStatReq 1;
BA_ "U_T6_MCA_MY2020_Tx" SG_ 936 EPASExtAngleStatReq 1;
BA_ "U_CD542_MY2021_Tx" SG_ 936 ExtSteeringAngleReq2 1;
BA_ "U_T6_MCA_MY2020_Tx" SG_ 936 ExtSteeringAngleReq2 1;
BA_ "U_CD542_MY2021_Tx" SG_ 76 FirstRowBuckle_No_Cs 1;
BA_ "MetaData" SG_ 76 FirstRowBuckle_No_Cs 1;
BA_ "U_CD542_MY2021_Tx" SG_ 76 RstrnPsngrOn_D_Stat 1;
BA_ "U_T6_MCA_MY2020_Tx" SG_ 76 RstrnPsngrOn_D_Stat 1;
BA_ "U_CX727_MY2021_Tx" SG_ 76 RstrnPsngrOn_D_Stat 1;
BA_ "GenSigSendType" SG_ 76 RstrnPsngrOn_D_Stat 3;
BA_ "U_CD542_MY2021_Tx" SG_ 76 RCMStatusMsg2_No_Cnt 1;
BA_ "U_T6_MCA_MY2020_Tx" SG_ 76 RCMStatusMsg2_No_Cnt 1;
BA_ "MetaData" SG_ 76 RCMStatusMsg2_No_Cnt 1;
BA_ "U_T6_MCA_MY2020_Tx" SG_ 76 PsngrFmidDetct_D_Actl 1;
BA_ "U_CX727_MY2021_Tx" SG_ 76 PsngrFmidDetct_D_Actl 1;
BA_ "GenSigSendType" SG_ 76 PsngrFmidDetct_D_Actl 3;
BA_ "GenSigStartValue" SG_ 76 PsngrFmidDetct_D_Actl 3;
BA_ "GenSigStartValueInteger" SG_ 76 PsngrFmidDetct_D_Actl 3;
BA_ "U_T6_MCA_MY2020_Tx" SG_ 76 FirstRowBuckleMid 1;
BA_ "U_P702_MY2021_Tx" SG_ 76 FirstRowBuckleMid 1;
BA_ "U_CX727_MY2021_Tx" SG_ 76 FirstRowBuckleMid 1;
BA_ "GenSigSendType" SG_ 76 FirstRowBuckleMid 3;
BA_ "GenSigStartValue" SG_ 76 FirstRowBuckleMid 3;
BA_ "GenSigStartValueInteger" SG_ 76 FirstRowBuckleMid 3;
BA_ "U_T6_MCA_MY2020_Tx" SG_ 76 ThirdRowBucklePsngr 1;
BA_ "U_CX727_MY2021_Tx" SG_ 76 ThirdRowBucklePsngr 1;
BA_ "GenSigSendType" SG_ 76 ThirdRowBucklePsngr 3;
BA_ "GenSigStartValue" SG_ 76 ThirdRowBucklePsngr 3;
BA_ "GenSigStartValueInteger" SG_ 76 ThirdRowBucklePsngr 3;
BA_ "U_CD542_MY2021_Tx" SG_ 76 ThirdRowBuckleDriver 1;
BA_ "U_T6_MCA_MY2020_Tx" SG_ 76 ThirdRowBuckleDriver 1;
BA_ "U_CX727_MY2021_Tx" SG_ 76 ThirdRowBuckleDriver 1;
BA_ "GenSigSendType" SG_ 76 ThirdRowBuckleDriver 3;
BA_ "GenSigStartValue" SG_ 76 ThirdRowBuckleDriver 3;
BA_ "GenSigStartValueInteger" SG_ 76 ThirdRowBuckleDriver 3;
BA_ "U_CD542_MY2021_Tx" SG_ 76 SecondRowBucklePsngr 1;
BA_ "U_T6_MCA_MY2020_Tx" SG_ 76 SecondRowBucklePsngr 1;
BA_ "U_P702_MY2021_Tx" SG_ 76 SecondRowBucklePsngr 1;
BA_ "U_CX727_MY2021_Tx" SG_ 76 SecondRowBucklePsngr 1;
BA_ "GenSigSendType" SG_ 76 SecondRowBucklePsngr 3;
BA_ "GenSigStartValue" SG_ 76 SecondRowBucklePsngr 3;
BA_ "GenSigStartValueInteger" SG_ 76 SecondRowBucklePsngr 3;
BA_ "U_CD542_MY2021_Tx" SG_ 76 SecondRowBuckleMid 1;
BA_ "U_T6_MCA_MY2020_Tx" SG_ 76 SecondRowBuckleMid 1;
BA_ "U_P702_MY2021_Tx" SG_ 76 SecondRowBuckleMid 1;
BA_ "U_CX727_MY2021_Tx" SG_ 76 SecondRowBuckleMid 1;
BA_ "GenSigSendType" SG_ 76 SecondRowBuckleMid 3;
BA_ "GenSigStartValue" SG_ 76 SecondRowBuckleMid 3;
BA_ "GenSigStartValueInteger" SG_ 76 SecondRowBuckleMid 3;
BA_ "U_CD542_MY2021_Tx" SG_ 76 SecondRowBuckleDriver 1;
BA_ "U_T6_MCA_MY2020_Tx" SG_ 76 SecondRowBuckleDriver 1;
BA_ "U_P702_MY2021_Tx" SG_ 76 SecondRowBuckleDriver 1;
BA_ "U_CX727_MY2021_Tx" SG_ 76 SecondRowBuckleDriver 1;
BA_ "GenSigSendType" SG_ 76 SecondRowBuckleDriver 3;
BA_ "GenSigStartValue" SG_ 76 SecondRowBuckleDriver 3;
BA_ "GenSigStartValueInteger" SG_ 76 SecondRowBuckleDriver 3;
BA_ "U_CD542_MY2021_Tx" SG_ 76 FirstRowBuckleDriver 1;
BA_ "U_T6_MCA_MY2020_Tx" SG_ 76 FirstRowBuckleDriver 1;
BA_ "U_P702_MY2021_Tx" SG_ 76 FirstRowBuckleDriver 1;
BA_ "U_CX727_MY2021_Tx" SG_ 76 FirstRowBuckleDriver 1;
BA_ "ECGUsedRxSignal" SG_ 76 FirstRowBuckleDriver 1;
BA_ "U_CD542_MY2021_Rx" SG_ 76 FirstRowBuckleDriver 1;
BA_ "U_T6_MCA_MY2020_Rx" SG_ 76 FirstRowBuckleDriver 1;
BA_ "U_P702_MY2021_Rx" SG_ 76 FirstRowBuckleDriver 1;
BA_ "U_CX727_MY2021_Rx" SG_ 76 FirstRowBuckleDriver 1;
BA_ "GenSigSendType" SG_ 76 FirstRowBuckleDriver 3;
BA_ "GenSigStartValue" SG_ 76 FirstRowBuckleDriver 3;
BA_ "GenSigStartValueInteger" SG_ 76 FirstRowBuckleDriver 3;
BA_ "U_CD542_MY2021_Tx" SG_ 76 RILReq 1;
BA_ "U_T6_MCA_MY2020_Tx" SG_ 76 RILReq 1;
BA_ "U_P702_MY2021_Tx" SG_ 76 RILReq 1;
BA_ "U_CX727_MY2021_Tx" SG_ 76 RILReq 1;
BA_ "GenSigSendType" SG_ 76 RILReq 3;
BA_ "U_CD542_MY2021_Tx" SG_ 76 FirstRowBucklePsngr 1;
BA_ "U_T6_MCA_MY2020_Tx" SG_ 76 FirstRowBucklePsngr 1;
BA_ "U_P702_MY2021_Tx" SG_ 76 FirstRowBucklePsngr 1;
BA_ "U_CX727_MY2021_Tx" SG_ 76 FirstRowBucklePsngr 1;
BA_ "ECGUsedRxSignal" SG_ 76 FirstRowBucklePsngr 1;
BA_ "U_T6_MCA_MY2020_Rx" SG_ 76 FirstRowBucklePsngr 1;
BA_ "U_P702_MY2021_Rx" SG_ 76 FirstRowBucklePsngr 1;
BA_ "U_CX727_MY2021_Rx" SG_ 76 FirstRowBucklePsngr 1;
BA_ "GenSigSendType" SG_ 76 FirstRowBucklePsngr 3;
BA_ "GenSigStartValue" SG_ 76 FirstRowBucklePsngr 3;
BA_ "GenSigStartValueInteger" SG_ 76 FirstRowBucklePsngr 3;
BA_ "U_CD542_MY2021_Tx" SG_ 76 RstrnImpactEvntStatus 1;
BA_ "U_T6_MCA_MY2020_Tx" SG_ 76 RstrnImpactEvntStatus 1;
BA_ "U_P702_MY2021_Tx" SG_ 76 RstrnImpactEvntStatus 1;
BA_ "U_CX727_MY2021_Tx" SG_ 76 RstrnImpactEvntStatus 1;
BA_ "U_CD542_MY2021_Rx" SG_ 76 RstrnImpactEvntStatus 1;
BA_ "ECGUsedRxSignal" SG_ 76 RstrnImpactEvntStatus 1;
BA_ "U_T6_MCA_MY2020_Rx" SG_ 76 RstrnImpactEvntStatus 1;
BA_ "U_P702_MY2021_Rx" SG_ 76 RstrnImpactEvntStatus 1;
BA_ "U_CX727_MY2021_Rx" SG_ 76 RstrnImpactEvntStatus 1;
BA_ "GenSigSendType" SG_ 76 RstrnImpactEvntStatus 3;
BA_ "WakeupSignal" SG_ 76 RstrnImpactEvntStatus 1;
BA_ "U_T6_MCA_MY2020_Tx" SG_ 76 PsngrFrntDetct_D_Actl 1;
BA_ "U_CX727_MY2021_Tx" SG_ 76 PsngrFrntDetct_D_Actl 1;
BA_ "GenSigSendType" SG_ 76 PsngrFrntDetct_D_Actl 3;
BA_ "GenSigStartValue" SG_ 76 PsngrFrntDetct_D_Actl 3;
BA_ "GenSigStartValueInteger" SG_ 76 PsngrFrntDetct_D_Actl 3;
BA_ "U_CD542_MY2021_Tx" SG_ 76 EDRTriggerEvntSync 1;
BA_ "U_T6_MCA_MY2020_Tx" SG_ 76 EDRTriggerEvntSync 1;
BA_ "U_P702_MY2021_Tx" SG_ 76 EDRTriggerEvntSync 1;
BA_ "U_CX727_MY2021_Tx" SG_ 76 EDRTriggerEvntSync 1;
BA_ "GenSigSendType" SG_ 76 EDRTriggerEvntSync 3;
BA_ "U_T6_MCA_MY2020_Tx" SG_ 76 PassRstrnInd_Req 1;
BA_ "U_P702_MY2021_Tx" SG_ 76 PassRstrnInd_Req 1;
BA_ "U_CX727_MY2021_Tx" SG_ 76 PassRstrnInd_Req 1;
BA_ "GenSigSendType" SG_ 76 PassRstrnInd_Req 3;
BA_ "GenSigStartValue" SG_ 76 PassRstrnInd_Req 3;
BA_ "GenSigStartValueInteger" SG_ 76 PassRstrnInd_Req 3;
BA_ "U_CD542_MY2021_Rx" SG_ 120 BpedDrvMsgTxt_B_Dsply_UB 1;
BA_ "U_T6_MCA_MY2020_Rx" SG_ 120 BpedDrvMsgTxt_B_Dsply_UB 1;
BA_ "U_P702_MY2021_Rx" SG_ 120 BpedDrvMsgTxt_B_Dsply_UB 1;
BA_ "U_CX727_MY2021_Rx" SG_ 120 BpedDrvMsgTxt_B_Dsply_UB 1;
BA_ "U_CD542_MY2021_Rx" SG_ 120 BpedDrvMsgTxt_B_Dsply 1;
BA_ "U_T6_MCA_MY2020_Rx" SG_ 120 BpedDrvMsgTxt_B_Dsply 1;
BA_ "U_P702_MY2021_Rx" SG_ 120 BpedDrvMsgTxt_B_Dsply 1;
BA_ "U_CX727_MY2021_Rx" SG_ 120 BpedDrvMsgTxt_B_Dsply 1;
BA_ "U_CD542_MY2021_Rx" SG_ 120 ECMMILRequest_UB 1;
BA_ "U_T6_MCA_MY2020_Rx" SG_ 120 ECMMILRequest_UB 1;
BA_ "U_P702_MY2021_Rx" SG_ 120 ECMMILRequest_UB 1;
BA_ "U_CX727_MY2021_Rx" SG_ 120 ECMMILRequest_UB 1;
BA_ "U_CD542_MY2021_Rx" SG_ 120 ECMMILRequest 1;
BA_ "U_T6_MCA_MY2020_Rx" SG_ 120 ECMMILRequest 1;
BA_ "U_P702_MY2021_Rx" SG_ 120 ECMMILRequest 1;
BA_ "U_CX727_MY2021_Rx" SG_ 120 ECMMILRequest 1;
BA_ "U_CD542_MY2021_Rx" SG_ 120 TrnIpcDsplyMde_D_Stat 1;
BA_ "U_T6_MCA_MY2020_Rx" SG_ 120 TrnIpcDsplyMde_D_Stat 1;
BA_ "U_P702_MY2021_Rx" SG_ 120 TrnIpcDsplyMde_D_Stat 1;
BA_ "U_CX727_MY2021_Rx" SG_ 120 TrnIpcDsplyMde_D_Stat 1;
BA_ "WakeupSignal" SG_ 120 TrnIpcDsplyMde_D_Stat 1;
BA_ "U_CD542_MY2021_Rx" SG_ 120 TrnIpcDsplyMde_D_Actl 1;
BA_ "U_T6_MCA_MY2020_Rx" SG_ 120 TrnIpcDsplyMde_D_Actl 1;
BA_ "U_P702_MY2021_Rx" SG_ 120 TrnIpcDsplyMde_D_Actl 1;
BA_ "U_CX727_MY2021_Rx" SG_ 120 TrnIpcDsplyMde_D_Actl 1;
BA_ "WakeupSignal" SG_ 120 TrnIpcDsplyMde_D_Actl 1;
BA_ "U_CD542_MY2021_Rx" SG_ 120 EngSrvcRqd_B_Rq 1;
BA_ "U_T6_MCA_MY2020_Rx" SG_ 120 EngSrvcRqd_B_Rq 1;
BA_ "U_P702_MY2021_Rx" SG_ 120 EngSrvcRqd_B_Rq 1;
BA_ "U_CX727_MY2021_Rx" SG_ 120 EngSrvcRqd_B_Rq 1;
BA_ "U_CD542_MY2021_Rx" SG_ 120 TrnIpcDsplyMde_D_Stat_UB 1;
BA_ "U_T6_MCA_MY2020_Rx" SG_ 120 TrnIpcDsplyMde_D_Stat_UB 1;
BA_ "U_P702_MY2021_Rx" SG_ 120 TrnIpcDsplyMde_D_Stat_UB 1;
BA_ "U_CX727_MY2021_Rx" SG_ 120 TrnIpcDsplyMde_D_Stat_UB 1;
BA_ "U_CD542_MY2021_Rx" SG_ 120 TrnIpcDsplyMde_D_Actl_UB 1;
BA_ "U_T6_MCA_MY2020_Rx" SG_ 120 TrnIpcDsplyMde_D_Actl_UB 1;
BA_ "U_P702_MY2021_Rx" SG_ 120 TrnIpcDsplyMde_D_Actl_UB 1;
BA_ "U_CX727_MY2021_Rx" SG_ 120 TrnIpcDsplyMde_D_Actl_UB 1;
BA_ "U_CD542_MY2021_Tx" SG_ 1665 UUDTRCMResponse2 1;
BA_ "U_T6_MCA_MY2020_Tx" SG_ 1665 UUDTRCMResponse2 1;
BA_ "U_P702_MY2021_Tx" SG_ 1665 UUDTRCMResponse2 1;
BA_ "U_CX727_MY2021_Tx" SG_ 1665 UUDTRCMResponse2 1;
BA_ "GenSigSendType" SG_ 1665 UUDTRCMResponse2 3;
BA_ "U_CD542_MY2021_Tx" SG_ 2041 TesterPhysicalResPCU 1;
BA_ "U_T6_MCA_MY2020_Tx" SG_ 2041 TesterPhysicalResPCU 1;
BA_ "U_P702_MY2021_Tx" SG_ 2041 TesterPhysicalResPCU 1;
BA_ "U_CX727_MY2021_Tx" SG_ 2041 TesterPhysicalResPCU 1;
BA_ "GenSigSendType" SG_ 2041 TesterPhysicalResPCU 3;
BA_ "ECGUsedTxSignal" SG_ 1438 GWM_GWOnBoardTester 1;
BA_ "U_T6_MCA_MY2020_Tx" SG_ 1438 GWM_GWOnBoardTester 1;
BA_ "U_CD542_MY2021_Rx" SG_ 1438 GWM_GWOnBoardTester 1;
BA_ "U_T6_MCA_MY2020_Rx" SG_ 1438 GWM_GWOnBoardTester 1;
BA_ "U_P702_MY2021_Rx" SG_ 1438 GWM_GWOnBoardTester 1;
BA_ "U_CX727_MY2021_Rx" SG_ 1438 GWM_GWOnBoardTester 1;
BA_ "GenSigStartValue" SG_ 1438 GWM_GWOnBoardTester 255;
BA_ "ContentDependant" SG_ 1438 GWM_GWOnBoardTester 1;
BA_ "GenSigStartValueInteger" SG_ 1438 GWM_GWOnBoardTester 255;
BA_ "ECGUsedTxSignal" SG_ 1438 GWM_GWNMProxy 1;
BA_ "U_T6_MCA_MY2020_Tx" SG_ 1438 GWM_GWNMProxy 1;
BA_ "U_CD542_MY2021_Rx" SG_ 1438 GWM_GWNMProxy 1;
BA_ "U_T6_MCA_MY2020_Rx" SG_ 1438 GWM_GWNMProxy 1;
BA_ "U_P702_MY2021_Rx" SG_ 1438 GWM_GWNMProxy 1;
BA_ "U_CX727_MY2021_Rx" SG_ 1438 GWM_GWNMProxy 1;
BA_ "GenSigStartValue" SG_ 1438 GWM_GWNMProxy 255;
BA_ "ContentDependant" SG_ 1438 GWM_GWNMProxy 1;
BA_ "GenSigStartValueInteger" SG_ 1438 GWM_GWNMProxy 255;
BA_ "ECGUsedTxSignal" SG_ 1438 GWM_AutoSarNMReserved4 1;
BA_ "U_T6_MCA_MY2020_Tx" SG_ 1438 GWM_AutoSarNMReserved4 1;
BA_ "U_CD542_MY2021_Rx" SG_ 1438 GWM_AutoSarNMReserved4 1;
BA_ "U_T6_MCA_MY2020_Rx" SG_ 1438 GWM_AutoSarNMReserved4 1;
BA_ "U_P702_MY2021_Rx" SG_ 1438 GWM_AutoSarNMReserved4 1;
BA_ "U_CX727_MY2021_Rx" SG_ 1438 GWM_AutoSarNMReserved4 1;
BA_ "GenSigStartValue" SG_ 1438 GWM_AutoSarNMReserved4 255;
BA_ "ContentDependant" SG_ 1438 GWM_AutoSarNMReserved4 1;
BA_ "GenSigStartValueInteger" SG_ 1438 GWM_AutoSarNMReserved4 255;
BA_ "ECGUsedTxSignal" SG_ 1438 GWM_AutoSarNMReserved3 1;
BA_ "U_T6_MCA_MY2020_Tx" SG_ 1438 GWM_AutoSarNMReserved3 1;
BA_ "U_CD542_MY2021_Rx" SG_ 1438 GWM_AutoSarNMReserved3 1;
BA_ "U_T6_MCA_MY2020_Rx" SG_ 1438 GWM_AutoSarNMReserved3 1;
BA_ "U_P702_MY2021_Rx" SG_ 1438 GWM_AutoSarNMReserved3 1;
BA_ "U_CX727_MY2021_Rx" SG_ 1438 GWM_AutoSarNMReserved3 1;
BA_ "GenSigStartValue" SG_ 1438 GWM_AutoSarNMReserved3 255;
BA_ "ContentDependant" SG_ 1438 GWM_AutoSarNMReserved3 1;
BA_ "GenSigStartValueInteger" SG_ 1438 GWM_AutoSarNMReserved3 255;
BA_ "ECGUsedTxSignal" SG_ 1438 GWM_AutoSarNMReserved2 1;
BA_ "U_T6_MCA_MY2020_Tx" SG_ 1438 GWM_AutoSarNMReserved2 1;
BA_ "U_CD542_MY2021_Rx" SG_ 1438 GWM_AutoSarNMReserved2 1;
BA_ "U_T6_MCA_MY2020_Rx" SG_ 1438 GWM_AutoSarNMReserved2 1;
BA_ "U_P702_MY2021_Rx" SG_ 1438 GWM_AutoSarNMReserved2 1;
BA_ "U_CX727_MY2021_Rx" SG_ 1438 GWM_AutoSarNMReserved2 1;
BA_ "GenSigStartValue" SG_ 1438 GWM_AutoSarNMReserved2 255;
BA_ "ContentDependant" SG_ 1438 GWM_AutoSarNMReserved2 1;
BA_ "GenSigStartValueInteger" SG_ 1438 GWM_AutoSarNMReserved2 255;
BA_ "ECGUsedTxSignal" SG_ 1438 GWM_AutoSarNMReserved1 1;
BA_ "U_T6_MCA_MY2020_Tx" SG_ 1438 GWM_AutoSarNMReserved1 1;
BA_ "U_CD542_MY2021_Rx" SG_ 1438 GWM_AutoSarNMReserved1 1;
BA_ "U_T6_MCA_MY2020_Rx" SG_ 1438 GWM_AutoSarNMReserved1 1;
BA_ "U_P702_MY2021_Rx" SG_ 1438 GWM_AutoSarNMReserved1 1;
BA_ "U_CX727_MY2021_Rx" SG_ 1438 GWM_AutoSarNMReserved1 1;
BA_ "GenSigStartValue" SG_ 1438 GWM_AutoSarNMReserved1 255;
BA_ "ContentDependant" SG_ 1438 GWM_AutoSarNMReserved1 1;
BA_ "GenSigStartValueInteger" SG_ 1438 GWM_AutoSarNMReserved1 255;
BA_ "ECGUsedTxSignal" SG_ 1438 GWM_AutoSarNMNodeId 1;
BA_ "U_T6_MCA_MY2020_Tx" SG_ 1438 GWM_AutoSarNMNodeId 1;
BA_ "U_CD542_MY2021_Rx" SG_ 1438 GWM_AutoSarNMNodeId 1;
BA_ "U_T6_MCA_MY2020_Rx" SG_ 1438 GWM_AutoSarNMNodeId 1;
BA_ "U_P702_MY2021_Rx" SG_ 1438 GWM_AutoSarNMNodeId 1;
BA_ "U_CX727_MY2021_Rx" SG_ 1438 GWM_AutoSarNMNodeId 1;
BA_ "GenSigStartValue" SG_ 1438 GWM_AutoSarNMNodeId 158;
BA_ "ContentDependant" SG_ 1438 GWM_AutoSarNMNodeId 1;
BA_ "GenSigStartValueInteger" SG_ 1438 GWM_AutoSarNMNodeId 158;
BA_ "ECGUsedTxSignal" SG_ 1438 GWM_AutoSarNMControl 1;
BA_ "U_T6_MCA_MY2020_Tx" SG_ 1438 GWM_AutoSarNMControl 1;
BA_ "U_CD542_MY2021_Rx" SG_ 1438 GWM_AutoSarNMControl 1;
BA_ "U_T6_MCA_MY2020_Rx" SG_ 1438 GWM_AutoSarNMControl 1;
BA_ "U_P702_MY2021_Rx" SG_ 1438 GWM_AutoSarNMControl 1;
BA_ "U_CX727_MY2021_Rx" SG_ 1438 GWM_AutoSarNMControl 1;
BA_ "ContentDependant" SG_ 1438 GWM_AutoSarNMControl 1;
BA_ "U_CD542_MY2021_Rx" SG_ 1034 VehicleGGCCData 1;
BA_ "U_T6_MCA_MY2020_Rx" SG_ 1034 VehicleGGCCData 1;
BA_ "U_P702_MY2021_Rx" SG_ 1034 VehicleGGCCData 1;
BA_ "U_CX727_MY2021_Rx" SG_ 1034 VehicleGGCCData 1;
BA_ "ContentDependant" SG_ 376 EngAout_Aa_Actl 1;
BA_ "U_CD542_MY2021_Rx" SG_ 376 AirAmbTe_D_Qf 1;
BA_ "U_T6_MCA_MY2020_Rx" SG_ 376 AirAmbTe_D_Qf 1;
BA_ "U_P702_MY2021_Rx" SG_ 376 AirAmbTe_D_Qf 1;
BA_ "U_CX727_MY2021_Rx" SG_ 376 AirAmbTe_D_Qf 1;
BA_ "GenSigStartValue" SG_ 376 AirAmbTe_D_Qf 1;
BA_ "MetaData" SG_ 376 AirAmbTe_D_Qf 1;
BA_ "GenSigStartValueInteger" SG_ 376 AirAmbTe_D_Qf 1;
BA_ "GenSigStartValueInteger" SG_ 376 AirAmb_Te_ActlFilt 512;
BA_ "U_CD542_MY2021_Rx" SG_ 376 AirAmb_Te_Actl 1;
BA_ "U_T6_MCA_MY2020_Rx" SG_ 376 AirAmb_Te_Actl 1;
BA_ "U_P702_MY2021_Rx" SG_ 376 AirAmb_Te_Actl 1;
BA_ "U_CX727_MY2021_Rx" SG_ 376 AirAmb_Te_Actl 1;
BA_ "GenSigStartValueInteger" SG_ 376 AirAmb_Te_Actl 512;
BA_ "GenSigStartValue" SG_ 516 EngAoutNActl_D_QF 1;
BA_ "MetaData" SG_ 516 EngAoutNActl_D_QF 1;
BA_ "GenSigStartValueInteger" SG_ 516 EngAoutNActl_D_QF 1;
BA_ "U_CD542_MY2021_Rx" SG_ 516 ApedPos_Pc_ActlArb 1;
BA_ "U_T6_MCA_MY2020_Rx" SG_ 516 ApedPos_Pc_ActlArb 1;
BA_ "U_P702_MY2021_Rx" SG_ 516 ApedPos_Pc_ActlArb 1;
BA_ "U_CX727_MY2021_Rx" SG_ 516 ApedPos_Pc_ActlArb 1;
BA_ "U_CD542_MY2021_Rx" SG_ 516 ApedPosPcActl_D_Qf 1;
BA_ "U_T6_MCA_MY2020_Rx" SG_ 516 ApedPosPcActl_D_Qf 1;
BA_ "U_P702_MY2021_Rx" SG_ 516 ApedPosPcActl_D_Qf 1;
BA_ "U_CX727_MY2021_Rx" SG_ 516 ApedPosPcActl_D_Qf 1;
BA_ "GenSigStartValue" SG_ 516 ApedPosPcActl_D_Qf 1;
BA_ "MetaData" SG_ 516 ApedPosPcActl_D_Qf 1;
BA_ "GenSigStartValueInteger" SG_ 516 ApedPosPcActl_D_Qf 1;
BA_ "U_CD542_MY2021_Rx" SG_ 516 EngAout_N_Actl 1;
BA_ "U_T6_MCA_MY2020_Rx" SG_ 516 EngAout_N_Actl 1;
BA_ "U_P702_MY2021_Rx" SG_ 516 EngAout_N_Actl 1;
BA_ "U_CX727_MY2021_Rx" SG_ 516 EngAout_N_Actl 1;
BA_ "MetaData" SG_ 516 ApedPosPcActl_No_Cs 1;
BA_ "ContentDependant" SG_ 516 ApedPosPcActl_No_Cs 1;
BA_ "MetaData" SG_ 516 ApedPosPcActl_No_Cnt 1;
BA_ "ContentDependant" SG_ 516 ApedPosPcActl_No_Cnt 1;
VAL_ 1081 DieslPrtc2_D_RqDsply 15 "NotUsed4" 14 "NotUsed3" 13 "NotUsed2" 12 "NotUsed1" 11 "OCR_ExhFilterClean_Stopped" 10 "OCR_ExhFilterCleaned" 9 "RgnOff_AtLimit" 8 "RgnOff_Overloaded" 7 "RgnOff_Loaded" 6 "Exhaust_Filter_Full" 5 "DPF_Overlimit" 4 "DPF_AtLimit" 3 "ExhFilter_Drive_Completed" 2 "Cleaning_Exhaust_Filter" 1 "DPF_Overloaded" 0 "DPF_Normal_Operation" ;
VAL_ 1081 PrkAidSwtch_D_RqMnu_UB 1 "Fresh_data" 0 "Unchanged_data" ;
VAL_ 1081 PrkAidSwtch_D_RqMnu 1 "Pressed" 0 "Not_Pressed" ;
VAL_ 1081 ApaSwtch_D_RqMnu 3 "NotUsed2" 2 "NotUsed1" 1 "Pressed" 0 "Not_Pressed" ;
VAL_ 1081 ApaSwtch_D_RqMnu_UB 1 "Fresh_data" 0 "Unchanged_data" ;
VAL_ 1081 FapLcActv_B_Stat_UB 1 "Fresh_data" 0 "Unchanged_data" ;
VAL_ 1081 PrkAidRear_D_RqDrv_UB 1 "Fresh_data" 0 "Unchanged_data" ;
VAL_ 1081 PrkAidRear_D_RqDrv 2 "Status" 3 "NotUsed" 1 "Enabled" 0 "Disabled" ;
VAL_ 1081 PrkAidFront_D_RqDrv_UB 1 "Fresh_data" 0 "Unchanged_data" ;
VAL_ 1081 PrkAidFront_D_RqDrv 2 "Status" 3 "NotUsed" 1 "Enabled" 0 "Disabled" ;
VAL_ 1081 GenericSwtch3_No_Actl_UB 1 "Fresh_data" 0 "Unchanged_data" ;
VAL_ 1081 GenericSwtch2_No_Actl_UB 1 "Fresh_data" 0 "Unchanged_data" ;
VAL_ 1081 GenericSwtch1_No_Actl_UB 1 "Fresh_data" 0 "Unchanged_data" ;
VAL_ 937 TrnRng_D_RqFap 7 "NotUsed3" 6 "NotUsed2" 5 "NotUsed1" 4 "Backwards" 3 "Forwards" 2 "NoMotion" 1 "Immobilize" 0 "NoRequest" ;
VAL_ 937 FapLcDistToObj_L_Actl 255 "Faulty" 254 "NoDataExists" ;
VAL_ 1010 MbdblActv_B_RqAdas 1 "Yes" 0 "No" ;
VAL_ 1010 CbdblActv_B_RqAdas 1 "Yes" 0 "No" ;
VAL_ 1010 AdbUrbanArea_B_Stat 1 "Yes" 0 "No" ;
VAL_ 942 PrkAidDrvDir_D_Stat 7 "NotUsed_2" 6 "NotUsed_1" 5 "BackwardNegative" 4 "ForwardNegative" 3 "BackwardPositive" 2 "ForwardPositive" 1 "NoMotion" 0 "DirectionNotKnown" ;
VAL_ 1120 FrontDiffLck_D_RqDrv 3 "Faulty" 2 "NoRequest" 1 "On" 0 "Off" ;
VAL_ 1120 RearDiffLck_D_RqDrv 3 "Faulty" 2 "NoRequest" 1 "On" 0 "Off" ;
VAL_ 1120 AwdMde_D_RqDrv 7 "Faulty" 6 "NotUsed2" 5 "NoRequest" 4 "Neutral" 3 "FourByFourLow" 2 "FourByFourHigh" 1 "FourByFourAuto" 0 "FourByTwo" ;
VAL_ 1080 TrlrAidMde_D_Rq_UB 1 "Fresh_data" 0 "Unchanged_data" ;
VAL_ 1080 TrlrAidMde_D_Rq 3 "Mode_3" 2 "Mode_2" 1 "Mode_1" 0 "NoRequest" ;
VAL_ 1080 Rba_D_Rq_UB 1 "Fresh_data" 0 "Unchanged_data" ;
VAL_ 1080 Rba_D_Rq 3 "NotUsed" 2 "On" 1 "Off" 0 "Null" ;
VAL_ 1080 TrailCtlPt_B_Falt_UB 1 "Fresh_data" 0 "Unchanged_data" ;
VAL_ 1080 TrailCtlPt_B_Falt 1 "Fault" 0 "No_Fault" ;
VAL_ 1080 TurnLghtSwtch_D_Stat2_UB 1 "Fresh_data" 0 "Unchanged_data" ;
VAL_ 1080 CabnAmb_Te_Actl_UB 1 "Fresh_data" 0 "Unchanged_data" ;
VAL_ 1080 CabnAmb_Te_Actl 255 "Fault" ;
VAL_ 1080 HeadLghtHiPrmsn_D_Stat_UB 1 "Fresh_data" 0 "Unchanged_data" ;
VAL_ 1080 HeadLghtHiPrmsn_D_Stat 3 "CancelAndSuppress" 2 "Cancel" 1 "Hold" 0 "AllowChange" ;
VAL_ 1121 SelDrvMdeSwtch_D_Stat 3 "Faulty" 2 "SwitchState2" 1 "SwitchState1" 0 "NotPressed" ;
VAL_ 1121 SelDrvMdeCnt_D_Stat 4 "FourCounts" 3 "ThreeCounts" 2 "TwoCounts" 1 "OneCount" 0 "ZeroCounts" 7 "SevenOrMoreCounts" 6 "SixCounts" 5 "FiveCounts" ;
VAL_ 673 ICI_Coding_BtnID_D 15 "Idle" 5 "Stuck" 4 "LongEvent" 3 "ShortElapsed" 2 "ShortEvent" 1 "Active" 0 "Inactive" ;
VAL_ 673 ICI_Coding_BtnID_C 15 "Idle" 5 "Stuck" 4 "LongEvent" 3 "ShortElapsed" 2 "ShortEvent" 1 "Active" 0 "Inactive" ;
VAL_ 673 ICI_Coding_BtnID_B 15 "Idle" 5 "Stuck" 4 "LongEvent" 3 "ShortElapsed" 2 "ShortEvent" 1 "Active" 0 "Inactive" ;
VAL_ 673 ICI_Coding_BtnID_A 15 "Idle" 5 "Stuck" 4 "LongEvent" 3 "ShortElapsed" 2 "ShortEvent" 1 "Active" 0 "Inactive" ;
VAL_ 820 AhbStatGfhbFdbk_D_Actl 3 "GfhbHighBeamFullyOn" 2 "GfhbHighBeamPartlyOn" 1 "GfhbHighBeamOff" 0 "GfhbUnavailable" ;
VAL_ 820 HeadLghtDrvSide_B_Stat 1 "Left_Hand_Traffic" 0 "Right_Hand_Traffic" ;
VAL_ 820 HeadLghtHiOn_B_StatHcm 1 "On" 0 "Off" ;
VAL_ 820 Adaptive_Hdlmp_Fault 1 "Yes" 0 "No" ;
VAL_ 1073 CamraFrntBttn_D_Stat 1 "Pressed" 0 "Not_Pressed" ;
VAL_ 1073 CamraFrntBttn_D_Stat_UB 1 "Fresh_data" 0 "Unchanged_data" ;
VAL_ 1073 BrkDrvMde_D_Rq_UB 1 "Fresh_data" 0 "Unchanged_data" ;
VAL_ 1073 BrkDrvMde_D_Rq 7 "Faulty" 6 "RockCrawl" 5 "Baja" 4 "DragOrMudAndSand" 3 "Track" 2 "Snow_Wet" 1 "Sport" 0 "Normal" ;
VAL_ 1073 SteEffort_D_Rq 7 "NotUsed_3" 6 "NotUsed_2" 5 "NotUsed_1" 4 "SpecialMode_2" 3 "SpecialMode_1" 2 "Comfort" 1 "Sport" 0 "Normal" ;
VAL_ 1073 AutoHoldSwtch_D_Stat_UB 1 "Fresh_data" 0 "Unchanged_data" ;
VAL_ 1073 AutoHoldSwtch_D_Stat 3 "Faulty" 2 "NotUsed" 1 "Pressed" 0 "Not_Pressed" ;
VAL_ 1073 HMI_HMIMode_St_UB 1 "Fresh_data" 0 "Unchanged_data" ;
VAL_ 1073 HMI_HMIMode_St 7 "NotUsed2" 6 "NotUsed1" 5 "Load_Shed_Active" 0 "Invalid" 1 "OffMode" 2 "On" 3 "Phone" 4 "Climate" ;
VAL_ 1073 Veh_Lock_Requestor_UB 1 "Fresh_data" 0 "Unchanged_data" ;
VAL_ 1073 Veh_Lock_EvNum_UB 1 "Fresh_data" 0 "Unchanged_data" ;
VAL_ 1073 Veh_Lock_Sub_Id_UB 1 "Fresh_data" 0 "Unchanged_data" ;
VAL_ 1073 Tire_Press_System_Stat_UB 1 "Fresh_data" 0 "Unchanged_data" ;
VAL_ 1073 Veh_Lock_Status_UB 1 "Fresh_data" 0 "Unchanged_data" ;
VAL_ 1073 Veh_Lock_Sub_Id 15 "Unused7" 14 "Unused6" 13 "Unused5" 12 "Unused4" 11 "Unused3" 10 "Unused2" 9 "Unused1" 8 "Customer_8" 7 "Customer_7" 6 "Customer_6" 5 "Customer_5" 4 "Customer_4" 3 "Customer_3" 2 "Customer_2" 1 "Customer_1" 0 "Null" ;
VAL_ 1073 Veh_Lock_Status 3 "UNLOCK_DRV" 2 "UNLOCK_ALL" 1 "LOCK_ALL" 0 "LOCK_DBL" ;
VAL_ 1073 Veh_Lock_Requestor 31 "Walk_Away_Locking" 30 "Remote_Park_Assist" 29 "DoorsOffToOn_Smart_Unlock" 28 "Rgtm_Shutlock_Switch" 27 "Boundary_Alert" 26 "Transit_Vehicle_Relock" 25 "Transit_Cargo_Relock" 24 "Transit_Ajar_Lock" 23 "Diagnostics" 22 "Console_Lock" 21 "Child_Lock" 20 "Double_Lock" 19 "Passive_Pasenger" 18 "Passive_Driver" 17 "Slam_Lock_Protect" 16 "SYNC" 15 "Passport" 14 "Passive_Smart_Unlock" 13 "Autorelock" 12 "RemoteStart" 0 "Null" 1 "Autolock" 11 "Smart_Unlock" 10 "Sliding_Door" 9 "Passive" 8 "Remote" 7 "Programming" 6 "Powerslide" 5 "Keypad" 4 "Key_Cylinder" 3 "Interior" 2 "Auto_Unlock" ;
VAL_ 1073 Tire_Press_System_Stat 13 "Training_Complete" 12 "Train_InsideLeftRear_tire" 11 "Train_OutsideLeftRear_tire" 10 "Train_LeftRear_tire" 9 "Train_InsideRtRear_tire" 8 "Train_OutsideRtRear_tire" 7 "Train_RightRear_tire" 14 "Tires_not_trained" 6 "Train_RightFront_tire" 5 "Train_LeftFront_tire" 4 "Systm_Activ_Composite_Stat" 3 "Low_Composite_Stat" 2 "Sensr_Fault_Composite_Stat" 1 "Systm_Fault_Composite_Stat" 0 "Unknown_Composite_Stat" ;
VAL_ 1073 DISPLAY_SPEED_OFFSET_UB 1 "Fresh_data" 0 "Unchanged_data" ;
VAL_ 1073 DISPLAY_SPEED_SCALING_UB 1 "Fresh_data" 0 "Unchanged_data" ;
VAL_ 1073 SteWhlHeat_D_Rq_UB 1 "Fresh_data" 0 "Unchanged_data" ;
VAL_ 1073 SteWhlHeat_D_Rq 15 "NotUsed6" 14 "NotUsed5" 13 "NotUsed4" 12 "NotUsed3" 11 "NotUsed2" 10 "NotUsed1" 9 "Reserved_3" 8 "Reserved_2" 7 "Reserved_1" 6 "Level_3_Heating" 5 "Level_3_Heating_LS" 4 "Level_2_Heating" 3 "Level_2_Heating_LS" 2 "Level_1_Heating" 1 "Level_1_Heating_LS" 0 "Off" ;
VAL_ 1091 TrlrAlarmSpprt_D_Stat 3 "SupportedByBrakesAndLights" 2 "SupportedByLights" 1 "SupportedByBrakes" 0 "NotSupported" ;
VAL_ 1091 ParkLampTrlrOut_B_Stat 1 "Out" 0 "Null" ;
VAL_ 1091 StopLampTrlrOut_B_Stat 1 "Out" 0 "Null" ;
VAL_ 1091 TrlrBattChrg_D_Stat 3 "Reverse" 2 "Normal" 1 "Low" 0 "Null" ;
VAL_ 1091 TrlrLampCtl_D_Stat 3 "NotUsed" 2 "TrlrLampCnnctDrvFailure" 1 "TrlrLampNotCnnctDrvFailure" 0 "Null" ;
VAL_ 1091 TurnLampTrlrRr_B_Stat 1 "Out" 0 "Null" ;
VAL_ 1091 TurnLampTrlrRl_B_Stat 1 "Out" 0 "Null" ;
VAL_ 1091 TrlrLampCnnct_B_Actl 1 "Yes" 0 "No" ;
VAL_ 1068 EngStrtInhbt_B_RqBatt 1 "Start_Inhibit" 0 "Dont_Care" ;
VAL_ 1068 BattULoChrg_D_Rq 3 "Low_Battery_Temperature" 2 "Charging_Requested" 1 "Chrg_Requested_HighCurrent" 0 "No_Request" ;
VAL_ 1068 PwSysULoFalt_D_Stat 15 "Not_Used_6" 14 "LowBatterySOC" 13 "PSS_Shed2_Contin" 12 "Not_Used_4" 11 "Not_Used_3" 10 "Not_Used_2" 9 "BattMonitoringSensorFault" 8 "LowBattVoltDuringPwSrcOn" 7 "LowBatt2_PowerSaveMode" 6 "LowBatt1_Warning" 5 "Overvoltage" 4 "Fault_NoOutput" 3 "Fault_ReducedOutput" 2 "Fault_Nonspecific" 1 "Cluster_Proveout" 0 "No_Fault" ;
VAL_ 1068 Shed_T_Eng_Off_B 1 "Active" 0 "Inactive" ;
VAL_ 1068 Shed_Feature_Group_ID 16 "PtcHeater" 30 "NotUsed_7" 29 "NotUsed_6" 28 "NotUsed_5" 27 "NotUsed_4" 26 "NotUsed_3" 25 "NotUsed_2" 24 "NotUsed_1" 23 "Dcac" 22 "UpFitter_6" 21 "UpFitter_5" 20 "UpFitter_4" 19 "UpFitter_3" 18 "UpFitter_2" 17 "UpFitter_1" 14 "HtdMirr" 13 "HvacRearBlwr_Third" 12 "HvacRearBlwr_Second" 11 "HvacRearBlwr_First" 31 "All LSHED1 Features" 10 "Htd_Windscrn" 9 "SpltHtdBcklight_HtdMirr" 8 "HtdBcklight_HtdMirr" 7 "HtdCoolSeat_FrtDriver" 6 "HtdCoolSeat_FrtPass" 5 "HtdCoolSeat_RearPass" 4 "HtdCoolSeat_RearDriver" 3 "SmartTrlrTowBattCharge" 2 "Htd_StrWhl" 1 "Htd_Washer_Fluid" 0 "No_LSHED1_Features" 15 "Engine_Coolant_Fan" ;
VAL_ 1068 Shed_Drain_Eng_Off_B 1 "Active" 0 "Inactive" ;
VAL_ 1068 Shed_Level_Req 7 "SHED3" 6 "Loads_On" 5 "SHED_ENG_OFF" 4 "SOON_ENG_OFF" 3 "SHED2_CONTIN" 2 "SHED2_TRANS" 1 "SHED1" 0 "NO_SHED" ;
VAL_ 1068 ChargeMode 7 "Undefined_2" 6 "Undefined_1" 5 "Battery_Identify" 4 "Battery_Refresh" 3 "SlowRegenAllowNoDischarge" 2 "Fast_Regen_Allowed" 1 "Slow_Regen_Allowed" 0 "Conventional_Charging" ;
VAL_ 1068 IdleSpeedIncrease_El 1 "Yes" 0 "No" ;
VAL_ 1068 Batt_Lo_SoC_B 1 "Active" 0 "Inactive" ;
VAL_ 1068 PeriodicElLoad_B_Stat 1 "Active" 0 "Inactive" ;
VAL_ 1068 Batt_Crit_SoC_B 1 "Active" 0 "Inactive" ;
VAL_ 1068 ULoRgenTestMde_B_Rq 1 "Request" 0 "NoRequest" ;
VAL_ 611 AwdTerrMdeChng_D_Rdy 7 "Fault" 6 "Undefined_2" 5 "Undefined_1" 4 "ModeUnavailDrInputRqd" 3 "SpOpModes_NotSupported" 2 "ModeUnavailDynamicCond" 1 "Module_In_Initialization" 0 "Mode_Change_Available" ;
VAL_ 611 AwdTerrMde_D_Actl 7 "Fail_Safe_Default" 6 "Dynamic_Mode" 5 "Rock_Crawl_Mode" 4 "Mud_Ruts_Mode" 3 "Sand_Mode" 2 "Undefined" 1 "Low_Mu_Mode" 0 "Special_Operating_Mode_Off" ;
VAL_ 611 AwdSys_D_Stat 3 "Faulty" 2 "NotUsed" 1 "_4x4_L_H_Active" 0 "_4x4_L_H_Inactive" ;
VAL_ 611 SelDrvMdeAwd_D_Stat 0 "NotAvailable" 1 "Available" 2 "TemporarilyNotAvailable" 3 "Faulty" ;
VAL_ 611 AwdStat_D_RqDsply 31 "Rear_Diff_Lock_Not_Avail" 30 "_4wd_Lock_Required" 29 "Cfg_Perf_Redc_See_Manual" 28 "To_Engage_4x4_Release_Aped" 27 "To_Engage_4x4_Slow_To_3MPH" 26 "Shift_To_Neutral" 25 "Lkr_Mode_Unavail_TMS" 24 " _4x4_Mode_Unavail_TMS" 23 "Out_of_4Low_Crawl" 22 "AWD_PTU_Oil_Changed" 21 "Change_AWD_PTU_Oil" 20 "Neutral_Tow_Disabled" 19 "Neutral_Tow_Enabled" 18 "AWD_OFF" 17 "_4x4_Off_Road_Speed" 16 "_4x4_Extreme_Off_Road_Mode" 15 "_4x4_Exiting_Off_Road" 14 "_4x4_Off_Road_Mode" 10 "_4x4_Locked_Temporarily" 9 "Shift_In_Progress" 13 "Blocked_Shift_Assist" 12 "_4x4_Auto_Restored" 11 "_4x4_Disabled_Temporarily" 7 "Out_of_4Low__Neutral" 6 "Out_of_4Low__Brake" 5 "Out_of_4Low__Speed" 4 "Into_4Low__Clutch" 3 "Into_4Low__Neutral" 2 "Into_4Low__Brake" 1 "Into_4Low__Speed" 0 "Normal__No_Message" 8 "Out_of_4Low__Clutch" ;
VAL_ 611 AwdLck_D_Stat 9 "Undefined" 8 "Under_External_Torque_Ctrl" 7 "Torque_Limited_by_Cmd" 6 "Fully_Locked_by_Cmd" 5 "Disabled" 4 "Warning" 3 "Fault" 2 "Inactive" 1 "Completely_Opened_by_Cmd" 0 "OK" ;
VAL_ 611 AwdSrvcRqd_B_Rq 1 "On" 0 "Off" ;
VAL_ 611 NtrlTowAvail_B_Stat 1 "Available" 0 "NotAvailable" ;
VAL_ 611 AwdLck_Tq_Rq 4095 "Fault" 4094 "Unknown" ;
VAL_ 611 AwdOffRoadMode_D_Stats 3 "Invalid" 2 "Extreme_Off_Road" 1 "Off_Road" 0 "Normal_Mode" ;
VAL_ 611 AwdLoLamp_D_RqDsply 3 "Not_Used" 2 "Flash" 1 "On" 0 "Off" ;
VAL_ 611 AwdHiLamp_D_RqDsply 3 "Not_Used" 2 "Flash" 1 "On" 0 "Off" ;
VAL_ 611 AwdAutoLamp_D_RqDsply 3 "Not_Used" 2 "Flash" 1 "On" 0 "Off" ;
VAL_ 611 Awd2wdLamp_D_RqDsply 3 "Not_Used" 2 "Flash" 1 "On" 0 "Off" ;
VAL_ 611 AwdRnge_D_Actl 7 "Unknown" 6 "High_Range_2wd" 5 "High_Range_Auto" 4 "High_Range_Locked" 3 "Neutral" 2 "Low_Range_2wd" 1 "Low_Range_Auto" 0 "Low_Range_Locked" ;
VAL_ 578 immoSecureIdleMode 3 "NotUsed2" 2 "NotUsed1" 1 "Active" 0 "Inactive" ;
VAL_ 578 FuelPumpPwr_D_Stat 7 "NotUsed3" 6 "NotUsed2" 5 "NotUsed1" 4 "Power_Off_Default" 3 "Power_Off_Command" 2 "Power_Off_Service" 1 "Power_Off_Impact" 0 "Power_On" ;
VAL_ 578 BattULo_U_Actl 255 "Fault" ;
VAL_ 578 PrkLckCtl_B_Enbl 1 "Enable" 0 "Disable" ;
VAL_ 578 PrkLckCtlMsgTxt_D_Rq 3 "BTSI_DI_3" 2 "BTSI_DI_2" 1 "BTSI_DI_1" 0 "Null_BTSI_DI" ;
VAL_ 578 BrkTrnShifLck_B_Stat 1 "Shift" 0 "NoShift" ;
VAL_ 578 DriverCrankingReq 1 "Crank_Request" 0 "No_Crank_Request" ;
VAL_ 578 EngOff_T_Actl 65535 "Invalid" ;
VAL_ 578 ReFuelSwtchStat_D_Actl 3 "NotUsed2" 2 "NotUsed1" 1 "On" 0 "Off" ;
VAL_ 578 DcacElPw_D_Rq 3 "NotUsed" 2 "AC_HighPower_Requested" 1 "AC_LowPower_Requested" 0 "AC_Power_NotRequested" ;
VAL_ 578 BattULo_I_Actl 16383 "Fault" ;
VAL_ 560 SelDrvMdeSwtch_D_Stat3 3 "Faulty" 2 "SwitchState2" 1 "SwitchState1" 0 "NotPressed" ;
VAL_ 560 TrnSrvcRqd_B_Rq 1 "On" 0 "Off" ;
VAL_ 560 TrnCnvtClu_D_Actl 3 "Transition_or_Micro_Slip" 2 "Lock_Up_Fixed" 1 "Lock_Up_Slip" 0 "No_Lock_Up" ;
VAL_ 560 TrnShifActv_B_Actl 1 "Active" 0 "Inactive" ;
VAL_ 560 GearLvrPos_D_Actl 15 "Fault" 14 "Unknown_Position" 13 "Undefined_Treat_as__Fault" 12 "Undefined_Treat_as_Fault" 11 "sixth" 10 "fifth" 9 "fourth" 8 "third" 7 "second" 6 "first" 5 "Low" 4 "Sport_DriveSport" 3 "Drive" 2 "Neutral" 1 "Reverse" 0 "Park" ;
VAL_ 560 GboxOil_Te_Actl 255 "Faulty" 254 "NoDataExists" ;
VAL_ 359 ElPw_D_StatStrtStop 15 "NotUsed6" 14 "NotUsed5" 13 "NotUsed4" 12 "NotUsed3" 11 "NotUsed2" 10 "NotUsed1" 9 "Supported_Level_4" 8 "Supported_Level_3" 7 "Supported_Level_2" 6 "Supported_Level_1" 5 "Limited_Support" 4 "Fault_Limited" 3 "LV_Event_in_Progress" 2 "Not_Supported_Imminent" 1 "Supported_All" 0 "Not_Supported" ;
VAL_ 359 PrplWhlTot2_Tq_Actl 65535 "Fault" 65534 "NoDataExists" ;
VAL_ 359 PwPckTq_D_Stat 3 "PwPckOn_TqAvailable" 2 "StartInPrgrss_TqNotAvail" 1 "PwPckOn_TqNotAvailable" 0 "PwPckOff_TqNotAvailable" ;
VAL_ 359 Eng_D_Stat 3 "NotUsed" 2 "EngAutoStopped" 1 "EngOn" 0 "EngOff" ;
VAL_ 359 ElPw_D_Stat 7 "NotUsed_3" 6 "NotUsed_2" 5 "NotUsed_1" 4 "Fault_Limited" 3 "LV_Event_In_Progress" 2 "Not_Supported_Imminent" 1 "Supported" 0 "Not_Supported" ;
VAL_ 359 TrnAinTq_D_Qf 3 "OK" 2 "Not_Within_Specifications" 1 "No_Data_Exists" 0 "Faulty" ;
VAL_ 357 BPedDrvAppl_D_QF 3 "OK" 2 "Not_Within_Specifications" 1 "No_Data_Exists" 0 "Faulty" ;
VAL_ 357 CmbbDeny_B_ActlPrpl 1 "Yes" 0 "No" ;
VAL_ 357 PrplTqMnSat_B_Actl 1 "Yes" 0 "No" ;
VAL_ 357 BpedDrvAppl_D_Actl 3 "_Not_Allowed" 2 "Driver_Braking" 1 "Driver_Not_Braking" 0 "Not_Allowed" ;
VAL_ 357 CmbbEngTqMn_B_Actl 1 "Yes" 0 "No" ;
VAL_ 357 Veh_V_DsplyCcSet 255 "Fault" 254 "Unknown" ;
VAL_ 357 AccEngStat_D_Actl 7 "Undefined_2" 6 "Undefined_1" 5 "ACCSoonCancel_due_Low_Spd" 4 "Shift_Down_Recommendation" 3 "Shift_Up_Recommendation" 2 "ACCNotAllowedToBeActivated" 1 "ACCStandby_due_Auto_Cancel" 0 "Normal_Operation" ;
VAL_ 357 CcMde_D_Actl 7 "TapDownWaiting" 6 "TapUpWaiting" 5 "Resuming_Low" 4 "Resuming_High" 3 "Decelerating" 2 "Accelerating" 1 "Keeping_Speed" 0 "Not_Active" ;
VAL_ 357 CcStat_D_Actl 7 "Undefined_2" 6 "Undefined_1" 5 "Active" 4 "Active_Que_Assist" 3 "Standby" 2 "Standby_Denied" 1 "Denied" 0 "Off" ;
VAL_ 357 CcOvrrdActv_B_Actl 1 "Cruise_Overridden" 0 "Cruise_Req_Not_Overridden" ;
VAL_ 357 AccStopMde_D_Rq 3 "Stop_Mode_Active" 2 "EPBApplyOrBrakeReleaseWarn" 1 "Limit_Rolling_Speed" 0 "Stop_Mode_Not_Active" ;
VAL_ 390 AccAutoResum_D_Rq 3 "NotUsed" 2 "Active" 1 "Pending" 0 "Off" ;
VAL_ 390 AccBrkPrkEl_B_Rq 1 "Yes" 0 "No" ;
VAL_ 390 Cmbb_B_Enbl 1 "Yes" 0 "No" ;
VAL_ 390 CmbbOvrrd_B_RqDrv 1 "Yes" 0 "No" ;
VAL_ 390 CmbbDeny_B_Actl 1 "Yes" 0 "No" ;
VAL_ 390 CmbbEngTqMn_B_Rq 1 "Yes" 0 "No" ;
VAL_ 390 AccDeny_B_Rq 1 "Yes" 0 "No" ;
VAL_ 390 AccResumEnbl_B_Rq 1 "Yes" 0 "No" ;
VAL_ 390 AccCancl_B_Rq 1 "Yes" 0 "No" ;
VAL_ 390 AccBrkPrchg_B_Rq 1 "Yes" 0 "No" ;
VAL_ 390 AccBrkDecel_B_Rq 1 "Active" 0 "Inactive" ;
VAL_ 390 AccStopStat_B_Rq 1 "Yes" 0 "No" ;
VAL_ 1071 CluPdlPosPcMeas_D_Qf 3 "OK" 2 "Not_Within_Specifications" 1 "No_Data_Exists" 0 "Faulty" ;
VAL_ 1072 HdcOn_B_Rq_UB 1 "Fresh_data" 0 "Unchanged_data" ;
VAL_ 1072 TrlrAidCancl_B_Rq_UB 1 "Fresh_data" 0 "Unchanged_data" ;
VAL_ 1072 TrlrAidCancl_B_Rq 1 "Cancel" 0 "Null" ;
VAL_ 1072 HdcOn_B_Rq 1 "On" 0 "Off" ;
VAL_ 1072 HsaMde_D_Rq 3 "Undefined" 2 "Manual" 1 "Automatic" 0 "Off" ;
VAL_ 1072 HsaMde_D_Rq_UB 1 "Fresh_data" 0 "Unchanged_data" ;
VAL_ 1072 LscmbbStat_B_Actl 1 "On" 0 "Off" ;
VAL_ 1072 LscmbbStat_B_Actl_UB 1 "Fresh_data" 0 "Unchanged_data" ;
VAL_ 1072 Outside_Air_Temp_Stat_UB 1 "Fresh_data" 0 "Unchanged_data" ;
VAL_ 1072 Outside_Air_Temp_Stat 255 "Invalid" 254 "Unknown" ;
VAL_ 1072 BulbChkActv_B_Stat_UB 1 "Fresh_data" 0 "Unchanged_data" ;
VAL_ 1072 BulbChkActv_B_Stat 1 "Active" 0 "Inactive" ;
VAL_ 1072 Fda_B_Stat_UB 1 "Fresh_data" 0 "Unchanged_data" ;
VAL_ 1072 AccEnbl_B_RqDrv_UB 1 "Fresh_data" 0 "Unchanged_data" ;
VAL_ 1072 AccDeny_B_RqIpc_UB 1 "Fresh_data" 0 "Unchanged_data" ;
VAL_ 1072 OdometerMasterValue_UB 1 "Fresh_data" 0 "Unchanged_data" ;
VAL_ 1072 OdometerMasterValue 16777215 "Invalid" ;
VAL_ 1072 Fda_B_Stat 1 "On" 0 "Off" ;
VAL_ 1072 AccDeny_B_RqIpc 1 "Yes" 0 "No" ;
VAL_ 1072 AccEnbl_B_RqDrv 1 "Adaptive_Cruise" 0 "Normal_Cruise" ;
VAL_ 1072 DrvSlipCtlMde_D_Rq_UB 1 "Fresh_data" 0 "Unchanged_data" ;
VAL_ 1072 DrvSlipCtlMde_D_Rq 3 "App_Specific_Off_Mode_3" 2 "App_Specific_Off_Mode_2" 1 "App_Specific_Off_Mode_1" 0 "Default_Mode" ;
VAL_ 1072 DrvSlipCtlMde_B_Rq_UB 1 "Fresh_data" 0 "Unchanged_data" ;
VAL_ 1072 ePRNDL_MODE_UB 1 "Fresh_data" 0 "Unchanged_data" ;
VAL_ 1072 ePRNDL_MODE 1 "On" 0 "Off" ;
VAL_ 1072 TrlrBrkMde_D_Rq 1 "ElectricOverHydraulic" 0 "Electric" ;
VAL_ 1072 TRLR_SWAY_CONFIG_CMD 1 "On" 0 "Off" ;
VAL_ 1072 TRAILER_BRAKE_CONFIG 1 "Yes" 0 "No" ;
VAL_ 1072 TrlrBrkMde_D_Rq_UB 1 "Fresh_data" 0 "Unchanged_data" ;
VAL_ 1072 TRAILER_BRAKE_CONFIG_UB 1 "Fresh_data" 0 "Unchanged_data" ;
VAL_ 1058 WndwFrontHeat_B_Stat_UB 1 "Fresh_data" 0 "Unchanged_data" ;
VAL_ 1058 WndwFrontHeat_B_Stat 1 "On" 0 "Off" ;
VAL_ 1058 HILL_DESC_SW_UB 1 "Fresh_data" 0 "Unchanged_data" ;
VAL_ 1058 HILL_DESC_SW 1 "On" 0 "Off" ;
VAL_ 1058 EngClntTe_D_Qf 3 "OK" 2 "Not_Within_Specifications" 1 "No_Data_Exists" 0 "Faulty" ;
VAL_ 1058 EngClnt_Te_Actl_UB 1 "Fresh_data" 0 "Unchanged_data" ;
VAL_ 1058 TrnTotTq_Rt_Est_UB 1 "Fresh_data" 0 "Unchanged_data" ;
VAL_ 1058 TrnTotLss_Tq_Est_UB 1 "Fresh_data" 0 "Unchanged_data" ;
VAL_ 1058 TrnTotTq_Rt_Est 65535 "Fault" 65534 "Unknown" ;
VAL_ 1058 TrnTotLss_Tq_Est 255 "Fault" 254 "Unknown" ;
VAL_ 1058 DrvSlipCtlMde_B_Rq2_UB 1 "Fresh_data" 0 "Unchanged_data" ;
VAL_ 1058 DrvSlipCtlMde_B_Rq2 1 "Pressed" 0 "Not_Pressed" ;
VAL_ 1082 EsaOn_B_Rq_UB 1 "Fresh_data" 0 "Unchanged_data" ;
VAL_ 1082 EsaOn_B_Rq 1 "On" 0 "Off" ;
VAL_ 1082 RearDiffLck_D_RqArb_UB 1 "Fresh_data" 0 "Unchanged_data" ;
VAL_ 1082 RearDiffLck_D_RqArb 3 "Faulty" 2 "NotUsed" 1 "On" 0 "Off" ;
VAL_ 1082 AwdMde_D_RqArb_UB 1 "Fresh_data" 0 "Unchanged_data" ;
VAL_ 1082 AwdMde_D_RqArb 7 "Faulty" 6 "NotUsed2" 5 "NoRequest" 4 "Neutral" 3 "FourByFourLow" 2 "FourByFourHigh" 1 "FourByFourAuto" 0 "FourByTwo" ;
VAL_ 1082 SelDrvMdeTxtReset_B_Rq_UB 1 "Fresh_data" 0 "Unchanged_data" ;
VAL_ 1082 SelDrvMdeTxtReset_B_Rq 1 "Yes" 0 "No" ;
VAL_ 1082 SelDrvMdeDsply_B_Avail_UB 1 "Fresh_data" 0 "Unchanged_data" ;
VAL_ 1082 AirSusp_D_RqDrv_UB 1 "Fresh_data" 0 "Unchanged_data" ;
VAL_ 1082 DrvInputRequired_B_Rq_UB 1 "Fresh_data" 0 "Unchanged_data" ;
VAL_ 1082 DrvInputRequired_B_Rq 1 "Yes" 0 "No" ;
VAL_ 1082 SelDrvMdeSwtch_D_Stat2_UB 1 "Fresh_data" 0 "Unchanged_data" ;
VAL_ 1082 SelDrvMdeSwtch_D_Stat2 3 "Faulty" 2 "SwitchState2" 1 "SwitchState1" 0 "NotPressed" ;
VAL_ 1082 FapLcStopHold_B_Rq 1 "Yes" 0 "No" ;
VAL_ 1082 SelDrvMdeDsply_B_Avail 1 "Available" 0 "NotAvailable" ;
VAL_ 1082 FapLcStopHold_B_Rq_UB 1 "Fresh_data" 0 "Unchanged_data" ;
VAL_ 1082 FapLcPrchgBrk_B_Rq_UB 1 "Fresh_data" 0 "Unchanged_data" ;
VAL_ 1082 AirSusp_D_RqDrv 3 "NotUsed" 2 "On" 1 "Off" 0 "NoModeSelected" ;
VAL_ 1082 AwdRnge_D_ActlIpc_UB 1 "Fresh_data" 0 "Unchanged_data" ;
VAL_ 1082 AwdRnge_D_ActlIpc 7 "Unknown" 6 "High_Range_2wd" 5 "High_Range_Auto" 4 "High_Range_Locked" 3 "Neutral" 2 "Low_Range_2wd" 1 "Low_Range_Auto" 0 "Low_Range_Locked" ;
VAL_ 1082 NtrlTowMdeEnbl_B_RqDrv_UB 1 "Fresh_data" 0 "Unchanged_data" ;
VAL_ 1082 NtrlTowMdeEnbl_B_RqDrv 1 "Yes" 0 "No" ;
VAL_ 1082 DrvSlipCtlMde_B_RqMyKey_UB 1 "Fresh_data" 0 "Unchanged_data" ;
VAL_ 1082 DrvSlipCtlMde_B_RqMyKey 1 "On" 0 "Off" ;
VAL_ 1082 AwdDrvMde_D_Rq_UB 1 "Fresh_data" 0 "Unchanged_data" ;
VAL_ 1082 AwdDrvMde_D_Rq 7 "Faulty" 6 "NotAvailable" 5 "RockCrawl" 4 "Baja" 3 "MudAndSand" 2 "Weather" 1 "Sport" 0 "Normal" ;
VAL_ 1082 MetricActv_B_Actl_UB 1 "Fresh_data" 0 "Unchanged_data" ;
VAL_ 1082 MetricActv_B_Actl 1 "Active" 0 "Inactive" ;
VAL_ 1082 BrkLineLck_D_Rq_UB 1 "Fresh_data" 0 "Unchanged_data" ;
VAL_ 1082 BrkLineLck_D_Rq 3 "Off" 2 "Engage" 1 "Initiate" 0 "NoRequest" ;
VAL_ 1082 SuspDrvMde_D_Rq_UB 1 "Fresh_data" 0 "Unchanged_data" ;
VAL_ 1082 SuspDrvMde_D_Rq 7 "Faulty" 6 "NotUsed2" 5 "NotUsed1" 4 "Drag" 3 "Track" 2 "Snow_Wet" 1 "Sport" 0 "Normal" ;
VAL_ 1082 SelDrvMdePt_D_Stat_UB 1 "Fresh_data" 0 "Unchanged_data" ;
VAL_ 1082 SelDrvMdePt_D_Stat 0 "NotAvailable" 1 "Available" 2 "TemporarilyNotAvailable" 3 "Faulty" ;
VAL_ 92 TrnSbwSysHlth_D_Actl 3 "OK" 2 "Degraded" 1 "No_Data_Exists" 0 "Faulty" ;
VAL_ 92 TrnDtpCmd_D_Actl 7 "NotUsed4" 6 "NotUsed3" 5 "NotUsed2" 4 "Relatch" 3 "Deploy" 2 "Self_Test" 1 "No_Command" 0 "NotUsed1" ;
VAL_ 92 GearSelLck_D_Rq 3 "PreventionBlocker" 2 "Unlock" 1 "Lock" 0 "Null" ;
VAL_ 92 TrnValidGear_D_Cnfm 3 "Accept" 2 "Reject" 1 "Internal_Request" 0 "No_Command" ;
VAL_ 92 TrnNtrlTowCmd_D_Actl 3 "NotUsed" 2 "Neutral_Tow_Entry" 1 "Car_Wash_Mode" 0 "Normal_Mode" ;
VAL_ 92 TrnGearCmd_Pc_ActlPt 1023 "Fault" ;
VAL_ 92 TrnGear_D_RqPt 7 "Fault" 6 "NotUsed" 5 "Manual" 4 "Drive" 3 "Neutral" 2 "Reverse" 1 "Park" 0 "No_Gear" ;
VAL_ 92 TrnCmdState_B_Actl 1 "Yes" 0 "No" ;
VAL_ 92 PrkBrkActv_D_RqTrnGear 3 "NotUsed2" 2 "RequestParkBrakeEngage" 1 "NoRequest" 0 "NotUsed1" ;
VAL_ 360 GsmSrvcRqd_B_Rq 1 "Yes" 0 "No" ;
VAL_ 360 TrnGearPwmFalt_B_Actl 1 "Yes" 0 "No" ;
VAL_ 360 GearButtnStuck_B_Actl 1 "Yes" 0 "No" ;
VAL_ 90 TrnGsmNtmState_D_Actl 3 "Faulty" 2 "Neutral_Tow_Mode" 1 "Car_Wash_Mode" 0 "None" ;
VAL_ 90 DrQltyDrv_D_StatGsm 7 "Faulty" 6 "NoDataExists" 5 "NotUsed2" 4 "NotUsed1" 3 "ClosedDegraded" 2 "OpenDegraded" 1 "ClosedOkay" 0 "OpenOkay" ;
VAL_ 90 TrnBtsiOvrrd_B_Stat 1 "Override" 0 "Null" ;
VAL_ 90 GsmGearMsgTxt_D_Rq 3 "Message3" 2 "Message2" 1 "Message1" 0 "NoMessage" ;
VAL_ 90 TrnRng_D_RqGsm 15 "Fault" 14 "UnknownPosition" 13 "Undefined_2" 12 "Undefined_1" 11 "_6" 10 "_5" 9 "_4" 8 "_3" 7 "_2" 6 "_1" 5 "Low" 4 "Sport_DriveSport" 3 "Drive" 2 "Neutral" 1 "Reverse" 0 "Park" ;
VAL_ 90 PrkBrkActv_D_RqGsmGear 3 "NotUsed" 2 "RequestParkBrakeEngage" 1 "NoRequest" 0 "Null" ;
VAL_ 90 TrnValidGearRq_D_Stat 3 "Valid_Request" 2 "Valid_Degraded_Request" 1 "Invalid_Request" 0 "No_Request" ;
VAL_ 90 TrnGearButtn_U_Actl 255 "Fault" ;
VAL_ 90 TrnGearButtn_B_ActlR2 1 "Yes" 0 "No" ;
VAL_ 90 TrnGearButtn_B_ActlR1 1 "Yes" 0 "No" ;
VAL_ 90 TrnGearButtn_B_ActlR0 1 "Yes" 0 "No" ;
VAL_ 90 TrnGearButtn_B_ActlP2 1 "Yes" 0 "No" ;
VAL_ 90 TrnGearButtn_B_ActlP1 1 "Yes" 0 "No" ;
VAL_ 90 TrnGearButtn_B_ActlP0 1 "Yes" 0 "No" ;
VAL_ 90 TrnGearButtn_B_ActlN2 1 "Yes" 0 "No" ;
VAL_ 90 TrnGearButtn_B_ActlN1 1 "Yes" 0 "No" ;
VAL_ 90 TrnGearButtn_B_ActlN0 1 "Yes" 0 "No" ;
VAL_ 90 TrnGearButtn_B_ActlM2 1 "Yes" 0 "No" ;
VAL_ 90 TrnGearButtn_B_ActlM1 1 "Yes" 0 "No" ;
VAL_ 90 TrnGearButtn_B_ActlM0 1 "Yes" 0 "No" ;
VAL_ 90 TrnGearButtn_B_ActlD2 1 "Yes" 0 "No" ;
VAL_ 90 TrnGearButtn_B_ActlD1 1 "Yes" 0 "No" ;
VAL_ 90 TrnGearButtn_B_ActlD0 1 "Yes" 0 "No" ;
VAL_ 90 TrnGear_D_RqDrv 31 "Fault" 30 "NotUsed_25" 29 "NotUsed_24" 28 "NotUsed_23" 27 "NotUsed_22" 26 "Return_to_Park" 25 "NotUsed_20" 24 "NotUsed_19" 23 "NotUsed_18" 22 "NotUsed_17" 21 "Return_To_Park" 20 "NotUsed_15" 19 "NotUsed_14" 18 "NotUsed_13" 17 "NotUsed_12" 16 "Manual" 15 "Not_Used11" 14 "Not_Used10" 13 "NotUsed_9" 12 "NotUsed_8" 11 "NotUsed_7" 10 "NotUsed_6" 9 "NotUsed_5" 8 "Drive" 7 "NotUsed_4" 6 "NotUsed_3" 5 "NotUsed_2" 4 "Neutral" 3 "NotUsed_1" 2 "Reverse" 1 "Park" 0 "No_Gear" ;
VAL_ 90 BrkSwtchPos_B_ActlGsm 1 "Yes" 0 "No" ;
VAL_ 936 ApaButtnPrssd_B_Stat 1 "Pressed" 0 "Not_Pressed" ;
VAL_ 936 ApaChime_D_Rq 7 "NotUsed2" 6 "NotUsed1" 5 "Warning_Chime" 4 "Finish_Chime" 3 "Stop_Now_Chime" 2 "Spot_Ready_Chime" 1 "Spot_Found_Chime" 0 "No_Chime" ;
VAL_ 936 ApaSys_D_Stat 7 "Faulty" 6 "Finished" 5 "NotAccessible" 4 "ApaCancelled" 3 "Overspeed" 2 "On" 1 "Off" 0 "Null" ;
VAL_ 936 ApaSteWhl_D_RqDrv 3 "TakeControl" 2 "RemoveHands" 1 "NoRequest" 0 "Null" ;
VAL_ 936 ApaSteScanMde_D_Stat 3 "Steering" 2 "Scanning" 1 "NotScanning" 0 "Null" ;
VAL_ 936 ApaSelSapp_D_Stat 3 "NotConfigured" 2 "NotSelectable" 1 "Selectable" 0 "Null" ;
VAL_ 936 ApaSelPpa_D_Stat 3 "NotConfigured" 2 "NotSelectable" 1 "Selectable" 0 "Null" ;
VAL_ 936 ApaSelPoa_D_Stat 3 "NotConfigured" 2 "NotSelectable" 1 "Selectable" 0 "Null" ;
VAL_ 936 ApaScan_D_Stat 3 "ParkSlotReady" 2 "ParkSlotFound" 1 "NoParkSlot" 0 "Null" ;
VAL_ 936 ApaLongCtl_D_RqDrv 7 "NotUsed3" 6 "NotUsed2" 5 "ReleaseBrake" 4 "DriveBackward" 3 "DriveForward" 2 "Stop" 1 "NoRequest" 0 "Null" ;
VAL_ 936 ApaGearShif_D_RqDrv 7 "NotUSed2" 6 "NotUsed1" 5 "ShiftToP" 4 "ShiftToN" 3 "ShiftToD" 2 "ShiftToR" 1 "NoRequest" 0 "Null" ;
VAL_ 936 ApaActvSide2_D_Stat 3 "NoSide" 2 "Right" 1 "Left" 0 "Null" ;
VAL_ 936 ApaAcsy_D_RqDrv 7 "CloseDoor" 6 "SelectSideRight" 5 "SelectSideLeft" 4 "CheckForObject" 3 "PressApaButton" 2 "SelectSide" 1 "NoRequest" 0 "Null" ;
VAL_ 936 ApaTrgtDist_D_Stat 15 "Step15" 14 "Step14" 13 "Step13" 12 "Step12" 11 "Step11" 10 "Step10" 9 "Step9" 8 "Step8" 7 "Step7" 6 "Step6" 5 "Step5" 4 "Step4" 3 "Step3" 2 "Step2" 1 "Step1" 0 "Off" ;
VAL_ 936 EPASExtAngleStatReq 1 "Request" 0 "NoRequest" ;
VAL_ 936 ExtSteeringAngleReq2 32767 "Invalid" 32766 "Unknown" ;
VAL_ 76 RstrnPsngrOn_D_Stat 15 "Faulty" 14 "NotUsed_11" 13 "NotUsed_10" 12 "ConfiguredOff" 11 "NotUsed_9" 10 "On" 9 "NotUsed_8" 8 "NotUsed_7" 7 "NotUsed_6" 6 "NotUsed_5" 5 "Off" 4 "NotUsed_4" 3 "NotUsed_3" 2 "NotUsed_2" 1 "NotUsed_1" 0 "NoAction" ;
VAL_ 76 PsngrFmidDetct_D_Actl 3 "Unknown" 2 "Empty" 1 "Occupied" 0 "Fault" ;
VAL_ 76 FirstRowBuckleMid 3 "Unknown" 2 "Unbelted" 1 "Belted" 0 "Faulty" ;
VAL_ 76 ThirdRowBucklePsngr 3 "Unknown" 2 "Unbelted" 1 "Belted" 0 "Faulty" ;
VAL_ 76 ThirdRowBuckleDriver 3 "Unknown" 2 "Unbelted" 1 "Belted" 0 "Faulty" ;
VAL_ 76 SecondRowBucklePsngr 3 "Unknown" 2 "Unbelted" 1 "Belted" 0 "Faulty" ;
VAL_ 76 SecondRowBuckleMid 3 "Unknown" 2 "Unbelted" 1 "Belted" 0 "Faulty" ;
VAL_ 76 SecondRowBuckleDriver 3 "Unknown" 2 "Unbelted" 1 "Belted" 0 "Faulty" ;
VAL_ 76 FirstRowBuckleDriver 3 "Unknown" 2 "Unbelted" 1 "Belted" 0 "Faulty" ;
VAL_ 76 RILReq 3 "Not_Used" 2 "Plant_Mode" 1 "On" 0 "Off" ;
VAL_ 76 FirstRowBucklePsngr 3 "Unknown" 2 "Unbelted" 1 "Belted" 0 "Faulty" ;
VAL_ 76 RstrnImpactEvntStatus 7 "Invalid" 6 "Not_Used_4" 5 "Threshold_2_Exceeded" 4 "Not_Used_3" 3 "Threshold_1_Exceeded" 2 "Not_Used_2" 1 "Not_Used_1" 0 "Normal" ;
VAL_ 76 PsngrFrntDetct_D_Actl 3 "Unknown" 2 "Empty" 0 "Faulty" 1 "Occupied" ;
VAL_ 76 EDRTriggerEvntSync 1 "Threshold_Exceeded" 0 "Normal" ;
VAL_ 76 PassRstrnInd_Req 3 "ABOnNotIllum_OffNotIllum" 2 "AirbagOnNot_Illum_OffIllum" 1 "AirbagOn_Illum_OffNotIllum" 0 "AirbagOn_Illum_Off_Illum" ;
VAL_ 120 BpedDrvMsgTxt_B_Dsply_UB 1 "Fresh_data" 0 "Unchanged_data" ;
VAL_ 120 BpedDrvMsgTxt_B_Dsply 1 "On" 0 "Off" ;
VAL_ 120 PassRstrnInd_Stat_UB 1 "Fresh_data" 0 "Unchanged_data" ;
VAL_ 120 PassRstrnInd_Stat 7 "Invalid" 6 "Unused_2" 5 "Unused_1" 4 "Both_Indicators_Faulted" 3 "AirbagOff_Indicator_fault" 2 "AirbagOn_Indicator_fault" 1 "Normal" 0 "Not_Supported" ;
VAL_ 120 ECMMILRequest_UB 1 "Fresh_data" 0 "Unchanged_data" ;
VAL_ 120 ECMMILRequest 3 "Not_Used" 2 "Flash" 1 "On" 0 "Off" ;
VAL_ 120 TrnIpcDsplyMde_D_Stat 3 "Reserved_Blank_No_Display" 2 "Flash" 1 "On" 0 "Blank_No_Display" ;
VAL_ 120 TrnIpcDsplyMde_D_Actl 7 "Manual_3" 6 "Manual_2" 5 "Manual_1_Low" 4 "Sport" 3 "Drive" 2 "Neutral" 1 "Reverse" 0 "Park" ;
VAL_ 120 EngSrvcRqd_B_Rq_UB 1 "Fresh_data" 0 "Unchanged_data" ;
VAL_ 120 EngSrvcRqd_B_Rq 1 "Engine_Service_Required" 0 "No_engine_service_required" ;
VAL_ 120 TrnIpcDsplyMde_D_Stat_UB 1 "Fresh_data" 0 "Unchanged_data" ;
VAL_ 120 TrnIpcDsplyMde_D_Actl_UB 1 "Fresh_data" 0 "Unchanged_data" ;
VAL_ 376 GasPrtc_D_RqDsply 7 "NotUsed_5" 6 "NotUsed_4" 5 "NotUsed_3" 4 "NotUsed_2" 3 "NotUsed_1" 2 "GpfOverLimit" 1 "GpfAtLimit" 0 "NormalOperation" ;
VAL_ 376 LnchCtlSys_D_Stat 7 "NotUsed3" 6 "NotUsed2" 5 "NotUsed1" 4 "On_LC_Unavailable_TC_On" 3 "On_LC_Unavailable" 2 "On_LC_Available" 1 "On_LC_Active" 0 "LC_OFF" ;
VAL_ 376 DynoMde_B_Cmd 1 "DynomometerMode" 0 "NormalOperation" ;
VAL_ 376 AslIconDsply_D_Rq 3 "On_Passive_Overridden" 2 "On_Active" 1 "On_Passive" 0 "Off" ;
VAL_ 376 AslChime_B_Rq 1 "Yes" 0 "No" ;
VAL_ 376 EcssLamp_D_RqDsply 3 "Not_Used" 2 "Flash" 1 "On" 0 "Off" ;
VAL_ 376 AirAmbTe_D_Qf 3 "OK" 2 "Not_Within_Specifications" 1 "No_Data_Exists" 0 "Faulty" ;
VAL_ 376 AirAmb_P_Actl 63 "Fault" 62 "NoDataExists" ;
VAL_ 516 EngAoutNActl_D_QF 3 "OK" 2 "Not_Within_Specifications" 1 "No_Data_Exists" 0 "Faulty" ;
VAL_ 516 ApedPos_PcRate_ActlArb 255 "Fault" 254 "Unknown" ;
VAL_ 516 ApedPosPcActl_D_Qf 3 "OK" 2 "Not_Within_Specifications" 1 "No_Data_Exists" 0 "Faulty" ;
